VERSION "HNNBNNNYNNNNNNNNNNNNNNNNNNNNNNNNNNNNNNNNNN/4/%%%/4/'%**4NNN///"

NS_ :

BS_:

BU_: AFS Airbag Allrad BAP_Tester BMS_Hybrid Bremse_MK60EC Bremse_MK70MABS Bremse_TRW_EBC450M Bremse_TRW_ESP Daempfer EPB_TRW EPB_TRW_VW411CS FLA Gateway_PQ35 Gateway_Zusatz_EGolf Getriebe_AG6 Getriebe_DQ Getriebe_DQ_Hyb Getriebe_Sele Gurtmikro_PQ35 HCA Ladegeraet_EGolf LEH_Hybrid LH_EPS_APA LH_EPS_ZF_2G LH_EPS_ZF_3G LPG_Interface_Box LWR LWS Magne_Ride Motor_Diesel Motor_EGolf Motor_Hybrid Motor_Otto PDC_PLA Quersperre_VAQ RKA_Plus SAK Waehlhebel Waehlhebel_Sele

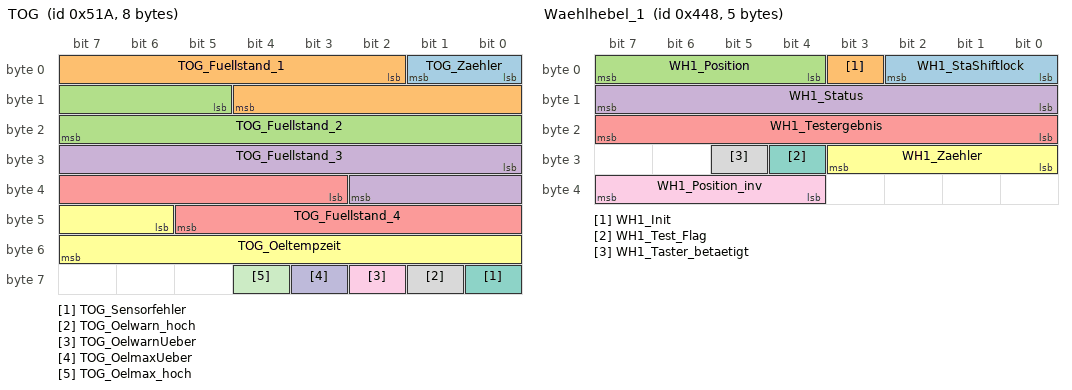
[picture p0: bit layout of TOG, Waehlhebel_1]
BO_ 1306 TOG: 8 Gateway_PQ35
 SG_ TOG_Zaehler : 0|2@1+ (1,0) [0|3] ""  Motor_Diesel,Motor_Hybrid,Motor_Otto
 SG_ TOG_Fuellstand_1 : 2|11@1+ (0.5,100) [101|1123] "Unit_MilliSecon"  Motor_Diesel,Motor_Hybrid,Motor_Otto
 SG_ TOG_Fuellstand_2 : 13|11@1+ (0.5,100) [101|1123] "Unit_MilliSecon"  Motor_Diesel,Motor_Hybrid,Motor_Otto
 SG_ TOG_Fuellstand_3 : 24|11@1+ (0.5,100) [101|1123] "Unit_MilliSecon"  Motor_Diesel,Motor_Hybrid,Motor_Otto
 SG_ TOG_Fuellstand_4 : 35|11@1+ (0.5,100) [101|1123] "Unit_MilliSecon"  Motor_Diesel,Motor_Hybrid,Motor_Otto
 SG_ TOG_Oeltempzeit : 46|10@1+ (0.125,0) [0.25|127] "Unit_MilliSecon"  Motor_Diesel,Motor_Hybrid,Motor_Otto
 SG_ TOG_Sensorfehler : 56|1@1+ (1,0) [0|1] ""  Motor_Diesel,Motor_Hybrid,Motor_Otto
 SG_ TOG_Oelwarn_hoch : 57|1@1+ (1,0) [0|1] ""  Motor_Diesel,Motor_Hybrid,Motor_Otto
 SG_ TOG_OelwarnUeber : 58|1@1+ (1,0) [0|1] "" Vector__XXX
 SG_ TOG_OelmaxUeber : 59|1@1+ (1,0) [0|1] "" Vector__XXX
 SG_ TOG_Oelmax_hoch : 60|1@1+ (1,0) [0|1] "" Vector__XXX

BO_ 1936 mTP_Dyn_ABS_1: 8 Gateway_PQ35
 SG_ TPDyn_ABS_1 : 0|64@1+ (1,0) [0|1.84467440737096E+019] ""  Bremse_MK60EC,Bremse_MK70MABS,Bremse_TRW_EBC450M,Bremse_TRW_ESP

BO_ 1937 mTP_Dyn_ABS_2: 8 Gateway_PQ35
 SG_ TPDyn_ABS_2 : 0|64@1+ (1,0) [0|1.84467440737096E+019] "" Vector__XXX

BO_ 1904 mTP_Dyn_ADR_1: 8 Gateway_PQ35
 SG_ TPDyn_ADR_1 : 0|64@1+ (1,0) [0|1.84467440737096E+019] "" Vector__XXX

BO_ 1896 mTP_Dyn_Airbag_1: 8 Gateway_PQ35
 SG_ TPDyn_Airbag_1 : 0|64@1+ (1,0) [0|1.84467440737096E+019] ""  Airbag

BO_ 1892 mTP_Dyn_Allrad_1: 8 Gateway_PQ35
 SG_ TPDyn_Allrad_1 : 0|64@1+ (1,0) [0|1.84467440737096E+019] ""  Allrad

BO_ 1906 mTP_Dyn_Daempfer_1: 8 Gateway_PQ35
 SG_ TPDyn_Daempfer_1 : 0|64@1+ (1,0) [0|1.84467440737096E+019] ""  Daempfer,Magne_Ride

BO_ 768 mTP_Dyn_Diag_1_1: 8 AFS
 SG_ TPDyn_Diag_1_1 : 0|64@1+ (1,0) [0|1.84467440737096E+019] ""  Gateway_PQ35

BO_ 769 mTP_Dyn_Diag_1_2: 8 AFS
 SG_ TPDyn_Diag_1_2 : 0|64@1+ (1,0) [0|1.84467440737096E+019] ""  Gateway_PQ35

BO_ 770 mTP_Dyn_Diag_1_3: 8 AFS
 SG_ TPDyn_Diag_1_3 : 0|64@1+ (1,0) [0|1.84467440737096E+019] ""  Gateway_PQ35

BO_ 771 mTP_Dyn_Diag_1_4: 8 AFS
 SG_ TPDyn_Diag_1_4 : 0|64@1+ (1,0) [0|1.84467440737096E+019] ""  Gateway_PQ35

BO_ 772 mTP_Dyn_Diag_1_5: 8 AFS
 SG_ TPDyn_Diag_1_5 : 0|64@1+ (1,0) [0|1.84467440737096E+019] ""  Gateway_PQ35

BO_ 773 mTP_Dyn_Diag_1_6: 8 AFS
 SG_ TPDyn_Diag_1_6 : 0|64@1+ (1,0) [0|1.84467440737096E+019] ""  Gateway_PQ35

BO_ 774 mTP_Dyn_Diag_1_7: 8 AFS
 SG_ TPDyn_Diag_1_7 : 0|64@1+ (1,0) [0|1.84467440737096E+019] ""  Gateway_PQ35

BO_ 775 mTP_Dyn_Diag_1_8: 8 AFS
 SG_ TPDyn_Diag_1_8 : 0|64@1+ (1,0) [0|1.84467440737096E+019] ""  Gateway_PQ35

BO_ 1940 mTP_Dyn_EPB_1: 8 Gateway_PQ35
 SG_ TPDyn_EPB_1 : 0|64@1+ (1,0) [0|1.84467440737096E+019] ""  EPB_TRW

BO_ 1864 mTP_Dyn_FLA_1: 8 Gateway_PQ35
 SG_ TPDyn_FLA_1 : 0|64@1+ (1,0) [0|1.84467440737096E+019] ""  FLA

BO_ 1888 mTP_Dyn_Getriebe_1: 8 Gateway_PQ35
 SG_ TPDyn_Getriebe_1 : 0|64@1+ (1,0) [0|1.84467440737096E+019] ""  Getriebe_AG6,Getriebe_DQ,Getriebe_DQ_Hyb,Getriebe_Sele

BO_ 1889 mTP_Dyn_Getriebe_2: 8 Gateway_PQ35
 SG_ TPDyn_Getriebe_2 : 0|64@1+ (1,0) [0|1.84467440737096E+019] ""  Getriebe_AG6,Getriebe_DQ,Getriebe_DQ_Hyb,Getriebe_Sele

BO_ 1956 mTP_Dyn_LDW_1: 8 Gateway_PQ35
 SG_ TPDyn_LDW_1 : 0|64@1+ (1,0) [0|1.84467440737096E+019] "" Vector__XXX

BO_ 1957 mTP_Dyn_LDW_2: 8 Gateway_PQ35
 SG_ TPDyn_LDW_2 : 0|64@1+ (1,0) [0|1.84467440737096E+019] ""  HCA

BO_ 1960 mTP_Dyn_Lenkhilfe_1: 8 Gateway_PQ35
 SG_ TPDyn_Lenkhilfe_1 : 0|64@1+ (1,0) [0|1.84467440737096E+019] ""  LH_EPS_APA,LH_EPS_ZF_2G

BO_ 1961 mTP_Dyn_Lenkhilfe_2: 8 Gateway_PQ35
 SG_ TPDyn_Lenkhilfe_2 : 0|64@1+ (1,0) [0|1.84467440737096E+019] ""  LH_EPS_APA,LH_EPS_ZF_2G

BO_ 1924 mTP_Dyn_LWR_1: 8 Gateway_PQ35
 SG_ TPDyn_Dyn_LWR_1 : 0|64@1+ (1,0) [0|1.84467440737096E+019] ""  AFS,LWR

BO_ 1925 mTP_Dyn_LWR_2: 8 Gateway_PQ35
 SG_ TPDyn_Dyn_LWR_2 : 0|64@1+ (1,0) [0|1.84467440737096E+019] ""  AFS,LWR

BO_ 1952 mTP_Dyn_LWS: 8 Gateway_PQ35
 SG_ TPDyn_LWS : 0|64@1+ (1,0) [0|1.84467440737096E+019] ""  LWS

BO_ 1856 mTP_Dyn_Motor_1: 8 Gateway_PQ35
 SG_ TPDyn_Motor_1 : 0|64@1+ (1,0) [0|1.84467440737096E+019] ""  Motor_Diesel,Motor_Hybrid,Motor_Otto

BO_ 1857 mTP_Dyn_Motor_2: 8 Gateway_PQ35
 SG_ TPDyn_Motor_2 : 0|64@1+ (1,0) [0|1.84467440737096E+019] ""  Motor_Diesel,Motor_Hybrid,Motor_Otto

BO_ 1858 mTP_Dyn_Motor_3: 8 Gateway_PQ35
 SG_ TPDyn_Motor_3 : 0|64@1+ (1,0) [0|1.84467440737096E+019] ""  Motor_Diesel,Motor_Hybrid,Motor_Otto

BO_ 1859 mTP_Dyn_Motor_4: 8 Gateway_PQ35
 SG_ TPDyn_Motor_4 : 0|64@1+ (1,0) [0|1.84467440737096E+019] ""  Motor_Diesel,Motor_Hybrid,Motor_Otto

BO_ 1978 mTP_Dyn_PLA_PDC: 8 Gateway_PQ35
 SG_ TPDyn_PLA_PDC : 0|64@1+ (1,0) [0|1.84467440737096E+019] ""  PDC_PLA

BO_ 1880 mTP_Dyn_Quersperre_1: 8 Vector__XXX
 SG_ TPDyn_Quersperre_1 : 0|64@1+ (1,0) [0|1.84467440737096E+019] ""  Quersperre_VAQ

BO_ 1881 mTP_Dyn_Quersperre_2: 8 Gateway_PQ35
 SG_ TPDyn_Quersperre_2 : 0|64@1+ (1,0) [0|1.84467440737096E+019] ""  Quersperre_VAQ

BO_ 1875 mTP_Dyn_RKA_Plus_2: 8 Gateway_PQ35
 SG_ TPDyn_RKA_Plus_2 : 0|64@1+ (1,0) [0|1.84467440737096E+019] ""  RKA_Plus

BO_ 515 mTP_Er_ABS: 7 Bremse_MK60EC
 SG_ ABS_TP_Er : 0|56@1+ (1,0) [0|7.20575940379279E+016] ""  Gateway_PQ35

BO_ 523 mTP_Er_ADR: 7 Vector__XXX
 SG_ ADR_TP_Er : 0|56@1+ (1,0) [0|7.20575940379279E+016] ""  Gateway_PQ35

BO_ 517 mTP_Er_Airbag: 7 Airbag
 SG_ Airbag_TP_Er : 0|56@1+ (1,0) [0|7.20575940379279E+016] ""  Gateway_PQ35

BO_ 522 mTP_Er_Allrad: 7 Allrad
 SG_ Allrad_TP_Er : 0|56@1+ (1,0) [0|7.20575940379279E+016] ""  Gateway_PQ35

BO_ 524 mTP_Er_Daempfer: 7 Daempfer
 SG_ Daempfer_TP_Er : 0|56@1+ (1,0) [0|7.20575940379279E+016] ""  Gateway_PQ35

BO_ 537 mTP_Er_EPB: 7 EPB_TRW
 SG_ EPB_TP_Er : 0|56@1+ (1,0) [0|7.20575940379279E+016] ""  Gateway_PQ35

BO_ 534 mTP_Er_FLA: 7 FLA
 SG_ FLA_TP_Er : 0|56@1+ (1,0) [0|7.20575940379279E+016] ""  Gateway_PQ35

BO_ 514 mTP_Er_Getriebe: 7 Getriebe_AG6
 SG_ Getriebe_TP_Er : 0|56@1+ (1,0) [0|7.20575940379279E+016] ""  Gateway_PQ35

BO_ 538 mTP_Er_LDW: 7 HCA
 SG_ LDW_TP_Er : 0|56@1+ (1,0) [0|7.20575940379279E+016] ""  Gateway_PQ35

BO_ 521 mTP_Er_Lenkhilfe: 7 LH_EPS_APA
 SG_ Lenkhilfe_TP_Er : 0|56@1+ (1,0) [0|7.20575940379279E+016] ""  Gateway_PQ35

BO_ 518 mTP_Er_LWR: 7 AFS
 SG_ Dyn_LWR_TP_Er : 0|56@1+ (1,0) [0|7.20575940379279E+016] ""  Gateway_PQ35

BO_ 531 mTP_Er_LWS: 7 LWS
 SG_ LWS_TP_Er : 0|56@1+ (1,0) [0|7.20575940379279E+016] ""  Gateway_PQ35

BO_ 513 mTP_Er_Motor: 7 Motor_Diesel
 SG_ Motor_TP_Er : 0|56@1+ (1,0) [0|7.20575940379279E+016] ""  Gateway_PQ35

BO_ 541 mTP_Er_PLA_PDC: 7 PDC_PLA
 SG_ PLA_PDC_TP_Er : 0|56@1+ (1,0) [0|7.20575940379279E+016] ""  Gateway_PQ35

BO_ 536 mTP_Er_Quersperre: 7 Quersperre_VAQ
 SG_ Quersperre_TP_Er : 0|56@1+ (1,0) [0|7.20575940379279E+016] ""  Gateway_PQ35

BO_ 520 mTP_Er_RKA_Plus: 7 RKA_Plus
 SG_ RKA_Plus_TP_Er : 0|56@1+ (1,0) [0|7.20575940379279E+016] ""  Gateway_PQ35

BO_ 512 mTP_Er_Tester: 7 Gateway_PQ35
 SG_ Tester_TP_Er : 0|56@1+ (1,0) [0|7.20575940379279E+016] ""  AFS,Airbag,Allrad,Bremse_MK60EC,Bremse_MK70MABS,Bremse_TRW_EBC450M,Bremse_TRW_ESP,Daempfer,EPB_TRW,FLA,Getriebe_AG6,Getriebe_DQ,Getriebe_DQ_Hyb,Getriebe_Sele,HCA,LH_EPS_APA,LH_EPS_ZF_2G,LWR,LWS,Magne_Ride,Motor_Diesel,Motor_Hybrid,Motor_Otto,PDC_PLA,Quersperre_VAQ,RKA_Plus

BO_ 1096 Waehlhebel_1: 5 Waehlhebel
 SG_ WH1_StaShiftlock : 0|3@1+ (1,0) [0|7] ""  Getriebe_DQ,Getriebe_DQ_Hyb,Motor_EGolf
 SG_ WH1_Init : 3|1@1+ (1,0) [0|1] ""  Getriebe_DQ,Getriebe_DQ_Hyb,Motor_EGolf
 SG_ WH1_Position : 4|4@1+ (1,0) [0|15] ""  Getriebe_DQ,Getriebe_DQ_Hyb,Motor_EGolf
 SG_ WH1_Status : 8|8@1+ (1,0) [0|255] ""  Getriebe_DQ,Getriebe_DQ_Hyb,Motor_EGolf
 SG_ WH1_Testergebnis : 16|8@1+ (1,0) [0|255] ""  Getriebe_DQ,Getriebe_DQ_Hyb,Motor_EGolf
 SG_ WH1_Zaehler : 24|4@1+ (1,0) [0|15] ""  Getriebe_DQ,Getriebe_DQ_Hyb,Motor_EGolf
 SG_ WH1_Test_Flag : 28|1@1+ (1,0) [0|1] ""  Getriebe_DQ,Getriebe_DQ_Hyb,Motor_EGolf
 SG_ WH1_Taster_betaetigt : 29|1@1+ (1,0) [0|1] ""  Motor_EGolf
 SG_ WH1_Position_inv : 36|4@1+ (1,0) [0|15] ""  Getriebe_DQ,Getriebe_DQ_Hyb,Motor_EGolf

BO_ 1102 Waehlhebel_2: 5 Waehlhebel_Sele
 SG_ WH2_Checksumme : 0|8@1+ (1,0) [0|255] ""  Getriebe_Sele
 SG_ WH2_Zaehler : 8|4@1+ (1,0) [0|15] ""  Getriebe_Sele
 SG_ WH2_Init : 12|1@1+ (1,0) [0|1] ""  Getriebe_Sele
 SG_ WH2_Test_Flag : 13|1@1+ (1,0) [0|1] ""  Getriebe_Sele
 SG_ WH2_Sport : 14|1@1+ (1,0) [0|1] ""  Getriebe_Sele
 SG_ WH2_Winter : 15|1@1+ (1,0) [0|1] ""  Getriebe_Sele
 SG_ WH2_Position : 16|3@1+ (1,0) [0|7] ""  Getriebe_Sele
 SG_ WH2_Ruhestromfehler : 23|1@1+ (1,0) [0|1] ""  Getriebe_Sele
 SG_ WH2_Sensorarray_Einfachfehler : 24|1@1+ (1,0) [0|1] ""  Getriebe_Sele
 SG_ WH2_Sensorarray_Mehrfachfehler : 25|1@1+ (1,0) [0|1] ""  Getriebe_Sele
 SG_ WH2_Fehler_Sporttaster : 26|1@1+ (1,0) [0|1] ""  Getriebe_Sele
 SG_ WH2_Fehler_Fahrstufenanzeige : 27|1@1+ (1,0) [0|1] ""  Getriebe_Sele
 SG_ WH2_Fehler_Spannungsversorgung : 28|1@1+ (1,0) [0|1] ""  Getriebe_Sele
 SG_ WH2_Timeout_Kombi_2 : 29|1@1+ (1,0) [0|1] ""  Getriebe_Sele
 SG_ WH2_Timeout_Getriebe_5 : 30|1@1+ (1,0) [0|1] ""  Getriebe_Sele
 SG_ WH2_Timeout_Gate_Komf_1 : 31|1@1+ (1,0) [0|1] ""  Getriebe_Sele
 SG_ WH2_Testergebnis : 32|8@1+ (1,0) [0|255] ""  Getriebe_Sele

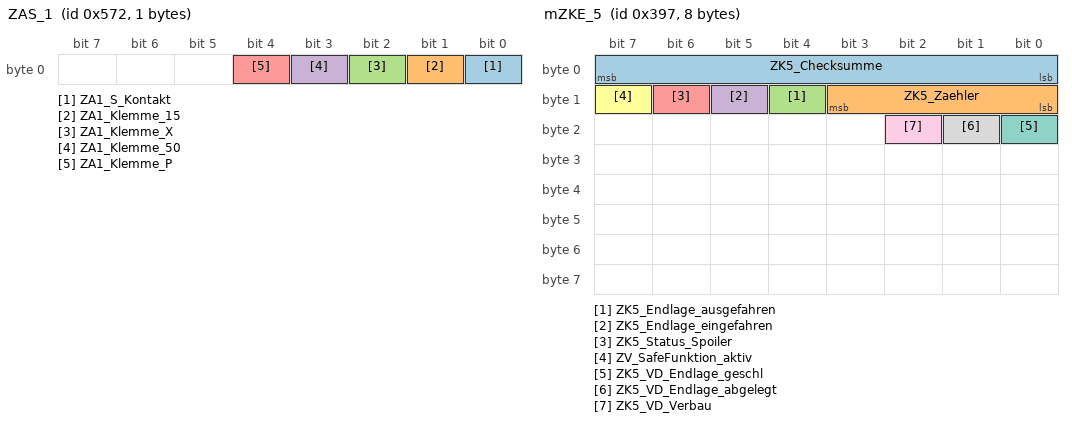
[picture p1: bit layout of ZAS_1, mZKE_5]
BO_ 1394 ZAS_1: 1 Gateway_PQ35
 SG_ ZA1_S_Kontakt : 0|1@1+ (1,0) [0|1] "" Vector__XXX
 SG_ ZA1_Klemme_15 : 1|1@1+ (1,0) [0|1] ""  Motor_Hybrid,Motor_Otto,PDC_PLA
 SG_ ZA1_Klemme_X : 2|1@1+ (1,0) [0|1] ""  Motor_Diesel,PDC_PLA
 SG_ ZA1_Klemme_50 : 3|1@1+ (1,0) [0|1] ""  Motor_Diesel,Motor_Hybrid,Motor_Otto
 SG_ ZA1_Klemme_P : 4|1@1+ (1,0) [0|1] "" Vector__XXX

BO_ 919 mZKE_5: 8 Gateway_PQ35
 SG_ ZK5_Checksumme : 0|8@1+ (1,0) [0|255] ""  Bremse_MK60EC
 SG_ ZK5_Zaehler : 8|4@1+ (1,0) [0|15] ""  Bremse_MK60EC
 SG_ ZK5_Endlage_ausgefahren : 12|1@1+ (1,0) [0|1] ""  Bremse_MK60EC
 SG_ ZK5_Endlage_eingefahren : 13|1@1+ (1,0) [0|1] ""  Bremse_MK60EC
 SG_ ZK5_Status_Spoiler : 14|1@1+ (1,0) [0|1] ""  Bremse_MK60EC
 SG_ ZV_SafeFunktion_aktiv : 15|1@1+ (1,0) [0|1] "" Vector__XXX
 SG_ ZK5_VD_Endlage_geschl : 16|1@1+ (1,0) [0|1] ""  Bremse_MK60EC,PDC_PLA
 SG_ ZK5_VD_Endlage_abgelegt : 17|1@1+ (1,0) [0|1] ""  Bremse_MK60EC,PDC_PLA
 SG_ ZK5_VD_Verbau : 18|1@1+ (1,0) [0|1] ""  Bremse_MK60EC,PDC_PLA

BO_ 1827 NMH_ABS: 7 Bremse_MK60EC
 SG_ NMH_ABS_Start_1 : 0|1@1+ (1,0) [0|1] ""  BMS_Hybrid,Bremse_MK60EC,Bremse_MK70MABS,Bremse_TRW_EBC450M,Bremse_TRW_ESP,EPB_TRW_VW411CS,Gateway_PQ35,Ladegeraet_EGolf,LEH_Hybrid,Motor_Diesel,Motor_EGolf,Motor_Hybrid,Motor_Otto
 SG_ NMH_ABS_Start_2 : 1|1@1+ (1,0) [0|1] "" Vector__XXX
 SG_ NMH_ABS_Normal_Mode_1 : 2|1@1+ (1,0) [0|1] "" Vector__XXX
 SG_ NMH_ABS_Normal_Mode_2 : 3|1@1+ (1,0) [0|1] "" Vector__XXX
 SG_ NMH_ABS_Car_WakeUp : 6|1@1+ (1,0) [0|1] "" Vector__XXX
 SG_ NMH_ABS_Per_WakeUp : 8|5@1+ (1,0) [0|31] "" Vector__XXX
 SG_ NMH_ABS_Fkt_WakeUp : 13|3@1+ (1,0) [0|7] "" Vector__XXX
 SG_ NMH_ABS_NM_aktiv_Klemme_15 : 16|1@1+ (1,0) [0|1] "" Vector__XXX
 SG_ NMH_ABS_NM_aktiv_Diagnose : 17|1@1+ (1,0) [0|1] "" Vector__XXX
 SG_ NMH_ABS_NM_aktiv_Start : 18|1@1+ (1,0) [0|1] "" Vector__XXX
 SG_ NMH_ABS_NL_aktiv_4 : 19|1@1+ (1,0) [0|1] "" Vector__XXX
 SG_ NMH_ABS_NL_aktiv_5 : 20|1@1+ (1,0) [0|1] "" Vector__XXX
 SG_ NMH_ABS_NL_aktiv_6 : 21|1@1+ (1,0) [0|1] "" Vector__XXX
 SG_ NMH_ABS_NL_aktiv_7 : 22|1@1+ (1,0) [0|1] "" Vector__XXX
 SG_ NMH_ABS_NL_aktiv_8 : 23|1@1+ (1,0) [0|1] "" Vector__XXX
 SG_ NMH_ABS_NL_0 : 24|1@1+ (1,0) [0|1] "" Vector__XXX
 SG_ NMH_ABS_NL_1 : 25|1@1+ (1,0) [0|1] "" Vector__XXX
 SG_ NMH_ABS_NL_2 : 26|1@1+ (1,0) [0|1] "" Vector__XXX
 SG_ NMH_ABS_NL_3 : 27|1@1+ (1,0) [0|1] "" Vector__XXX
 SG_ NMH_ABS_NL_4 : 28|1@1+ (1,0) [0|1] "" Vector__XXX
 SG_ NMH_ABS_NL_5 : 29|1@1+ (1,0) [0|1] "" Vector__XXX
 SG_ NMH_ABS_NL_6 : 30|1@1+ (1,0) [0|1] "" Vector__XXX
 SG_ NMH_ABS_NL_7 : 31|1@1+ (1,0) [0|1] "" Vector__XXX
 SG_ NMH_ABS_TimeOut_Fehler : 33|1@1+ (1,0) [0|1] "" Vector__XXX
 SG_ NMH_ABS_CAN_Diag_deaktiv : 34|1@1+ (1,0) [0|1] "" Vector__XXX
 SG_ NMH_ABS_KompSchutz : 35|1@1+ (1,0) [0|1] "" Vector__XXX
 SG_ NMH_ABS_Mute_Mode : 36|1@1+ (1,0) [0|1] "" Vector__XXX
 SG_ NMH_ABS_Transport_Mode : 37|1@1+ (1,0) [0|1] "" Vector__XXX
 SG_ NMH_ABS_Abschaltstufe_aktiv : 38|1@1+ (1,0) [0|1] "" Vector__XXX
 SG_ NMH_ABS_Eindraht_Fehler : 39|1@1+ (1,0) [0|1] "" Vector__XXX

BO_ 1838 NMH_BMS: 7 BMS_Hybrid
 SG_ NMH_BMS_Start_1 : 0|1@1+ (1,0) [0|1] ""  BMS_Hybrid,Bremse_MK60EC,Bremse_MK70MABS,Bremse_TRW_EBC450M,Bremse_TRW_ESP,EPB_TRW_VW411CS,Gateway_PQ35,Ladegeraet_EGolf,LEH_Hybrid,Motor_Diesel,Motor_EGolf,Motor_Hybrid,Motor_Otto
 SG_ NMH_BMS_Start_2 : 1|1@1+ (1,0) [0|1] "" Vector__XXX
 SG_ NMH_BMS_Normal_Mode_1 : 2|1@1+ (1,0) [0|1] "" Vector__XXX
 SG_ NMH_BMS_Normal_Mode_2 : 3|1@1+ (1,0) [0|1] "" Vector__XXX
 SG_ NMH_BMS_Car_WakeUp : 6|1@1+ (1,0) [0|1] "" Vector__XXX
 SG_ NMH_BMS_Per_WakeUp : 8|5@1+ (1,0) [0|31] "" Vector__XXX
 SG_ NMH_BMS_Fkt_WakeUp : 13|3@1+ (1,0) [0|7] "" Vector__XXX
 SG_ NMH_BMS_NM_aktiv_Klemme_15 : 16|1@1+ (1,0) [0|1] "" Vector__XXX
 SG_ NMH_BMS_NM_aktiv_Diagnose : 17|1@1+ (1,0) [0|1] "" Vector__XXX
 SG_ NMH_BMS_NM_aktiv_Start : 18|1@1+ (1,0) [0|1] "" Vector__XXX
 SG_ NMH_BMS_NL_aktiv_4 : 19|1@1+ (1,0) [0|1] "" Vector__XXX
 SG_ NMH_BMS_NL_aktiv_5 : 20|1@1+ (1,0) [0|1] "" Vector__XXX
 SG_ NMH_BMS_NL_aktiv_6 : 21|1@1+ (1,0) [0|1] "" Vector__XXX
 SG_ NMH_BMS_NL_aktiv_7 : 22|1@1+ (1,0) [0|1] "" Vector__XXX
 SG_ NMH_BMS_NL_aktiv_8 : 23|1@1+ (1,0) [0|1] "" Vector__XXX
 SG_ NMH_BMS_NL_0 : 24|1@1+ (1,0) [0|1] "" Vector__XXX
 SG_ NMH_BMS_NL_1 : 25|1@1+ (1,0) [0|1] "" Vector__XXX
 SG_ NMH_BMS_NL_2 : 26|1@1+ (1,0) [0|1] "" Vector__XXX
 SG_ NMH_BMS_NL_3 : 27|1@1+ (1,0) [0|1] "" Vector__XXX
 SG_ NMH_BMS_NL_4 : 28|1@1+ (1,0) [0|1] "" Vector__XXX
 SG_ NMH_BMS_NL_5 : 29|1@1+ (1,0) [0|1] "" Vector__XXX
 SG_ NMH_BMS_NL_6 : 30|1@1+ (1,0) [0|1] "" Vector__XXX
 SG_ NMH_BMS_NL_7 : 31|1@1+ (1,0) [0|1] "" Vector__XXX
 SG_ NMH_BMS_TimeOut_Fehler : 33|1@1+ (1,0) [0|1] "" Vector__XXX
 SG_ NMH_BMS_CAN_Diag_deaktiv : 34|1@1+ (1,0) [0|1] "" Vector__XXX
 SG_ NMH_BMS_KompSchutz : 35|1@1+ (1,0) [0|1] "" Vector__XXX
 SG_ NMH_BMS_Mute_Mode : 36|1@1+ (1,0) [0|1] "" Vector__XXX
 SG_ NMH_BMS_Transport_Mode : 37|1@1+ (1,0) [0|1] "" Vector__XXX
 SG_ NMH_BMS_Abschaltstufe_aktiv : 38|1@1+ (1,0) [0|1] "" Vector__XXX
 SG_ NMH_BMS_Eindraht_Fehler : 39|1@1+ (1,0) [0|1] "" Vector__XXX

BO_ 1839 NMH_EM: 7 LEH_Hybrid
 SG_ NMH_EM_Start_1 : 0|1@1+ (1,0) [0|1] ""  BMS_Hybrid,Bremse_MK60EC,Bremse_MK70MABS,Bremse_TRW_EBC450M,Bremse_TRW_ESP,EPB_TRW_VW411CS,Gateway_PQ35,Ladegeraet_EGolf,LEH_Hybrid,Motor_Diesel,Motor_EGolf,Motor_Hybrid,Motor_Otto
 SG_ NMH_EM_Start_2 : 1|1@1+ (1,0) [0|1] "" Vector__XXX
 SG_ NMH_EM_Normal_Mode_1 : 2|1@1+ (1,0) [0|1] "" Vector__XXX
 SG_ NMH_EM_Normal_Mode_2 : 3|1@1+ (1,0) [0|1] "" Vector__XXX
 SG_ NMH_EM_Car_WakeUp : 6|1@1+ (1,0) [0|1] "" Vector__XXX
 SG_ NMH_EM_Per_WakeUp : 8|5@1+ (1,0) [0|31] "" Vector__XXX
 SG_ NMH_EM_Fkt_WakeUp : 13|3@1+ (1,0) [0|7] "" Vector__XXX
 SG_ NMH_EM_NM_aktiv_Klemme_15 : 16|1@1+ (1,0) [0|1] "" Vector__XXX
 SG_ NMH_EM_NM_aktiv_Diagnose : 17|1@1+ (1,0) [0|1] "" Vector__XXX
 SG_ NMH_EM_NM_aktiv_Start : 18|1@1+ (1,0) [0|1] "" Vector__XXX
 SG_ NMH_EM_NL_aktiv_4 : 19|1@1+ (1,0) [0|1] "" Vector__XXX
 SG_ NMH_EM_NL_aktiv_5 : 20|1@1+ (1,0) [0|1] "" Vector__XXX
 SG_ NMH_EM_NL_aktiv_6 : 21|1@1+ (1,0) [0|1] "" Vector__XXX
 SG_ NMH_EM_NL_aktiv_7 : 22|1@1+ (1,0) [0|1] "" Vector__XXX
 SG_ NMH_EM_NL_aktiv_8 : 23|1@1+ (1,0) [0|1] "" Vector__XXX
 SG_ NMH_EM_NL_0 : 24|1@1+ (1,0) [0|1] "" Vector__XXX
 SG_ NMH_EM_NL_1 : 25|1@1+ (1,0) [0|1] "" Vector__XXX
 SG_ NMH_EM_NL_2 : 26|1@1+ (1,0) [0|1] "" Vector__XXX
 SG_ NMH_EM_NL_3 : 27|1@1+ (1,0) [0|1] "" Vector__XXX
 SG_ NMH_EM_NL_4 : 28|1@1+ (1,0) [0|1] "" Vector__XXX
 SG_ NMH_EM_NL_5 : 29|1@1+ (1,0) [0|1] "" Vector__XXX
 SG_ NMH_EM_NL_6 : 30|1@1+ (1,0) [0|1] "" Vector__XXX
 SG_ NMH_EM_NL_7 : 31|1@1+ (1,0) [0|1] "" Vector__XXX
 SG_ NMH_EM_TimeOut_Fehler : 33|1@1+ (1,0) [0|1] "" Vector__XXX
 SG_ NMH_EM_CAN_Diag_deaktiv : 34|1@1+ (1,0) [0|1] "" Vector__XXX
 SG_ NMH_EM_KompSchutz : 35|1@1+ (1,0) [0|1] "" Vector__XXX
 SG_ NMH_EM_Mute_Mode : 36|1@1+ (1,0) [0|1] "" Vector__XXX
 SG_ NMH_EM_Transport_Mode : 37|1@1+ (1,0) [0|1] "" Vector__XXX
 SG_ NMH_EM_Abschaltstufe_aktiv : 38|1@1+ (1,0) [0|1] "" Vector__XXX
 SG_ NMH_EM_Eindraht_Fehler : 39|1@1+ (1,0) [0|1] "" Vector__XXX

BO_ 1849 NMH_EPB: 7 EPB_TRW_VW411CS
 SG_ NMH_EPB_Start_1 : 0|1@1+ (1,0) [0|1] ""  BMS_Hybrid,Bremse_MK60EC,Bremse_MK70MABS,Bremse_TRW_EBC450M,Bremse_TRW_ESP,EPB_TRW_VW411CS,Gateway_PQ35,Ladegeraet_EGolf,LEH_Hybrid,Motor_Diesel,Motor_EGolf,Motor_Hybrid,Motor_Otto
 SG_ NMH_EPB_Start_2 : 1|1@1+ (1,0) [0|1] "" Vector__XXX
 SG_ NMH_EPB_Normal_Mode_1 : 2|1@1+ (1,0) [0|1] "" Vector__XXX
 SG_ NMH_EPB_Normal_Mode_2 : 3|1@1+ (1,0) [0|1] "" Vector__XXX
 SG_ NMH_EPB_Car_WakeUp : 6|1@1+ (1,0) [0|1] "" Vector__XXX
 SG_ NMH_EPB_Per_WakeUp : 8|5@1+ (1,0) [0|31] "" Vector__XXX
 SG_ NMH_EPB_Fkt_WakeUp : 13|3@1+ (1,0) [0|7] "" Vector__XXX
 SG_ NMH_EPB_NM_aktiv_Klemme_15 : 16|1@1+ (1,0) [0|1] "" Vector__XXX
 SG_ NMH_EPB_NM_aktiv_Diagnose : 17|1@1+ (1,0) [0|1] "" Vector__XXX
 SG_ NMH_EPB_NM_aktiv_Start : 18|1@1+ (1,0) [0|1] "" Vector__XXX
 SG_ NMH_EPB_NL_aktiv_4 : 19|1@1+ (1,0) [0|1] "" Vector__XXX
 SG_ NMH_EPB_NL_aktiv_5 : 20|1@1+ (1,0) [0|1] "" Vector__XXX
 SG_ NMH_EPB_NL_aktiv_6 : 21|1@1+ (1,0) [0|1] "" Vector__XXX
 SG_ NMH_EPB_NL_aktiv_7 : 22|1@1+ (1,0) [0|1] "" Vector__XXX
 SG_ NMH_EPB_NL_aktiv_8 : 23|1@1+ (1,0) [0|1] "" Vector__XXX
 SG_ NMH_EPB_NL_0 : 24|1@1+ (1,0) [0|1] "" Vector__XXX
 SG_ NMH_EPB_NL_1 : 25|1@1+ (1,0) [0|1] "" Vector__XXX
 SG_ NMH_EPB_NL_2 : 26|1@1+ (1,0) [0|1] "" Vector__XXX
 SG_ NMH_EPB_NL_3 : 27|1@1+ (1,0) [0|1] "" Vector__XXX
 SG_ NMH_EPB_NL_4 : 28|1@1+ (1,0) [0|1] "" Vector__XXX
 SG_ NMH_EPB_NL_5 : 29|1@1+ (1,0) [0|1] "" Vector__XXX
 SG_ NMH_EPB_NL_6 : 30|1@1+ (1,0) [0|1] "" Vector__XXX
 SG_ NMH_EPB_NL_7 : 31|1@1+ (1,0) [0|1] "" Vector__XXX
 SG_ NMH_EPB_TimeOut_Fehler : 33|1@1+ (1,0) [0|1] "" Vector__XXX
 SG_ NMH_EPB_CAN_Diag_deaktiv : 34|1@1+ (1,0) [0|1] "" Vector__XXX
 SG_ NMH_EPB_KompSchutz : 35|1@1+ (1,0) [0|1] "" Vector__XXX
 SG_ NMH_EPB_Mute_Mode : 36|1@1+ (1,0) [0|1] "" Vector__XXX
 SG_ NMH_EPB_Transport_Mode : 37|1@1+ (1,0) [0|1] "" Vector__XXX
 SG_ NMH_EPB_Abschaltstufe_aktiv : 38|1@1+ (1,0) [0|1] "" Vector__XXX
 SG_ NMH_EPB_Eindraht_Fehler : 39|1@1+ (1,0) [0|1] "" Vector__XXX

BO_ 1824 NMH_Gateway: 7 Gateway_PQ35
 SG_ NMH_GW_Start_1 : 0|1@1+ (1,0) [0|1] ""  BMS_Hybrid,Bremse_MK60EC,Bremse_MK70MABS,Bremse_TRW_EBC450M,Bremse_TRW_ESP,EPB_TRW_VW411CS,Gateway_PQ35,Ladegeraet_EGolf,LEH_Hybrid,Motor_Diesel,Motor_EGolf,Motor_Hybrid,Motor_Otto
 SG_ NMH_GW_Start_2 : 1|1@1+ (1,0) [0|1] "" Vector__XXX
 SG_ NMH_GW_Normal_Mode_1 : 2|1@1+ (1,0) [0|1] "" Vector__XXX
 SG_ NMH_GW_Normal_Mode_2 : 3|1@1+ (1,0) [0|1] "" Vector__XXX
 SG_ NMH_GW_Car_WakeUp : 6|1@1+ (1,0) [0|1] "" Vector__XXX
 SG_ NMH_GW_Per_WakeUp : 8|5@1+ (1,0) [0|31] "" Vector__XXX
 SG_ NMH_GW_Fkt_WakeUp : 13|3@1+ (1,0) [0|7] "" Vector__XXX
 SG_ NMH_GW_NM_aktiv_Klemme_15 : 16|1@1+ (1,0) [0|1] "" Vector__XXX
 SG_ NMH_GW_NM_aktiv_Diagnose : 17|1@1+ (1,0) [0|1] "" Vector__XXX
 SG_ NMH_GW_NM_aktiv_Start : 18|1@1+ (1,0) [0|1] "" Vector__XXX
 SG_ NMH_GW_NL_aktiv_4 : 19|1@1+ (1,0) [0|1] "" Vector__XXX
 SG_ NMH_GW_NL_aktiv_5 : 20|1@1+ (1,0) [0|1] "" Vector__XXX
 SG_ NMH_GW_NL_aktiv_6 : 21|1@1+ (1,0) [0|1] "" Vector__XXX
 SG_ NMH_GW_NL_aktiv_7 : 22|1@1+ (1,0) [0|1] "" Vector__XXX
 SG_ NMH_GW_NL_aktiv_8 : 23|1@1+ (1,0) [0|1] "" Vector__XXX
 SG_ NMH_GW_NL_0 : 24|1@1+ (1,0) [0|1] "" Vector__XXX
 SG_ NMH_GW_NL_1 : 25|1@1+ (1,0) [0|1] "" Vector__XXX
 SG_ NMH_GW_NL_2 : 26|1@1+ (1,0) [0|1] "" Vector__XXX
 SG_ NMH_GW_NL_3 : 27|1@1+ (1,0) [0|1] "" Vector__XXX
 SG_ NMH_GW_NL_4 : 28|1@1+ (1,0) [0|1] "" Vector__XXX
 SG_ NMH_GW_NL_5 : 29|1@1+ (1,0) [0|1] "" Vector__XXX
 SG_ NMH_GW_NL_6 : 30|1@1+ (1,0) [0|1] "" Vector__XXX
 SG_ NMH_GW_NL_7 : 31|1@1+ (1,0) [0|1] "" Vector__XXX
 SG_ NMH_GW_TimeOut_Fehler : 33|1@1+ (1,0) [0|1] "" Vector__XXX
 SG_ NMH_GW_CAN_Diag_deaktiv : 34|1@1+ (1,0) [0|1] "" Vector__XXX
 SG_ NMH_GW_KompSchutz : 35|1@1+ (1,0) [0|1] "" Vector__XXX
 SG_ NMH_GW_Mute_Mode : 36|1@1+ (1,0) [0|1] "" Vector__XXX
 SG_ NMH_GW_Transport_Mode : 37|1@1+ (1,0) [0|1] "" Vector__XXX
 SG_ NMH_GW_Abschaltstufe_aktiv : 38|1@1+ (1,0) [0|1] "" Vector__XXX
 SG_ NMH_GW_Eindraht_Fehler : 39|1@1+ (1,0) [0|1] "" Vector__XXX

BO_ 1836 NMH_Ladegeraet: 7 Ladegeraet_EGolf
 SG_ NMH_Ladegeraet_Start_1 : 0|1@1+ (1,0) [0|1] ""  BMS_Hybrid,Bremse_MK60EC,Bremse_MK70MABS,Bremse_TRW_EBC450M,Bremse_TRW_ESP,EPB_TRW_VW411CS,Gateway_PQ35,Ladegeraet_EGolf,LEH_Hybrid,Motor_Diesel,Motor_EGolf,Motor_Hybrid,Motor_Otto
 SG_ NMH_Ladegeraet_Start_2 : 1|1@1+ (1,0) [0|1] "" Vector__XXX
 SG_ NMH_Ladegeraet_Normal_Mode_1 : 2|1@1+ (1,0) [0|1] "" Vector__XXX
 SG_ NMH_Ladegeraet_Normal_Mode_2 : 3|1@1+ (1,0) [0|1] "" Vector__XXX
 SG_ NMH_Ladegeraet_Car_WakeUp : 6|1@1+ (1,0) [0|1] "" Vector__XXX
 SG_ NMH_Ladegeraet_Per_WakeUp : 8|5@1+ (1,0) [0|31] "" Vector__XXX
 SG_ NMH_Ladegeraet_Fkt_WakeUp : 13|3@1+ (1,0) [0|7] "" Vector__XXX
 SG_ NMH_Ladegeraet_NM_aktiv_Klemm000 : 16|1@1+ (1,0) [0|1] "" Vector__XXX
 SG_ NMH_Ladegeraet_NM_aktiv_Diagnose : 17|1@1+ (1,0) [0|1] "" Vector__XXX
 SG_ NMH_Ladegeraet_NM_aktiv_Start : 18|1@1+ (1,0) [0|1] "" Vector__XXX
 SG_ NMH_Ladegeraet_NL_aktiv_4 : 19|1@1+ (1,0) [0|1] "" Vector__XXX
 SG_ NMH_Ladegeraet_NL_aktiv_5 : 20|1@1+ (1,0) [0|1] "" Vector__XXX
 SG_ NMH_Ladegeraet_NL_aktiv_6 : 21|1@1+ (1,0) [0|1] "" Vector__XXX
 SG_ NMH_Ladegeraet_NL_aktiv_7 : 22|1@1+ (1,0) [0|1] "" Vector__XXX
 SG_ NMH_Ladegeraet_NL_aktiv_8 : 23|1@1+ (1,0) [0|1] "" Vector__XXX
 SG_ NMH_Ladegeraet_NL_0 : 24|1@1+ (1,0) [0|1] "" Vector__XXX
 SG_ NMH_Ladegeraet_NL_1 : 25|1@1+ (1,0) [0|1] "" Vector__XXX
 SG_ NMH_Ladegeraet_NL_2 : 26|1@1+ (1,0) [0|1] "" Vector__XXX
 SG_ NMH_Ladegeraet_NL_3 : 27|1@1+ (1,0) [0|1] "" Vector__XXX
 SG_ NMH_Ladegeraet_NL_4 : 28|1@1+ (1,0) [0|1] "" Vector__XXX
 SG_ NMH_Ladegeraet_NL_5 : 29|1@1+ (1,0) [0|1] "" Vector__XXX
 SG_ NMH_Ladegeraet_NL_6 : 30|1@1+ (1,0) [0|1] "" Vector__XXX
 SG_ NMH_Ladegeraet_NL_7 : 31|1@1+ (1,0) [0|1] "" Vector__XXX
 SG_ NMH_Ladegeraet_TimeOut_Fehler : 33|1@1+ (1,0) [0|1] "" Vector__XXX
 SG_ NMH_Ladegeraet_CAN_Diag_deaktiv : 34|1@1+ (1,0) [0|1] "" Vector__XXX
 SG_ NMH_Ladegeraet_KompSchutz : 35|1@1+ (1,0) [0|1] "" Vector__XXX
 SG_ NMH_Ladegeraet_Mute_Mode : 36|1@1+ (1,0) [0|1] "" Vector__XXX
 SG_ NMH_Ladegeraet_Transport_Mode : 37|1@1+ (1,0) [0|1] "" Vector__XXX
 SG_ NMH_Ladegeraet_Abschaltstufe_001 : 38|1@1+ (1,0) [0|1] "" Vector__XXX
 SG_ NMH_Ladegeraet_Eindraht_Fehler : 39|1@1+ (1,0) [0|1] "" Vector__XXX

BO_ 1825 NMH_Motor: 7 Motor_Diesel
 SG_ NMH_MO_Start_1 : 0|1@1+ (1,0) [0|1] ""  BMS_Hybrid,Bremse_MK60EC,Bremse_MK70MABS,Bremse_TRW_EBC450M,Bremse_TRW_ESP,EPB_TRW_VW411CS,Gateway_PQ35,Ladegeraet_EGolf,LEH_Hybrid,Motor_Diesel,Motor_EGolf,Motor_Hybrid,Motor_Otto
 SG_ NMH_MO_Start_2 : 1|1@1+ (1,0) [0|1] "" Vector__XXX
 SG_ NMH_MO_Normal_Mode_1 : 2|1@1+ (1,0) [0|1] "" Vector__XXX
 SG_ NMH_MO_Normal_Mode_2 : 3|1@1+ (1,0) [0|1] "" Vector__XXX
 SG_ NMH_MO_Car_WakeUp : 6|1@1+ (1,0) [0|1] "" Vector__XXX
 SG_ NMH_MO_Per_WakeUp : 8|5@1+ (1,0) [0|31] "" Vector__XXX
 SG_ NMH_MO_Fkt_WakeUp : 13|3@1+ (1,0) [0|7] "" Vector__XXX
 SG_ NMH_MO_NM_aktiv_Klemme_15 : 16|1@1+ (1,0) [0|1] "" Vector__XXX
 SG_ NMH_MO_NM_aktiv_Diagnose : 17|1@1+ (1,0) [0|1] "" Vector__XXX
 SG_ NMH_MO_NM_aktiv_Start : 18|1@1+ (1,0) [0|1] "" Vector__XXX
 SG_ NMH_MO_NL_aktiv_4 : 19|1@1+ (1,0) [0|1] "" Vector__XXX
 SG_ NMH_MO_NL_aktiv_5 : 20|1@1+ (1,0) [0|1] "" Vector__XXX
 SG_ NMH_MO_NL_aktiv_6 : 21|1@1+ (1,0) [0|1] "" Vector__XXX
 SG_ NMH_MO_NL_aktiv_7 : 22|1@1+ (1,0) [0|1] "" Vector__XXX
 SG_ NMH_MO_NL_aktiv_8 : 23|1@1+ (1,0) [0|1] "" Vector__XXX
 SG_ NMH_MO_NL_0 : 24|1@1+ (1,0) [0|1] "" Vector__XXX
 SG_ NMH_MO_NL_1 : 25|1@1+ (1,0) [0|1] "" Vector__XXX
 SG_ NMH_MO_NL_2 : 26|1@1+ (1,0) [0|1] "" Vector__XXX
 SG_ NMH_MO_NL_3 : 27|1@1+ (1,0) [0|1] "" Vector__XXX
 SG_ NMH_MO_NL_4 : 28|1@1+ (1,0) [0|1] "" Vector__XXX
 SG_ NMH_MO_NL_5 : 29|1@1+ (1,0) [0|1] "" Vector__XXX
 SG_ NMH_MO_NL_6 : 30|1@1+ (1,0) [0|1] "" Vector__XXX
 SG_ NMH_MO_NL_7 : 31|1@1+ (1,0) [0|1] "" Vector__XXX
 SG_ NMH_MO_TimeOut_Fehler : 33|1@1+ (1,0) [0|1] "" Vector__XXX
 SG_ NMH_MO_CAN_Diag_deaktiv : 34|1@1+ (1,0) [0|1] "" Vector__XXX
 SG_ NMH_MO_KompSchutz : 35|1@1+ (1,0) [0|1] "" Vector__XXX
 SG_ NMH_MO_Mute_Mode : 36|1@1+ (1,0) [0|1] "" Vector__XXX
 SG_ NMH_MO_Transport_Mode : 37|1@1+ (1,0) [0|1] "" Vector__XXX
 SG_ NMH_MO_Abschaltstufe_aktiv : 38|1@1+ (1,0) [0|1] "" Vector__XXX
 SG_ NMH_MO_Eindraht_Fehler : 39|1@1+ (1,0) [0|1] "" Vector__XXX

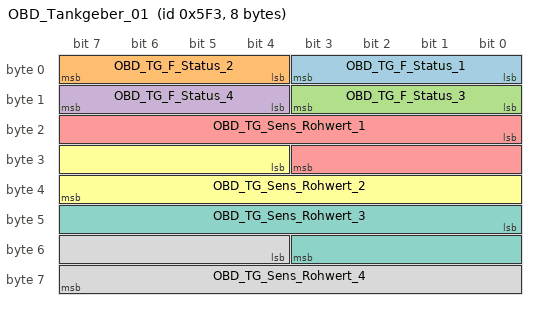
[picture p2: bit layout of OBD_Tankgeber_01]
BO_ 1523 OBD_Tankgeber_01: 8 Gateway_PQ35
 SG_ OBD_TG_F_Status_1 : 0|4@1+ (1,0) [0|15] ""  Motor_Otto
 SG_ OBD_TG_F_Status_2 : 4|4@1+ (1,0) [0|15] ""  Motor_Otto
 SG_ OBD_TG_F_Status_3 : 8|4@1+ (1,0) [0|15] ""  Motor_Otto
 SG_ OBD_TG_F_Status_4 : 12|4@1+ (1,0) [0|15] ""  Motor_Otto
 SG_ OBD_TG_Sens_Rohwert_1 : 16|12@1+ (0.5,0) [0|2047.5] "Unit_Ohm"  Motor_Otto
 SG_ OBD_TG_Sens_Rohwert_2 : 28|12@1+ (0.5,0) [0|2047.5] "Unit_Ohm"  Motor_Otto
 SG_ OBD_TG_Sens_Rohwert_3 : 40|12@1+ (0.5,0) [0|2047.5] "Unit_Ohm"  Motor_Otto
 SG_ OBD_TG_Sens_Rohwert_4 : 52|12@1+ (0.5,0) [0|2047.5] "Unit_Ohm"  Motor_Otto

BO_ 1175 Parkhilfe_01: 8 PDC_PLA
 SG_ PH_Abschaltursache : 13|3@1+ (1,0) [0|7] ""  Gateway_PQ35
 SG_ PH_Opt_Anzeige_V_ein : 16|1@1+ (1,0) [0|1] ""  Gateway_PQ35
 SG_ PH_Opt_Anzeige_H_ein : 17|1@1+ (1,0) [0|1] ""  Gateway_PQ35
 SG_ PH_Opt_Anz_V_Hindernis : 18|1@1+ (1,0) [0|1] ""  Gateway_PQ35
 SG_ PH_Opt_Anz_H_Hindernis : 19|1@1+ (1,0) [0|1] ""  Gateway_PQ35
 SG_ PH_Tongeber_V_aktiv : 20|1@1+ (1,0) [0|1] ""  Gateway_PQ35
 SG_ PH_Tongeber_H_aktiv : 21|1@1+ (1,0) [0|1] ""  Gateway_PQ35
 SG_ PH_Tongeber_mute : 22|1@1+ (1,0) [0|1] ""  Gateway_PQ35
 SG_ PH_Anf_Audioabsenkung : 23|1@1+ (1,0) [0|1] ""  Gateway_PQ35
 SG_ PH_Anf_Verdeck : 30|2@1+ (1,0) [0|3] ""  Gateway_PQ35
 SG_ PH_Frequenz_hinten : 32|4@1+ (1,0) [0|15] ""  Gateway_PQ35
 SG_ PH_Lautstaerke_hinten : 36|4@1+ (1,0) [0|15] ""  Gateway_PQ35
 SG_ PH_Frequenz_vorn : 40|4@1+ (1,0) [0|15] ""  Gateway_PQ35
 SG_ PH_Lautstaerke_vorn : 44|4@1+ (1,0) [0|15] ""  Gateway_PQ35
 SG_ PH_Trigger_Bildaufschaltung : 48|1@1+ (1,0) [0|1] ""  Gateway_PQ35
 SG_ PH_StartStopp_Info : 49|2@1+ (1,0) [0|3] ""  Gateway_PQ35,Motor_Diesel,Motor_Otto
 SG_ PH_Aufbauten_erk : 51|1@1+ (1,0) [0|1] ""  Gateway_PQ35
 SG_ PH_BerErk_vorn : 52|2@1+ (1,0) [0|3] ""  Gateway_PQ35
 SG_ PH_BerErk_hinten : 54|2@1+ (1,0) [0|3] ""  Gateway_PQ35
 SG_ PH_defekt : 56|1@1+ (1,0) [0|1] ""  Gateway_PQ35
 SG_ PH_gestoert : 57|1@1+ (1,0) [0|1] ""  Gateway_PQ35
 SG_ PH_Systemzustand : 58|3@1+ (1,0) [0|7] ""  Gateway_PQ35
 SG_ PH_Display_Kundenwunsch : 61|2@1+ (1,0) [0|3] ""  Gateway_PQ35
 SG_ PH_KD_Fehler : 63|1@1+ (1,0) [0|1] ""  Gateway_PQ35

BO_ 2033 Req_Airbag_Deployment: 8 Gateway_PQ35
 SG_ Req_Airbag_Deployment : 0|64@1+ (1,0) [0|1.84467440737096E+019] ""  Airbag

BO_ 2041 Resp_Airbag_Deployment: 8 Airbag
 SG_ Resp_Airbag_Deployment : 0|64@1+ (1,0) [0|1.84467440737096E+019] ""  Gateway_PQ35

BO_TX_BU_ 768 : AFS,Airbag,Allrad,Bremse_MK60EC,Bremse_MK70MABS,Bremse_TRW_EBC450M,Bremse_TRW_ESP,Daempfer,EPB_TRW,FLA,Getriebe_AG6,Getriebe_DQ,Getriebe_DQ_Hyb,Getriebe_Sele,HCA,LH_EPS_APA,LH_EPS_ZF_2G,LWR,LWS,Magne_Ride,Motor_Diesel,Motor_Hybrid,Motor_Otto,PDC_PLA,Quersperre_VAQ,RKA_Plus;
BO_TX_BU_ 769 : AFS,Airbag,Allrad,Bremse_MK60EC,Bremse_MK70MABS,Bremse_TRW_EBC450M,Bremse_TRW_ESP,Daempfer,EPB_TRW,FLA,Getriebe_AG6,Getriebe_DQ,Getriebe_DQ_Hyb,Getriebe_Sele,HCA,LH_EPS_APA,LH_EPS_ZF_2G,LWR,LWS,Magne_Ride,Motor_Diesel,Motor_Hybrid,Motor_Otto,PDC_PLA,Quersperre_VAQ,RKA_Plus;
BO_TX_BU_ 770 : AFS,Airbag,Allrad,Bremse_MK60EC,Bremse_MK70MABS,Bremse_TRW_EBC450M,Bremse_TRW_ESP,Daempfer,EPB_TRW,FLA,Getriebe_AG6,Getriebe_DQ,Getriebe_DQ_Hyb,Getriebe_Sele,HCA,LH_EPS_APA,LH_EPS_ZF_2G,LWR,LWS,Magne_Ride,Motor_Diesel,Motor_Hybrid,Motor_Otto,PDC_PLA,Quersperre_VAQ,RKA_Plus;
BO_TX_BU_ 771 : AFS,Airbag,Allrad,Bremse_MK60EC,Bremse_MK70MABS,Bremse_TRW_EBC450M,Bremse_TRW_ESP,Daempfer,EPB_TRW,FLA,Getriebe_AG6,Getriebe_DQ,Getriebe_DQ_Hyb,Getriebe_Sele,HCA,LH_EPS_APA,LH_EPS_ZF_2G,LWR,LWS,Magne_Ride,Motor_Diesel,Motor_Hybrid,Motor_Otto,PDC_PLA,Quersperre_VAQ,RKA_Plus;
BO_TX_BU_ 772 : AFS,Airbag,Allrad,Bremse_MK60EC,Bremse_MK70MABS,Bremse_TRW_EBC450M,Bremse_TRW_ESP,Daempfer,EPB_TRW,FLA,Getriebe_AG6,Getriebe_DQ,Getriebe_DQ_Hyb,Getriebe_Sele,HCA,LH_EPS_APA,LH_EPS_ZF_2G,LWR,LWS,Magne_Ride,Motor_Diesel,Motor_Hybrid,Motor_Otto,PDC_PLA,Quersperre_VAQ,RKA_Plus;
BO_TX_BU_ 773 : AFS,Airbag,Allrad,Bremse_MK60EC,Bremse_MK70MABS,Bremse_TRW_EBC450M,Bremse_TRW_ESP,Daempfer,EPB_TRW,FLA,Getriebe_AG6,Getriebe_DQ,Getriebe_DQ_Hyb,Getriebe_Sele,HCA,LH_EPS_APA,LH_EPS_ZF_2G,LWR,LWS,Magne_Ride,Motor_Diesel,Motor_Hybrid,Motor_Otto,PDC_PLA,Quersperre_VAQ,RKA_Plus;
BO_TX_BU_ 774 : AFS,Airbag,Allrad,Bremse_MK60EC,Bremse_MK70MABS,Bremse_TRW_EBC450M,Bremse_TRW_ESP,Daempfer,EPB_TRW,FLA,Getriebe_AG6,Getriebe_DQ,Getriebe_DQ_Hyb,Getriebe_Sele,HCA,LH_EPS_APA,LH_EPS_ZF_2G,LWR,LWS,Magne_Ride,Motor_Diesel,Motor_Hybrid,Motor_Otto,PDC_PLA,Quersperre_VAQ,RKA_Plus;
BO_TX_BU_ 775 : AFS,Airbag,Allrad,Bremse_MK60EC,Bremse_MK70MABS,Bremse_TRW_EBC450M,Bremse_TRW_ESP,Daempfer,EPB_TRW,FLA,Getriebe_AG6,Getriebe_DQ,Getriebe_DQ_Hyb,Getriebe_Sele,HCA,LH_EPS_APA,LH_EPS_ZF_2G,LWR,LWS,Magne_Ride,Motor_Diesel,Motor_Hybrid,Motor_Otto,PDC_PLA,Quersperre_VAQ,RKA_Plus;
BO_TX_BU_ 515 : Bremse_MK60EC,Bremse_MK70MABS,Bremse_TRW_EBC450M,Bremse_TRW_ESP;
BO_TX_BU_ 524 : Daempfer,Magne_Ride;
BO_TX_BU_ 514 : Getriebe_AG6,Getriebe_DQ,Getriebe_DQ_Hyb,Getriebe_Sele;
BO_TX_BU_ 521 : LH_EPS_APA,LH_EPS_ZF_2G;
BO_TX_BU_ 518 : AFS,LWR;
BO_TX_BU_ 513 : Motor_Diesel,Motor_Hybrid,Motor_Otto;
BO_TX_BU_ 1827 : Bremse_MK60EC,Bremse_MK70MABS,Bremse_TRW_EBC450M,Bremse_TRW_ESP;
BO_TX_BU_ 1825 : Motor_Diesel,Motor_EGolf,Motor_Hybrid,Motor_Otto;
CM_ SG_ 1306 TOG_Zaehler "Zähler wird mit jeder Botschaft inkrementiert";
CM_ SG_ 1306 TOG_Fuellstand_1 "Füllstand im ersten Zeitfenster";
CM_ SG_ 1306 TOG_Fuellstand_2 "Füllstand im zweiten Zeitfenster";
CM_ SG_ 1306 TOG_Fuellstand_3 "Füllstand im dritten Zeitfenster";
CM_ SG_ 1306 TOG_Fuellstand_4 "Füllstand im vierten Zeitfenster";
CM_ SG_ 1306 TOG_Oeltempzeit "Öltemperaturzeit aus max. 4 Zeitfenstern";
CM_ SG_ 1306 TOG_Sensorfehler "Sensorfehler";
CM_ SG_ 1306 TOG_Oelwarn_hoch "Ölwarnschwelle plus Offset überschritten
(wird in mKombi_2 verwendet, falls bei WIV3.2 der TOG-Sensor nicht direkt am Kombi angeschlossen ist, siehe mKombi_2, Byte 1, Bit 1)";
CM_ SG_ 1306 TOG_OelwarnUeber "nur für WIV 3.1 im Audi C6
Ölwarnschwelle überschritten";
CM_ SG_ 1306 TOG_OelmaxUeber "nur für WIV 3.1 im Audi C6
Maximums-Ölfüllstand überschritten";
CM_ SG_ 1306 TOG_Oelmax_hoch "nur für WIV 3.1 im Audi C6
Maximums-Ölfüllstand plus Offset überschritten";
CM_ SG_ 1936 TPDyn_ABS_1 "ABS
TP 2.0 Empfangskanal 1 fuer ABS_SG";
CM_ SG_ 1937 TPDyn_ABS_2 "ABS
TP 2.0 Empfangskanal 2 fuer ABS_SG";
CM_ SG_ 1904 TPDyn_ADR_1 "ADR
TP 2.0 Empfangskanal 1 fuer ADR_SG";
CM_ SG_ 1896 TPDyn_Airbag_1 "Airbag
TP 2.0 Empfangskanal 1 fuer Airbag_SG";
CM_ SG_ 1892 TPDyn_Allrad_1 "Allrad
TP 2.0 Empfangskanal 1 fuer Allrad_SG";
CM_ SG_ 1906 TPDyn_Daempfer_1 "Dämpfer
TP 2.0 Empfangskanal 1 fuer Daempfer_SG";
CM_ SG_ 768 TPDyn_Diag_1_1 "Tester
TP 2.0 Empfangskanal 1 fuer Tester";
CM_ SG_ 769 TPDyn_Diag_1_2 "Tester
TP 2.0 Empfangskanal 2 fuer Tester";
CM_ SG_ 770 TPDyn_Diag_1_3 "Tester
TP 2.0 Empfangskanal 3 fuer Tester";
CM_ SG_ 771 TPDyn_Diag_1_4 "Tester
TP 2.0 Empfangskanal 4 fuer Tester";
CM_ SG_ 772 TPDyn_Diag_1_5 "Tester
TP 2.0 Empfangskanal 5 fuer Tester";
CM_ SG_ 773 TPDyn_Diag_1_6 "Tester
TP 2.0 Empfangskanal 6 fuer Tester";
CM_ SG_ 774 TPDyn_Diag_1_7 "Tester
TP 2.0 Empfangskanal 7 fuer Tester";
CM_ SG_ 775 TPDyn_Diag_1_8 "Tester
TP 2.0 Empfangskanal 8 fuer Tester";
CM_ SG_ 1940 TPDyn_EPB_1 "EPB
TP 2.0 Empfangskanal 1 fuer EPB_SG";
CM_ SG_ 1864 TPDyn_FLA_1 "Quersperre
TP 2.0 Empfangskanal 1 fuer FLA_SG";
CM_ SG_ 1888 TPDyn_Getriebe_1 "Getriebe
TP 2.0 Empfangskanal 1 fuer Getriebe_SG";
CM_ SG_ 1889 TPDyn_Getriebe_2 "Getriebe
TP 2.0 Empfangskanal 2 fuer Getriebe_SG";
CM_ SG_ 1956 TPDyn_LDW_1 "LDW
TP 2.0 Empfangskanal fuer LDW_SG";
CM_ SG_ 1957 TPDyn_LDW_2 "LDW
TP 2.0 Empfangskanal fuer LDW_SG";
CM_ SG_ 1960 TPDyn_Lenkhilfe_1 "Lenkhilfe
TP 2.0 Empfangskanal 1 fuer Lenkhilfe_SG";
CM_ SG_ 1961 TPDyn_Lenkhilfe_2 "Lenkhilfe
TP 2.0 Empfangskanal 2 fuer Lenkhilfe_SG";
CM_ SG_ 1924 TPDyn_Dyn_LWR_1 "Dyn_LWR
TP 2.0 Empfangskanal 1 fuer Dyn_LWR_SG";
CM_ SG_ 1925 TPDyn_Dyn_LWR_2 "Dyn_LWR
TP 2.0 Empfangskanal 2 fuer Dyn_LWR_SG";
CM_ SG_ 1952 TPDyn_LWS "LWS
TP 2.0 Empfangskanal fuer Lenkwinkelsensor";
CM_ SG_ 1856 TPDyn_Motor_1 "Motor
TP 2.0 Empfangskanal 1 fuer Motor_SG";
CM_ SG_ 1857 TPDyn_Motor_2 "Motor
TP 2.0 Empfangskanal 2 fuer Motor_SG";
CM_ SG_ 1858 TPDyn_Motor_3 "Motor
TP 2.0 Empfangskanal 3 fuer Motor_SG";
CM_ SG_ 1859 TPDyn_Motor_4 "Motor
TP 2.0 Empfangskanal 4 fuer Motor_SG";
CM_ SG_ 1978 TPDyn_PLA_PDC "PLA_PDC
TP 2.0 Empfangskanal fuer PLA_SG";
CM_ SG_ 1880 TPDyn_Quersperre_1 "Quersperre
TP 2.0 Empfangskanal 1 fuer Quersperre_SG";
CM_ SG_ 1881 TPDyn_Quersperre_2 "Quersperre
TP 2.0 Empfangskanal 2 fuer Quersperre_SG";
CM_ SG_ 1875 TPDyn_RKA_Plus_2 "RKA_Plus
TP 2.0 Empfangskanal 2 fuer RKA_Plus";
CM_ SG_ 515 ABS_TP_Er "TP 2.0 Eroeffnungskanal";
CM_ SG_ 523 ADR_TP_Er "TP 2.0 Eroeffnungskanal";
CM_ SG_ 517 Airbag_TP_Er "TP 2.0 Eroeffnungskanal";
CM_ SG_ 522 Allrad_TP_Er "TP 2.0 Eroeffnungskanal";
CM_ SG_ 524 Daempfer_TP_Er "TP 2.0 Eroeffnungskanal";
CM_ SG_ 537 EPB_TP_Er "TP 2.0 Eroeffnungskanal";
CM_ SG_ 534 FLA_TP_Er "TP 2.0 Eroeffnungskanal";
CM_ SG_ 514 Getriebe_TP_Er "TP 2.0 Eroeffnungskanal";
CM_ SG_ 538 LDW_TP_Er "TP 2.0 Eroeffnungskanal";
CM_ SG_ 521 Lenkhilfe_TP_Er "TP 2.0 Eroeffnungskanal";
CM_ SG_ 518 Dyn_LWR_TP_Er "TP 2.0 Eroeffnungskanal";
CM_ SG_ 531 LWS_TP_Er "TP 2.0 Eroeffnungskanal";
CM_ SG_ 513 Motor_TP_Er "TP 2.0 Eroeffnungskanal";
CM_ SG_ 541 PLA_PDC_TP_Er "TP 2.0 Eroeffnungskanal";
CM_ SG_ 536 Quersperre_TP_Er "TP 2.0 Eroeffnungskanal";
CM_ SG_ 520 RKA_Plus_TP_Er "TP 2.0 Eroeffnungskanal";
CM_ SG_ 512 Tester_TP_Er "Transportkanaleroeffnung vom Tester zu allen Steuergeraeten mit CAN-Diagnose; TP 2.0
TP 2.0 Eroeffnungskanal";
CM_ SG_ 1096 WH1_StaShiftlock "Status der Shiftlockansteuerung
Shiftlock aktiv bedeutet, der Shiftlockmagnet wird so angesteuert, daß die mechanische Verriegelung greifen würde, wenn die entsprechende Position des Wählhebels vorliegen würde. Dies kann bedeuten, stromlos verriegelt ode";
CM_ SG_ 1096 WH1_Init "Das Bit zeigt dem Empfänger an, dass der Wählhebel in der Initialisierung war (z.B. Reset). Das Signal steht für 500ms ab Sendebeginn auf 1, danach dauerhaft auf 0.";
CM_ SG_ 1096 WH1_Position "Die Codierung der Wählhebelposition entspricht der Codierung in der Getriebe1 Botschaft";
CM_ SG_ 1096 WH1_Status "Das Wählhebelmodul liefert aktuelle Fehlerzustände. Die Fehlereinträge werden im Getriebesteuergerät abgelegt.
(01: z.B. Shift lock, Lampenansteuerung, ...)";
CM_ SG_ 1096 WH1_Testergebnis "Ergebnis des Controllertests initiert durch Testfreigabeflag und Testparameter 1 + 2 aus Getriebe 4
Hier wird in Verbindung mit dem 'Test aktiv Flag' das gültige Testergebnis eines noch zu definierenden Frage- und Antwortspiels zur Überprüfung des Mikrok";
CM_ SG_ 1096 WH1_Zaehler "Freilaufender Botschaftszähler
Dient der Synchronisierung der Getriebebotschaften und stellt sicher, daß der Wählhebelrechner noch lebt, damit der Testmode nicht länger wie zwei Zyklen (20ms) aktiviert ist.";
CM_ SG_ 1096 WH1_Test_Flag "Controllertestergebnis gültig, Wählhebelposition kann evtl. nicht aktuell sein
Test aktiv Flag (Wählhebel 1)";
CM_ SG_ 1096 WH1_Taster_betaetigt "Wählhebeltaster z.B. S-Taste betätigt";
CM_ SG_ 1096 WH1_Position_inv "Bitweise Inverse Codierung der Wählhebelposition aus Byte 1, Bit 7..4
Bemerkungen zur Multiplex-Information: Shiftlock aktiv bedeutet, der Shiftlockmagnet wird so angesteuert, daß die mechanische Verriegelung greifen würde, wenn die entsprechende Positio";
CM_ SG_ 1102 WH2_Checksumme "Prüfsumme mit Endwert 0x0, Definition im CAN Lastenheft (HS-CAN V4.2a, LS-CAN V1.42)";
CM_ SG_ 1102 WH2_Zaehler "Freilaufender Botschaftszähler
Dient der Synchronisierung der Getriebebotschaften und stellt sicher, daß der Wählhebelrechner noch lebt, damit der Testmode nicht länger wie zwei Zyklen (20ms) aktiviert ist.";
CM_ SG_ 1102 WH2_Init "Das Bit zeigt dem Empfänger an, dass der Wählhebel in der Initialisierung war (z.B. Reset). Das Signal steht für 500ms ab Sendebeginn auf 1, danach dauerhaft auf 0.";
CM_ SG_ 1102 WH2_Test_Flag "Controllertestergebnis gültig, Wählhebelposition kann evtl. nicht aktuell sein";
CM_ SG_ 1102 WH2_Sport "Das Bit zeigt an, dass der Fahrer den Sportmodus gewählt hat";
CM_ SG_ 1102 WH2_Winter "Das Bit zeigt an, dass der Fahrer den Wintermodus gewählt hat.";
CM_ SG_ 1102 WH2_Position "Wählhebel mit zwei stabilen Positionen (X und U). Zwischen X und U liegt die Zwischenposition V. Von X kann nach R getippt werden, der Wählhebel fällt danach zurück in X. Von U kann nach +, - und D getippt werden.";
CM_ SG_ 1102 WH2_Ruhestromfehler "Die Wählhebelelektronik enthält eine interne geschaltete Kl. 30 mit der die Hallsensoren versorgt werden. Bei Durchlegiertem Treiber werden die Hallsensoren dauerhaft versorgt, was zu einer erhöhten Ruhestromaufnahme führt. In diesem Fall wird das Bit ges";
CM_ SG_ 1102 WH2_Sensorarray_Einfachfehler "Wird ein Einzelfehler im Sensorarray des Wählhebels erkannt, so wird dieses Bit gesetzt. Seitens Getriebesteuergerät erfolgt ein Fehlerspeichereintrag. Der Wählhebel funktioniert normal weiter.";
CM_ SG_ 1102 WH2_Sensorarray_Mehrfachfehler "Wird ein Mehrfachfehler im Sensorarray des Wählhebels erkannt, so wird dieses Bit gesetzt. Seitens Getriebesteuergerät erfolgt ein Fehlerspeichereintrag. Der Wählhebel wird deaktiviert. Im Kombstrument wird die Priorität 2 Warnmeldung 'Wählhjebel defekt, ";
CM_ SG_ 1102 WH2_Fehler_Sporttaster "Wird eine Unterbrechung der Verbindung zum Sporttaster erkannt, so wird dieses Bit gesetzt. Seitens Getriebesteuergerät erfolgt ein Fehlerspeichereintrag. Der Wählhebel funktioniert normal. Aktivierung der Sportfunktion nicht möglich.";
CM_ SG_ 1102 WH2_Fehler_Fahrstufenanzeige "Wird eine Falschausleuchtung der Getriebeposition am Wählhebel detektiert (Kurzschluss oder Unterbrechung des entsprechenden LED Treibers), so wird dieses Bit gesetzt. Seitens Getriebesteuergerät erfolgt ein Fehlerspeichereintrag. Der Wählhebel funktionie";
CM_ SG_ 1102 WH2_Fehler_Spannungsversorgung "Verlässt die Versorgungsspannung den Bereich in dem ein störungsfreier Betrieb des Wählhebels gesichert ist, so wird dieses Bit gesetzt. Seitens Getriebesteuergerät erfolgt ein Fehlerspeichereintrag. Der Wählhebel funktioniert normal.
Unter-/ Überspannun";
CM_ SG_ 1102 WH2_Timeout_Kombi_2 "Der Wählhebel empfängt vom Kombi das Signal Kl58d für den Dimmwert der Anzeige am Wählhebel. Wird diese Botschaft nicht mehr empfangen, so wird der Dimmwert von der Hardware Kl58s verwendet. Ist auch Kl58s nicht verfügbar wird der maximale Helligkeitswert";
CM_ SG_ 1102 WH2_Timeout_Getriebe_5 "Die Übertragung der Wählhebelposition an das Getriebesteuergerät ist durch ein Frage-Antwort Spiel abgesichert, dass die korrekte Bedienung von Getriebe_5 und Wählhebel_2 Botschaft voraussetzt. Fehlt die Botschalt Getriebe_5, so wird dieses Bit gesetzt. D";
CM_ SG_ 1102 WH2_Timeout_Gate_Komf_1 "Der Wählhebel empfängt aus der Gateway_Komfort_1 Botschaft das Sleep Acknowledge Bit zur Beendigung des Nachlaufes nach Kl. 15 AUS. Fehlt die Botschalt Gateway_Komfort_1, so wird dieses Bit gesetzt. Seitens Getriebesteuergerät erfolgt ein Fehlerspeicherei";
CM_ SG_ 1102 WH2_Testergebnis "Ergebnis des Controllertests initiert durch Testfreigabeflag und Testparameter 1 + 2 aus Getriebe 5
Hier wird in Verbindung mit dem 'Test aktiv Flag' das gültige Testergebnis eines noch zu definierenden Frage- und Antwortspiels zur Überprüfung des Mikrok";
CM_ SG_ 1394 ZA1_S_Kontakt "1 = Schluessel steckt
0 = kein Schlüssel im Zuendschloss, bzw. kein S-Kontakt
S-Kontakt (Schluessel steckt)";
CM_ SG_ 1394 ZA1_Klemme_15 "1 = Klemme 15 ein
0 = Klemme 15 aus
Sollzustand
Klemme 15 (Zuendung ein)";
CM_ SG_ 1394 ZA1_Klemme_X "0=keine Spannung
1 =Spannung vorhanden, entspricht Kl. 15 ausser im Startvorgang
Sollzustand
Klemme X (Startvorgang)";
CM_ SG_ 1394 ZA1_Klemme_50 "1 = Klemme 50 ein
0 = Klemme 50 aus
Sollzustand
Klemme 50 (Starten)";
CM_ SG_ 1394 ZA1_Klemme_P "1 = Klemme P ein (Parklichtstellung)";
CM_ SG_ 919 ZK5_Checksumme "Prüfsumme mit Endwert 0x0, Definition im CAN Lastenheft (HS-CAN V4.2a, LS-CAN V1.42)";
CM_ SG_ 919 ZK5_Zaehler "Botschaftszaehler zur Erkennung fehlender ZKE_5-Botschaften
Definition gemaess Lastenheft";
CM_ SG_ 919 ZK5_Endlage_ausgefahren "1 = Endlage erreicht
Spoiler in Endlage ausgefahren";
CM_ SG_ 919 ZK5_Endlage_eingefahren "1 = Endlage erreicht
Spoiler in Endlage eingefahren";
CM_ SG_ 919 ZK5_Status_Spoiler "Status Spoiler (Spiegelung des WL-Bits zum Kombi)";
CM_ SG_ 919 ZV_SafeFunktion_aktiv "Statusübermittlung ob die Safe Funktion im Fzg. aktiv ist. Das Kombi benötigt das Signal, um den Text Safelock aktiv anzuzeigen.";
CM_ SG_ 919 ZK5_VD_Endlage_geschl "Verdeck geschlossen und Endlage erreicht";
CM_ SG_ 919 ZK5_VD_Endlage_abgelegt "Verdeck geoeffnet und in Endlage abgelegt";
CM_ SG_ 919 ZK5_VD_Verbau "Verbau manuelles oder automatisches Verdeck";
CM_ SG_ 1827 NMH_ABS_Start_1 "Zustand Start (<--Sleep)";
CM_ SG_ 1827 NMH_ABS_Start_2 "Zustand Start (<--Prepare to Sleep)";
CM_ SG_ 1827 NMH_ABS_Normal_Mode_1 "Zustand Normal Mode (<-- Start)";
CM_ SG_ 1827 NMH_ABS_Normal_Mode_2 "Zustand Normal Mode (<-- Ready to Sleep)";
CM_ SG_ 1827 NMH_ABS_Car_WakeUp "Car WakeUp optional";
CM_ SG_ 1827 NMH_ABS_Per_WakeUp "Weckurasche Peripherie
0 = wenn Funktionswakeup
1 = CAN
2 = P-Wakeup, Ursache nicht bekannt
3 = KL 15 HW (falls vorhanden)";
CM_ SG_ 1827 NMH_ABS_Fkt_WakeUp "'Weckursache Funktion'
0 = wenn Peripheriewakeup";
CM_ SG_ 1827 NMH_ABS_NM_aktiv_Klemme_15 "NM-Nachlaufursache, nicht 'Ready To Sleep'
1 = Klemme 15 ein";
CM_ SG_ 1827 NMH_ABS_NM_aktiv_Diagnose "NM-Nachlaufursache, nicht 'Ready To Sleep'
1 = Diagnose bei Kl 15 aus";
CM_ SG_ 1827 NMH_ABS_NM_aktiv_Start "NM-Nachlaufursache, nicht 'Ready To Sleep'
1 = Mindestaktivzeit Zustand 'Start'";
CM_ SG_ 1827 NMH_ABS_NL_aktiv_4 "Nachlaufursache 4
1 = kein Fzg.-Stillstand erkannt";
CM_ SG_ 1827 NMH_ABS_NL_aktiv_5 "Nachlaufursache 5";
CM_ SG_ 1827 NMH_ABS_NL_aktiv_6 "Nachlaufursache 6";
CM_ SG_ 1827 NMH_ABS_NL_aktiv_7 "Nachlaufursache 7";
CM_ SG_ 1827 NMH_ABS_NL_aktiv_8 "Nachlaufursache 8";
CM_ SG_ 1827 NMH_ABS_NL_0 "Nachlauf 0";
CM_ SG_ 1827 NMH_ABS_NL_1 "Nachlauf 1";
CM_ SG_ 1827 NMH_ABS_NL_2 "Nachlauf 2";
CM_ SG_ 1827 NMH_ABS_NL_3 "Nachlauf 3";
CM_ SG_ 1827 NMH_ABS_NL_4 "Nachlauf 4";
CM_ SG_ 1827 NMH_ABS_NL_5 "Nachlauf 5";
CM_ SG_ 1827 NMH_ABS_NL_6 "Nachlauf 6";
CM_ SG_ 1827 NMH_ABS_NL_7 "Nachlauf 7";
CM_ SG_ 1827 NMH_ABS_TimeOut_Fehler "1 = Timeout Fehlerspeichereintrag";
CM_ SG_ 1827 NMH_ABS_CAN_Diag_deaktiv "1 = Keine CAN Bus bezogene Eigendiagnose";
CM_ SG_ 1827 NMH_ABS_KompSchutz "1 = Funktionseinschränkung aufgrund Komponentenschutz / WFS aktiv";
CM_ SG_ 1827 NMH_ABS_Mute_Mode "1 = Funktionseinschränkung aufgrund Mute Mode aktiv, nur VW";
CM_ SG_ 1827 NMH_ABS_Transport_Mode "1 = Funktionseinschränkung aufgrund Transport Mode aktiv";
CM_ SG_ 1827 NMH_ABS_Abschaltstufe_aktiv "1 = Funktionsabschaltung wegen Abschaltstufe";
CM_ SG_ 1827 NMH_ABS_Eindraht_Fehler "1 = Eindrahtbetrieb erkannt";
CM_ SG_ 1838 NMH_BMS_Start_1 "Zustand Start (<--Sleep)";
CM_ SG_ 1838 NMH_BMS_Start_2 "Zustand Start (<--Prepare to Sleep)";
CM_ SG_ 1838 NMH_BMS_Normal_Mode_1 "Zustand Normal Mode (<-- Start)";
CM_ SG_ 1838 NMH_BMS_Normal_Mode_2 "Zustand Normal Mode (<-- Ready to Sleep)";
CM_ SG_ 1838 NMH_BMS_Car_WakeUp "Car WakeUp optional";
CM_ SG_ 1838 NMH_BMS_Per_WakeUp "Weckurasche Peripherie
0 = wenn Funktionswakeup
1 = CAN
2 = P-Wakeup, Ursache nicht bekannt
3 = KL 15 HW (falls vorhanden)";
CM_ SG_ 1838 NMH_BMS_Fkt_WakeUp "'Weckursache Funktion'
0 = wenn Peripheriewakeup";
CM_ SG_ 1838 NMH_BMS_NM_aktiv_Klemme_15 "NM-Nachlaufursache, nicht 'Ready To Sleep'
1 = Klemme 15 ein";
CM_ SG_ 1838 NMH_BMS_NM_aktiv_Diagnose "NM-Nachlaufursache, nicht 'Ready To Sleep'
1 = Diagnose bei Kl 15 aus";
CM_ SG_ 1838 NMH_BMS_NM_aktiv_Start "NM-Nachlaufursache, nicht 'Ready To Sleep'
1 = Mindestaktivzeit Zustand 'Start'";
CM_ SG_ 1838 NMH_BMS_NL_aktiv_4 "Nachlaufursache 4";
CM_ SG_ 1838 NMH_BMS_NL_aktiv_5 "Nachlaufursache 5";
CM_ SG_ 1838 NMH_BMS_NL_aktiv_6 "Nachlaufursache 6";
CM_ SG_ 1838 NMH_BMS_NL_aktiv_7 "Nachlaufursache 7";
CM_ SG_ 1838 NMH_BMS_NL_aktiv_8 "Nachlaufursache 8";
CM_ SG_ 1838 NMH_BMS_NL_0 "Nachlauf 0
1 = EEPROM Schreibzugriff";
CM_ SG_ 1838 NMH_BMS_NL_1 "Nachlauf 1
1 = Lüfter aktiv";
CM_ SG_ 1838 NMH_BMS_NL_2 "Nachlauf 2";
CM_ SG_ 1838 NMH_BMS_NL_3 "Nachlauf 3";
CM_ SG_ 1838 NMH_BMS_NL_4 "Nachlauf 4";
CM_ SG_ 1838 NMH_BMS_NL_5 "Nachlauf 5";
CM_ SG_ 1838 NMH_BMS_NL_6 "Nachlauf 6";
CM_ SG_ 1838 NMH_BMS_NL_7 "Nachlauf 7";
CM_ SG_ 1838 NMH_BMS_TimeOut_Fehler "1 = Timeout Fehlerspeichereintrag";
CM_ SG_ 1838 NMH_BMS_CAN_Diag_deaktiv "1 = Keine CAN Bus bezogene Eigendiagnose";
CM_ SG_ 1838 NMH_BMS_KompSchutz "1 = Funktionseinschränkung aufgrund Komponentenschutz / WFS aktiv";
CM_ SG_ 1838 NMH_BMS_Mute_Mode "1 = Funktionseinschränkung aufgrund Mute Mode aktiv, nur VW";
CM_ SG_ 1838 NMH_BMS_Transport_Mode "1 = Funktionseinschränkung aufgrund Transport Mode aktiv";
CM_ SG_ 1838 NMH_BMS_Abschaltstufe_aktiv "1 = Funktionsabschaltung wegen Abschaltstufe";
CM_ SG_ 1838 NMH_BMS_Eindraht_Fehler "1 = Eindrahtbetrieb erkannt";
CM_ SG_ 1839 NMH_EM_Start_1 "Zustand Start (<--Sleep)";
CM_ SG_ 1839 NMH_EM_Start_2 "Zustand Start (<--Prepare to Sleep)";
CM_ SG_ 1839 NMH_EM_Normal_Mode_1 "Zustand Normal Mode (<-- Start)";
CM_ SG_ 1839 NMH_EM_Normal_Mode_2 "Zustand Normal Mode (<-- Ready to Sleep)";
CM_ SG_ 1839 NMH_EM_Car_WakeUp "Car WakeUp optional";
CM_ SG_ 1839 NMH_EM_Per_WakeUp "Weckurasche Peripherie
0 = wenn Funktionswakeup
1 = CAN
2 = P-Wakeup, Ursache nicht bekannt
3 = KL 15 HW (falls vorhanden)";
CM_ SG_ 1839 NMH_EM_Fkt_WakeUp "'Weckursache Funktion'
0 = wenn Peripheriewakeup";
CM_ SG_ 1839 NMH_EM_NM_aktiv_Klemme_15 "NM-Nachlaufursache, nicht 'Ready To Sleep'
1 = Klemme 15 ein";
CM_ SG_ 1839 NMH_EM_NM_aktiv_Diagnose "NM-Nachlaufursache, nicht 'Ready To Sleep'
1 = Diagnose bei Kl 15 aus";
CM_ SG_ 1839 NMH_EM_NM_aktiv_Start "NM-Nachlaufursache, nicht 'Ready To Sleep'
1 = Mindestaktivzeit Zustand 'Start'";
CM_ SG_ 1839 NMH_EM_NL_aktiv_4 "Nachlaufursache 4";
CM_ SG_ 1839 NMH_EM_NL_aktiv_5 "Nachlaufursache 5";
CM_ SG_ 1839 NMH_EM_NL_aktiv_6 "Nachlaufursache 6";
CM_ SG_ 1839 NMH_EM_NL_aktiv_7 "Nachlaufursache 7";
CM_ SG_ 1839 NMH_EM_NL_aktiv_8 "Nachlaufursache 8";
CM_ SG_ 1839 NMH_EM_NL_0 "Nachlauf 0
1 = EEPROM Schreibzugriff";
CM_ SG_ 1839 NMH_EM_NL_1 "Nachlauf 1
1 = Ansteuerung der Kühlpumpe an der LE";
CM_ SG_ 1839 NMH_EM_NL_2 "Nachlauf 2";
CM_ SG_ 1839 NMH_EM_NL_3 "Nachlauf 3";
CM_ SG_ 1839 NMH_EM_NL_4 "Nachlauf 4";
CM_ SG_ 1839 NMH_EM_NL_5 "Nachlauf 5";
CM_ SG_ 1839 NMH_EM_NL_6 "Nachlauf 6";
CM_ SG_ 1839 NMH_EM_NL_7 "Nachlauf 7";
CM_ SG_ 1839 NMH_EM_TimeOut_Fehler "1 = Timeout Fehlerspeichereintrag";
CM_ SG_ 1839 NMH_EM_CAN_Diag_deaktiv "1 = Keine CAN Bus bezogene Eigendiagnose";
CM_ SG_ 1839 NMH_EM_KompSchutz "1 = Funktionseinschränkung aufgrund Komponentenschutz / WFS aktiv";
CM_ SG_ 1839 NMH_EM_Mute_Mode "1 = Funktionseinschränkung aufgrund Mute Mode aktiv, nur VW";
CM_ SG_ 1839 NMH_EM_Transport_Mode "1 = Funktionseinschränkung aufgrund Transport Mode aktiv";
CM_ SG_ 1839 NMH_EM_Abschaltstufe_aktiv "1 = Funktionsabschaltung wegen Abschaltstufe";
CM_ SG_ 1839 NMH_EM_Eindraht_Fehler "1 = Eindrahtbetrieb erkannt";
CM_ SG_ 1849 NMH_EPB_Start_1 "Zustand Start (<--Sleep)";
CM_ SG_ 1849 NMH_EPB_Start_2 "Zustand Start (<--Prepare to Sleep)";
CM_ SG_ 1849 NMH_EPB_Normal_Mode_1 "Zustand Normal Mode (<-- Start)";
CM_ SG_ 1849 NMH_EPB_Normal_Mode_2 "Zustand Normal Mode (<-- Ready to Sleep)";
CM_ SG_ 1849 NMH_EPB_Car_WakeUp "Car WakeUp optional";
CM_ SG_ 1849 NMH_EPB_Per_WakeUp "Weckurasche Peripherie
0 = wenn Funktionswakeup
1 = CAN
2 = P-Wakeup, Ursache nicht bekannt
3 = KL 15 HW (falls vorhanden)
5 = Schalter EPB";
CM_ SG_ 1849 NMH_EPB_Fkt_WakeUp "'Weckursache Funktion'
0 = wenn Peripheriewakeup";
CM_ SG_ 1849 NMH_EPB_NM_aktiv_Klemme_15 "NM-Nachlaufursache, nicht 'Ready To Sleep'
1 = Klemme 15 ein";
CM_ SG_ 1849 NMH_EPB_NM_aktiv_Diagnose "NM-Nachlaufursache, nicht 'Ready To Sleep'
1 = Diagnose bei Kl 15 aus";
CM_ SG_ 1849 NMH_EPB_NM_aktiv_Start "NM-Nachlaufursache, nicht 'Ready To Sleep'
1 = Mindestaktivzeit Zustand 'Start'";
CM_ SG_ 1849 NMH_EPB_NL_aktiv_4 "Nachlaufursache 4";
CM_ SG_ 1849 NMH_EPB_NL_aktiv_5 "Nachlaufursache 5";
CM_ SG_ 1849 NMH_EPB_NL_aktiv_6 "Nachlaufursache 6";
CM_ SG_ 1849 NMH_EPB_NL_aktiv_7 "Nachlaufursache 7";
CM_ SG_ 1849 NMH_EPB_NL_aktiv_8 "Nachlaufursache 8";
CM_ SG_ 1849 NMH_EPB_NL_0 "Nachlauf 0";
CM_ SG_ 1849 NMH_EPB_NL_1 "Nachlauf 1";
CM_ SG_ 1849 NMH_EPB_NL_2 "Nachlauf 2";
CM_ SG_ 1849 NMH_EPB_NL_3 "Nachlauf 3";
CM_ SG_ 1849 NMH_EPB_NL_4 "Nachlauf 4";
CM_ SG_ 1849 NMH_EPB_NL_5 "Nachlauf 5";
CM_ SG_ 1849 NMH_EPB_NL_6 "Nachlauf 6";
CM_ SG_ 1849 NMH_EPB_NL_7 "Nachlauf 7";
CM_ SG_ 1849 NMH_EPB_TimeOut_Fehler "1 = Timeout Fehlerspeichereintrag";
CM_ SG_ 1849 NMH_EPB_CAN_Diag_deaktiv "1 = Keine CAN Bus bezogene Eigendiagnose";
CM_ SG_ 1849 NMH_EPB_KompSchutz "1 = Funktionseinschränkung aufgrund Komponentenschutz / WFS aktiv";
CM_ SG_ 1849 NMH_EPB_Mute_Mode "1 = Funktionseinschränkung aufgrund Mute Mode aktiv, nur VW";
CM_ SG_ 1849 NMH_EPB_Transport_Mode "1 = Funktionseinschränkung aufgrund Transport Mode aktiv";
CM_ SG_ 1849 NMH_EPB_Abschaltstufe_aktiv "1 = Funktionsabschaltung wegen Abschaltstufe";
CM_ SG_ 1849 NMH_EPB_Eindraht_Fehler "1 = Eindrahtbetrieb erkannt";
CM_ SG_ 1824 NMH_GW_Start_1 "Zustand Start (<--Sleep)";
CM_ SG_ 1824 NMH_GW_Start_2 "Zustand Start (<--Prepare to Sleep)";
CM_ SG_ 1824 NMH_GW_Normal_Mode_1 "Zustand Normal Mode (<-- Start)";
CM_ SG_ 1824 NMH_GW_Normal_Mode_2 "Zustand Normal Mode (<-- Ready to Sleep)";
CM_ SG_ 1824 NMH_GW_Car_WakeUp "Car WakeUp optional";
CM_ SG_ 1824 NMH_GW_Per_WakeUp "Weckursache Peripherie
0 = wenn Funktionswakeup
1 = CAN
2 = P-WakeUp, Ursache nicht bekannt
3 = KL 15 HW (falls vorhanden)
4 = Weckereignis am Antriebs-CAN-Transceiver erkannt
5 = Weckereignis am Kombi-CAN-Transceiver erkannt
6 = Weckereignis am Ko";
CM_ SG_ 1824 NMH_GW_Fkt_WakeUp "'Weckursache Funktion'
0 = wenn Peripheriewakeup
1 = Antriebs-CAN-Ereignis fordert diesen Bus
2 = Kombi-CAN-Ereignis fordert diesen Bus
3 = Komfort-CAN-Ereignis fordert diesen Bus
4 = Infotainment-CAN-Ereignis fordert diesen Bus
5 = Extended-CAN-Ere";
CM_ SG_ 1824 NMH_GW_NM_aktiv_Klemme_15 "NM-Nachlaufursache, nicht 'Ready To Sleep'
1 = Klemme 15 ein";
CM_ SG_ 1824 NMH_GW_NM_aktiv_Diagnose "NM-Nachlaufursache, nicht 'Ready To Sleep'
1 = Diagnose bei Kl 15 aus";
CM_ SG_ 1824 NMH_GW_NM_aktiv_Start "NM-Nachlaufursache, nicht 'Ready To Sleep'
1 = Mindestaktivzeit Zustand 'Start'";
CM_ SG_ 1824 NMH_GW_NL_aktiv_4 "Nachlaufursache 4
1 = ACAN-Nachlauf über Sleep-Indication-Bit (ACAN)
1 = Kombi-Wakeup-Leitung aktiv (KombiCAN)";
CM_ SG_ 1824 NMH_GW_NL_aktiv_5 "Nachlaufursache 5
1 = Komfort-CAN fordert Antriebs-CAN (ACAN)
1 = Kombi fordert Komfort oder Kombi-Sleep-Indication-Bit (KombiCAN)";
CM_ SG_ 1824 NMH_GW_NL_aktiv_6 "Nachlaufursache 6
1 = Antriebs-CAN-Nachlauf (inkl. NM-High) (KombiCAN)";
CM_ SG_ 1824 NMH_GW_NL_aktiv_7 "Nachlaufursache 7
1 = Infortainment-CAN aktiv (KombiCAN)";
CM_ SG_ 1824 NMH_GW_NL_aktiv_8 "Nachlaufursache 8
1 = Komfort-CAN aktiv (KombiCAN)";
CM_ SG_ 1824 NMH_GW_NL_0 "Nachlauf 0";
CM_ SG_ 1824 NMH_GW_NL_1 "Nachlauf 1";
CM_ SG_ 1824 NMH_GW_NL_2 "Nachlauf 2";
CM_ SG_ 1824 NMH_GW_NL_3 "Nachlauf 3";
CM_ SG_ 1824 NMH_GW_NL_4 "Nachlauf 4";
CM_ SG_ 1824 NMH_GW_NL_5 "Nachlauf 5";
CM_ SG_ 1824 NMH_GW_NL_6 "Nachlauf 6";
CM_ SG_ 1824 NMH_GW_NL_7 "Nachlauf 7";
CM_ SG_ 1824 NMH_GW_TimeOut_Fehler "1 = Timeout Fehlerspeichereintrag";
CM_ SG_ 1824 NMH_GW_CAN_Diag_deaktiv "1 = Keine CAN Bus bezogene Eigendiagnose";
CM_ SG_ 1824 NMH_GW_KompSchutz "1 = Funktionseinschränkung aufgrund Komponentenschutz / WFS aktiv";
CM_ SG_ 1824 NMH_GW_Mute_Mode "1 = Funktionseinschränkung aufgrund Mute Mode aktiv, nur VW";
CM_ SG_ 1824 NMH_GW_Transport_Mode "1 = Funktionseinschränkung aufgrund Transport Mode aktiv";
CM_ SG_ 1824 NMH_GW_Abschaltstufe_aktiv "1 = Funktionsabschaltung wegen Abschaltstufe";
CM_ SG_ 1824 NMH_GW_Eindraht_Fehler "1 = Eindrahtbetrieb erkannt";
CM_ SG_ 1836 NMH_Ladegeraet_Start_1 "Zustand Start (<--Sleep)";
CM_ SG_ 1836 NMH_Ladegeraet_Start_2 "Zustand Start (<--Prepare to Sleep)";
CM_ SG_ 1836 NMH_Ladegeraet_Normal_Mode_1 "Zustand Normal Mode (<-- Start)";
CM_ SG_ 1836 NMH_Ladegeraet_Normal_Mode_2 "Zustand Normal Mode (<-- Ready to Sleep)";
CM_ SG_ 1836 NMH_Ladegeraet_Car_WakeUp "Car WakeUp optional";
CM_ SG_ 1836 NMH_Ladegeraet_Per_WakeUp "Weckurasche Peripherie
0 = wenn Funktionswakeup
1 = CAN
2 = P-Wakeup, Ursache nicht bekannt
3 = KL 15 HW (falls vorhanden)
4 = Taster Sofortladen";
CM_ SG_ 1836 NMH_Ladegeraet_Fkt_WakeUp "'Weckursache Funktion'
0 = wenn Peripheriewakeup";
CM_ SG_ 1836 NMH_Ladegeraet_NM_aktiv_Klemm000 "NM-Nachlaufursache, nicht 'Ready To Sleep'
1 = Klemme 15 ein";
CM_ SG_ 1836 NMH_Ladegeraet_NM_aktiv_Diagnose "NM-Nachlaufursache, nicht 'Ready To Sleep'
1 = Diagnose bei Kl 15 aus";
CM_ SG_ 1836 NMH_Ladegeraet_NM_aktiv_Start "NM-Nachlaufursache, nicht 'Ready To Sleep'
1 = Mindestaktivzeit Zustand 'Start'";
CM_ SG_ 1836 NMH_Ladegeraet_NL_aktiv_4 "Nachlaufursache 4
Ladezeitberechnung";
CM_ SG_ 1836 NMH_Ladegeraet_NL_aktiv_5 "Nachlaufursache 5
Ladevorgang aktiv";
CM_ SG_ 1836 NMH_Ladegeraet_NL_aktiv_6 "Nachlaufursache 6
Batterietemperierung aktiv";
CM_ SG_ 1836 NMH_Ladegeraet_NL_aktiv_7 "Nachlaufursache 7";
CM_ SG_ 1836 NMH_Ladegeraet_NL_aktiv_8 "Nachlaufursache 8";
CM_ SG_ 1836 NMH_Ladegeraet_NL_0 "Nachlauf 0
";
CM_ SG_ 1836 NMH_Ladegeraet_NL_1 "Nachlauf 1";
CM_ SG_ 1836 NMH_Ladegeraet_NL_2 "Nachlauf 2";
CM_ SG_ 1836 NMH_Ladegeraet_NL_3 "Nachlauf 3";
CM_ SG_ 1836 NMH_Ladegeraet_NL_4 "Nachlauf 4";
CM_ SG_ 1836 NMH_Ladegeraet_NL_5 "Nachlauf 5";
CM_ SG_ 1836 NMH_Ladegeraet_NL_6 "Nachlauf 6";
CM_ SG_ 1836 NMH_Ladegeraet_NL_7 "Nachlauf 7";
CM_ SG_ 1836 NMH_Ladegeraet_TimeOut_Fehler "1 = Timeout Fehlerspeichereintrag";
CM_ SG_ 1836 NMH_Ladegeraet_CAN_Diag_deaktiv "1 = Keine CAN Bus bezogene Eigendiagnose";
CM_ SG_ 1836 NMH_Ladegeraet_KompSchutz "1 = Funktionseinschränkung aufgrund Komponentenschutz / WFS aktiv";
CM_ SG_ 1836 NMH_Ladegeraet_Mute_Mode "1 = Funktionseinschränkung aufgrund Mute Mode aktiv, nur VW";
CM_ SG_ 1836 NMH_Ladegeraet_Transport_Mode "1 = Funktionseinschränkung aufgrund Transport Mode aktiv";
CM_ SG_ 1836 NMH_Ladegeraet_Abschaltstufe_001 "1 = Funktionsabschaltung wegen Abschaltstufe";
CM_ SG_ 1836 NMH_Ladegeraet_Eindraht_Fehler "1 = Eindrahtbetrieb erkannt";
CM_ SG_ 1825 NMH_MO_Start_1 "Zustand Start (<--Sleep)";
CM_ SG_ 1825 NMH_MO_Start_2 "Zustand Start (<--Prepare to Sleep)";
CM_ SG_ 1825 NMH_MO_Normal_Mode_1 "Zustand Normal Mode (<-- Start)";
CM_ SG_ 1825 NMH_MO_Normal_Mode_2 "Zustand Normal Mode (<-- Ready to Sleep)";
CM_ SG_ 1825 NMH_MO_Car_WakeUp "Car WakeUp optional";
CM_ SG_ 1825 NMH_MO_Per_WakeUp "Weckurasche Peripherie
0 = wenn Funktionswakeup
1 = CAN
2 = P-Wakeup, Ursache nicht bekannt
3 = KL 15 HW (falls vorhanden)
4 = HW-Weckleitung (alte MED9)
5 = Ladestecker gesteckt";
CM_ SG_ 1825 NMH_MO_Fkt_WakeUp "'Weckursache Funktion'
0 = wenn Peripheriewakeup";
CM_ SG_ 1825 NMH_MO_NM_aktiv_Klemme_15 "NM-Nachlaufursache, nicht 'Ready To Sleep'
1 = Klemme 15 ein";
CM_ SG_ 1825 NMH_MO_NM_aktiv_Diagnose "NM-Nachlaufursache, nicht 'Ready To Sleep'
1 = Diagnose bei Kl 15 aus";
CM_ SG_ 1825 NMH_MO_NM_aktiv_Start "NM-Nachlaufursache, nicht 'Ready To Sleep'
1 = Mindestaktivzeit Zustand 'Start'";
CM_ SG_ 1825 NMH_MO_NL_aktiv_4 "Nachlaufursache 4
1 = EKP Vorlauf";
CM_ SG_ 1825 NMH_MO_NL_aktiv_5 "Nachlaufursache 5
1 = Standheizungs-Betrieb";
CM_ SG_ 1825 NMH_MO_NL_aktiv_6 "Nachlaufursache 6
1 = Hybrid-Manager deaktiviert alle Hochvolt-Verbraucher für stromloses Öffnen der Batterieschütze";
CM_ SG_ 1825 NMH_MO_NL_aktiv_7 "Nachlaufursache 7
1 = Innenraumklimatisierung (EGolf)";
CM_ SG_ 1825 NMH_MO_NL_aktiv_8 "Nachlaufursache 8
1 = LM_Systemanforderung (EGolf)";
CM_ SG_ 1825 NMH_MO_NL_0 "Nachlauf 0";
CM_ SG_ 1825 NMH_MO_NL_1 "Nachlauf 1
1 = Kühlerlüfter Steuerung / Zusatzwasserpumpe";
CM_ SG_ 1825 NMH_MO_NL_2 "Nachlauf 2
1 = Diagnosefunktionen aktiv";
CM_ SG_ 1825 NMH_MO_NL_3 "Nachlauf 3
1 = Wegfahrsperre aktiv";
CM_ SG_ 1825 NMH_MO_NL_4 "Nachlauf 4
1 = EEPROM Zugriffe RAM/ROM Tests";
CM_ SG_ 1825 NMH_MO_NL_5 "Nachlauf 5
1 = Sonstige Nachläufe aktiv";
CM_ SG_ 1825 NMH_MO_NL_6 "Nachlauf 6";
CM_ SG_ 1825 NMH_MO_NL_7 "Nachlauf 7";
CM_ SG_ 1825 NMH_MO_TimeOut_Fehler "1 = Timeout Fehlerspeichereintrag";
CM_ SG_ 1825 NMH_MO_CAN_Diag_deaktiv "1 = Keine CAN Bus bezogene Eigendiagnose";
CM_ SG_ 1825 NMH_MO_KompSchutz "1 = Funktionseinschränkung aufgrund Komponentenschutz / WFS aktiv";
CM_ SG_ 1825 NMH_MO_Mute_Mode "1 = Funktionseinschränkung aufgrund Mute Mode aktiv, nur VW";
CM_ SG_ 1825 NMH_MO_Transport_Mode "1 = Funktionseinschränkung aufgrund Transport Mode aktiv";
CM_ SG_ 1825 NMH_MO_Abschaltstufe_aktiv "1 = Funktionsabschaltung wegen Abschaltstufe";
CM_ SG_ 1825 NMH_MO_Eindraht_Fehler "1 = Eindrahtbetrieb erkannt";
CM_ SG_ 1523 OBD_TG_F_Status_1 "Fehlerstatus Tankfüllstandsgeber (OBD relevanter Sensor für Tankleckdiagnose)
0 = kein Fehler / Init / nicht verbaut
1 = KS- (Kurzschluss nach Masse -> Widerstand zu klein)
2 = KS+ (nicht verwendet)
3 = OC (Leitungsunterbrechung) (nicht verwendet)
4 ";
CM_ SG_ 1523 OBD_TG_F_Status_2 "Fehlerstatus Tankfüllstandsgeber (OBD relevanter Sensor für Tankleckdiagnose)
0 = kein Fehler / Init / nicht verbaut
1 = KS- (Kurzschluss nach Masse -> Widerstand zu klein)
2 = KS+ (nicht verwendet)
3 = OC (Leitungsunterbrechung) (nicht verwendet)
4 ";
CM_ SG_ 1523 OBD_TG_F_Status_3 "Fehlerstatus Tankfüllstandsgeber (OBD relevanter Sensor für Tankleckdiagnose)
0 = kein Fehler / Init / nicht verbaut
1 = KS- (Kurzschluss nach Masse -> Widerstand zu klein)
2 = KS+ (nicht verwendet)
3 = OC (Leitungsunterbrechung) (nicht verwendet)
4 ";
CM_ SG_ 1523 OBD_TG_F_Status_4 "Fehlerstatus Tankfüllstandsgeber (OBD relevanter Sensor für Tankleckdiagnose)
0 = kein Fehler / Init / nicht verbaut
1 = KS- (Kurzschluss nach Masse -> Widerstand zu klein)
2 = KS+ (nicht verwendet)
3 = OC (Leitungsunterbrechung) (nicht verwendet)
4 ";
CM_ SG_ 1523 OBD_TG_Sens_Rohwert_1 "Rohwert des Tankgebers, nur gefiltert (gleitender Mittelwert), Ausgabe im 500ms-Raster";
CM_ SG_ 1523 OBD_TG_Sens_Rohwert_2 "Rohwert des Tankgebers, nur gefiltert (gleitender Mittelwert), Ausgabe im 500ms-Raster";
CM_ SG_ 1523 OBD_TG_Sens_Rohwert_3 "Rohwert des Tankgebers, nur gefiltert (gleitender Mittelwert), Ausgabe im 500ms-Raster";
CM_ SG_ 1523 OBD_TG_Sens_Rohwert_4 "Rohwert des Tankgebers, nur gefiltert (gleitender Mittelwert), Ausgabe im 500ms-Raster";
CM_ SG_ 1175 PH_Abschaltursache "Abschaltursache bleibt bis zur nächsten Aktivierung bzw. bis KL15 aus gesetzt
0 = keine, bzw. System aktiv
1 = Abschaltung durch Herausnahme R-Gang
2 = Abschaltung ueber Geschwindigkeit
3 = Abschaltung ueber PDC-Taster
4 = Abschaltung wegen PLA
5 = ";
CM_ SG_ 1175 PH_Opt_Anzeige_V_ein "OPS vorne ist im Display aktiv bzw. Anzeigemodule vorne sind eingeschaltet
Optische Anzeige vorn aktiv";
CM_ SG_ 1175 PH_Opt_Anzeige_H_ein "OPS hinten ist im Display aktiv bzw. Anzeigemodule hinten sind eingeschaltet
Optische Anzeige hinten aktiv";
CM_ SG_ 1175 PH_Opt_Anz_V_Hindernis "mindestens 1 Segment wird für den vorderen Detekionsbereich dargestellt, also ein Hindernis ist im Detektionsbereich
Optische Anzeige vorn Hindernis";
CM_ SG_ 1175 PH_Opt_Anz_H_Hindernis "mindestens 1 Segment wird für den hinteren Detekionsbereich dargestellt, also ein Hindernis ist im Detektionsbereich
Optische Anzeige hinten Hindernis";
CM_ SG_ 1175 PH_Tongeber_V_aktiv "Rohsignal für 'Tongeber vorne wird angesteuert', verlängerbar mit Nachlauftimer
Tongeber vorn aktiv";
CM_ SG_ 1175 PH_Tongeber_H_aktiv "Rohsignal für 'Tongeber hinten wird angesteuert', verlängerbar mit Nachlauftimer
Tongeber hinten aktiv";
CM_ SG_ 1175 PH_Tongeber_mute "1 = Tongeber stummgeschaltet;
Tongeber Mute";
CM_ SG_ 1175 PH_Anf_Audioabsenkung "1 = Anforderung an das Audiosystem für Absenkung der Lautstärke";
CM_ SG_ 1175 PH_Anf_Verdeck "Anforderung an ein Verdeck-System, die vom Fahrer angeforderte Öffnung/Schließung zu verhindern";
CM_ SG_ 1175 PH_Frequenz_hinten "Uebertragung der aktuell im APS Steuergeraet gespeicherten Werte fuer Tongeber Frequenz hinten";
CM_ SG_ 1175 PH_Lautstaerke_hinten "Uebertragung der aktuell im APS Steuergeraet gespeicherten Werte fuer Tongeber Lautstaerke hinten";
CM_ SG_ 1175 PH_Frequenz_vorn "Uebertragung der aktuell im APS Steuergeraet gespeicherten Werte fuer Tongeber Frequenz vorne";
CM_ SG_ 1175 PH_Lautstaerke_vorn "Uebertragung der aktuell im APS Steuergeraet gespeicherten Werte fuer Tongeber Lautstaerke vorn.";
CM_ SG_ 1175 PH_Trigger_Bildaufschaltung "nur Audi für OPS in der RNS-E";
CM_ SG_ 1175 PH_StartStopp_Info "Stopp-Freigabe/Start-Anforderung für den Start-Stopp-Koordinator";
CM_ SG_ 1175 PH_defekt "ein Fehler ist aufgetreten, der die Parkhilfe in den Fehlerzustand versetzt, Signal bleibt bis zur nächsten 'Gut-Aktivierung' gesetzt";
CM_ SG_ 1175 PH_gestoert "eine Störung ist aufgetreten, der die Parkhilfe in einen 'gestört-Zustand' versetzt, z.B. massiver Fremdultraschall, Vereisung, Schnee";
CM_ SG_ 1175 PH_Systemzustand "Aktivierungsursache wird für die Dauer der Aktivierung gemeldet
Im Fehlerfall bei aktivem System wechselt das Signal auf '7'
(siehe auch 'Abschaltursache')";
CM_ SG_ 1175 PH_Display_Kundenwunsch "Anzeige der aktuell verwendeten Parameter bzgl. Kundenwunsch Displayanziege bei Aktivierung (nicht zwingend die abgespeicherten !)";
CM_ SG_ 1175 PH_KD_Fehler "mindestens ein Fehler ist im Kundendienstfehlerspeicher eingetragen";
BA_DEF_ BO_  "GenMsgAutoGenDsp" ENUM  "No","Yes";
BA_DEF_ BO_  "GenMsgAutoGenSnd" ENUM  "No","Yes";
BA_DEF_ BO_  "GenMsgCycleTime" INT 0 65535;
BA_DEF_ BO_  "GenMsgCycleTimeFast" INT 0 65535;
BA_DEF_ BO_  "GenMsgDelayTime" INT 0 100000;
BA_DEF_ BO_  "GenMsgILSupport" ENUM  "No","Yes";
BA_DEF_ BO_  "GenMsgSendType" ENUM  "Cyclic","not_used","not_used","not_used","not_used","not_used","not_used","IfActive","NoMsgSendType";
BA_DEF_ BO_  "GenMsgStartDelayTime" INT 0 100000;
BA_DEF_ BO_  "NmMessage" ENUM  "No","Yes";
BA_DEF_ BO_  "NmhMessage" ENUM  "No","Yes";
BA_DEF_ BO_  "VAGTP20_API" HEX 0 255;
BA_DEF_ BO_  "VAGTP20_DynConnection" ENUM  "No","Yes";
BA_DEF_ BO_  "VAGTP20_DynSetup" ENUM  "No","Yes";
BA_DEF_ BO_  "VAGTP20_StatConnection" ENUM  "No","Yes";
BA_DEF_ BO_  "Timeoutzeit" INT 0 1000000;
BA_DEF_ BO_  "DiagRequest" ENUM  "No","Yes";
BA_DEF_ BO_  "DiagResponse" ENUM  "No","Yes";
BA_DEF_ BO_  "DiagState" ENUM  "No","Yes";
BA_DEF_ BO_  "GenMsgChkConstant" HEX 0 4095;
BA_DEF_ SG_  "GenSigAutoGenDsp" ENUM  "No","Yes";
BA_DEF_ SG_  "GenSigAutoGenSnd" ENUM  "No","Yes";
BA_DEF_ SG_  "GenSigEnvVarType" ENUM  "int","float","undef";
BA_DEF_ SG_  "GenSigInactiveValue" INT -2147483648 2147483647;
BA_DEF_ SG_  "GenSigSendType" ENUM  "Cyclic","OnWrite","OnWriteWithRepetition","OnChange","OnChangeWithRepetition","IfActive","IfActiveWithRepetition","NoSigSendType","OnChangeAndIfActive","OnChangeAndIfActiveWithRepetition";
BA_DEF_ SG_  "GenSigStartValue" INT -2147483648 2147483647;
BA_DEF_ SG_  "NWM-WakeupAllowed" ENUM  "No","Yes";
BA_DEF_ SG_  "GenSigFuncType" ENUM  "NoFunction","MsgCounter","CRC-8","XOR","XOR-2","DatedBit","SW-Kl15","CHK","Constant","Protocol";
BA_DEF_ SG_  "GenSigSwitchedByIgnition" ENUM  "No","Yes";
BA_DEF_ SG_  "Fehlerwert" HEX 0 2147483647;
BA_DEF_ SG_  "GenSigMissingSourceValue" HEX 0 2147483647;
BA_DEF_REL_ BU_SG_REL_  "GenSigTimeoutTime" INT 0 65535;
BA_DEF_DEF_REL_ "GenSigTimeoutTime" 0;
BA_DEF_DEF_  "GenMsgAutoGenDsp" "Yes";
BA_DEF_DEF_  "GenMsgAutoGenSnd" "Yes";
BA_DEF_DEF_  "GenMsgCycleTime" 0;
BA_DEF_DEF_  "GenMsgCycleTimeFast" 0;
BA_DEF_DEF_  "GenMsgDelayTime" 0;
BA_DEF_DEF_  "GenMsgILSupport" "No";
BA_DEF_DEF_  "GenMsgSendType" "NoMsgSendType";
BA_DEF_DEF_  "GenMsgStartDelayTime" 0;
BA_DEF_DEF_  "NmMessage" "No";
BA_DEF_DEF_  "NmhMessage" "No";
BA_DEF_DEF_  "VAGTP20_API" 0;
BA_DEF_DEF_  "VAGTP20_DynConnection" "No";
BA_DEF_DEF_  "VAGTP20_DynSetup" "No";
BA_DEF_DEF_  "VAGTP20_StatConnection" "No";
BA_DEF_DEF_  "Timeoutzeit" 0;
BA_DEF_DEF_  "DiagRequest" "No";
BA_DEF_DEF_  "DiagResponse" "No";
BA_DEF_DEF_  "DiagState" "No";
BA_DEF_DEF_  "GenMsgChkConstant" 0;
BA_DEF_DEF_  "GenSigAutoGenDsp" "No";
BA_DEF_DEF_  "GenSigAutoGenSnd" "No";
BA_DEF_DEF_  "GenSigEnvVarType" "undef";
BA_DEF_DEF_  "GenSigInactiveValue" 0;
BA_DEF_DEF_  "GenSigSendType" "NoSigSendType";
BA_DEF_DEF_  "GenSigStartValue" 0;
BA_DEF_DEF_  "NWM-WakeupAllowed" "No";
BA_DEF_DEF_  "GenSigFuncType" "NoFunction";
BA_DEF_DEF_  "GenSigSwitchedByIgnition" "Yes";
BA_DEF_DEF_  "Fehlerwert" 0;
BA_DEF_DEF_  "GenSigMissingSourceValue" 0;
BA_ "GenMsgSendType" BO_ 1306 0;
BA_ "GenMsgILSupport" BO_ 1306 1;
BA_ "GenMsgCycleTime" BO_ 1306 500;
BA_ "VAGTP20_DynConnection" BO_ 1936 1;
BA_ "GenMsgAutoGenSnd" BO_ 1936 0;
BA_ "GenMsgAutoGenDsp" BO_ 1936 0;
BA_ "VAGTP20_DynConnection" BO_ 1937 1;
BA_ "GenMsgAutoGenSnd" BO_ 1937 0;
BA_ "GenMsgAutoGenDsp" BO_ 1937 0;
BA_ "VAGTP20_DynConnection" BO_ 1904 1;
BA_ "GenMsgAutoGenSnd" BO_ 1904 0;
BA_ "GenMsgAutoGenDsp" BO_ 1904 0;
BA_ "VAGTP20_DynConnection" BO_ 1896 1;
BA_ "GenMsgAutoGenSnd" BO_ 1896 0;
BA_ "GenMsgAutoGenDsp" BO_ 1896 0;
BA_ "VAGTP20_DynConnection" BO_ 1892 1;
BA_ "GenMsgAutoGenSnd" BO_ 1892 0;
BA_ "GenMsgAutoGenDsp" BO_ 1892 0;
BA_ "VAGTP20_DynConnection" BO_ 1906 1;
BA_ "GenMsgAutoGenSnd" BO_ 1906 0;
BA_ "GenMsgAutoGenDsp" BO_ 1906 0;
BA_ "VAGTP20_DynConnection" BO_ 768 1;
BA_ "GenMsgAutoGenSnd" BO_ 768 0;
BA_ "GenMsgAutoGenDsp" BO_ 768 0;
BA_ "VAGTP20_DynConnection" BO_ 769 1;
BA_ "GenMsgAutoGenSnd" BO_ 769 0;
BA_ "GenMsgAutoGenDsp" BO_ 769 0;
BA_ "VAGTP20_DynConnection" BO_ 770 1;
BA_ "GenMsgAutoGenSnd" BO_ 770 0;
BA_ "GenMsgAutoGenDsp" BO_ 770 0;
BA_ "VAGTP20_DynConnection" BO_ 771 1;
BA_ "GenMsgAutoGenSnd" BO_ 771 0;
BA_ "GenMsgAutoGenDsp" BO_ 771 0;
BA_ "VAGTP20_DynConnection" BO_ 772 1;
BA_ "GenMsgAutoGenSnd" BO_ 772 0;
BA_ "GenMsgAutoGenDsp" BO_ 772 0;
BA_ "VAGTP20_DynConnection" BO_ 773 1;
BA_ "GenMsgAutoGenSnd" BO_ 773 0;
BA_ "GenMsgAutoGenDsp" BO_ 773 0;
BA_ "VAGTP20_DynConnection" BO_ 774 1;
BA_ "GenMsgAutoGenSnd" BO_ 774 0;
BA_ "GenMsgAutoGenDsp" BO_ 774 0;
BA_ "VAGTP20_DynConnection" BO_ 775 1;
BA_ "GenMsgAutoGenSnd" BO_ 775 0;
BA_ "GenMsgAutoGenDsp" BO_ 775 0;
BA_ "VAGTP20_DynConnection" BO_ 1940 1;
BA_ "GenMsgAutoGenSnd" BO_ 1940 0;
BA_ "GenMsgAutoGenDsp" BO_ 1940 0;
BA_ "VAGTP20_DynConnection" BO_ 1864 1;
BA_ "GenMsgAutoGenSnd" BO_ 1864 0;
BA_ "GenMsgAutoGenDsp" BO_ 1864 0;
BA_ "VAGTP20_DynConnection" BO_ 1888 1;
BA_ "GenMsgAutoGenSnd" BO_ 1888 0;
BA_ "GenMsgAutoGenDsp" BO_ 1888 0;
BA_ "VAGTP20_DynConnection" BO_ 1889 1;
BA_ "GenMsgAutoGenSnd" BO_ 1889 0;
BA_ "GenMsgAutoGenDsp" BO_ 1889 0;
BA_ "VAGTP20_DynConnection" BO_ 1956 1;
BA_ "GenMsgAutoGenSnd" BO_ 1956 0;
BA_ "GenMsgAutoGenDsp" BO_ 1956 0;
BA_ "VAGTP20_DynConnection" BO_ 1957 1;
BA_ "GenMsgAutoGenSnd" BO_ 1957 0;
BA_ "GenMsgAutoGenDsp" BO_ 1957 0;
BA_ "VAGTP20_DynConnection" BO_ 1960 1;
BA_ "GenMsgAutoGenSnd" BO_ 1960 0;
BA_ "GenMsgAutoGenDsp" BO_ 1960 0;
BA_ "VAGTP20_DynConnection" BO_ 1961 1;
BA_ "GenMsgAutoGenSnd" BO_ 1961 0;
BA_ "GenMsgAutoGenDsp" BO_ 1961 0;
BA_ "VAGTP20_DynConnection" BO_ 1924 1;
BA_ "GenMsgAutoGenSnd" BO_ 1924 0;
BA_ "GenMsgAutoGenDsp" BO_ 1924 0;
BA_ "VAGTP20_DynConnection" BO_ 1925 1;
BA_ "GenMsgAutoGenSnd" BO_ 1925 0;
BA_ "GenMsgAutoGenDsp" BO_ 1925 0;
BA_ "VAGTP20_DynConnection" BO_ 1952 1;
BA_ "GenMsgAutoGenSnd" BO_ 1952 0;
BA_ "GenMsgAutoGenDsp" BO_ 1952 0;
BA_ "VAGTP20_DynConnection" BO_ 1856 1;
BA_ "GenMsgAutoGenSnd" BO_ 1856 0;
BA_ "GenMsgAutoGenDsp" BO_ 1856 0;
BA_ "VAGTP20_DynConnection" BO_ 1857 1;
BA_ "GenMsgAutoGenSnd" BO_ 1857 0;
BA_ "GenMsgAutoGenDsp" BO_ 1857 0;
BA_ "VAGTP20_DynConnection" BO_ 1858 1;
BA_ "GenMsgAutoGenSnd" BO_ 1858 0;
BA_ "GenMsgAutoGenDsp" BO_ 1858 0;
BA_ "VAGTP20_DynConnection" BO_ 1859 1;
BA_ "GenMsgAutoGenSnd" BO_ 1859 0;
BA_ "GenMsgAutoGenDsp" BO_ 1859 0;
BA_ "VAGTP20_DynConnection" BO_ 1978 1;
BA_ "GenMsgAutoGenSnd" BO_ 1978 0;
BA_ "GenMsgAutoGenDsp" BO_ 1978 0;
BA_ "VAGTP20_DynConnection" BO_ 1880 1;
BA_ "GenMsgAutoGenSnd" BO_ 1880 0;
BA_ "GenMsgAutoGenDsp" BO_ 1880 0;
BA_ "VAGTP20_DynConnection" BO_ 1881 1;
BA_ "GenMsgAutoGenSnd" BO_ 1881 0;
BA_ "GenMsgAutoGenDsp" BO_ 1881 0;
BA_ "VAGTP20_DynConnection" BO_ 1875 1;
BA_ "GenMsgAutoGenSnd" BO_ 1875 0;
BA_ "GenMsgAutoGenDsp" BO_ 1875 0;
BA_ "VAGTP20_DynSetup" BO_ 515 1;
BA_ "GenMsgAutoGenSnd" BO_ 515 0;
BA_ "GenMsgAutoGenDsp" BO_ 515 0;
BA_ "VAGTP20_DynSetup" BO_ 523 1;
BA_ "GenMsgAutoGenSnd" BO_ 523 0;
BA_ "GenMsgAutoGenDsp" BO_ 523 0;
BA_ "VAGTP20_DynSetup" BO_ 517 1;
BA_ "GenMsgAutoGenSnd" BO_ 517 0;
BA_ "GenMsgAutoGenDsp" BO_ 517 0;
BA_ "VAGTP20_DynSetup" BO_ 522 1;
BA_ "GenMsgAutoGenSnd" BO_ 522 0;
BA_ "GenMsgAutoGenDsp" BO_ 522 0;
BA_ "VAGTP20_DynSetup" BO_ 524 1;
BA_ "GenMsgAutoGenSnd" BO_ 524 0;
BA_ "GenMsgAutoGenDsp" BO_ 524 0;
BA_ "VAGTP20_DynSetup" BO_ 537 1;
BA_ "GenMsgAutoGenSnd" BO_ 537 0;
BA_ "GenMsgAutoGenDsp" BO_ 537 0;
BA_ "VAGTP20_DynSetup" BO_ 534 1;
BA_ "GenMsgAutoGenSnd" BO_ 534 0;
BA_ "GenMsgAutoGenDsp" BO_ 534 0;
BA_ "VAGTP20_DynSetup" BO_ 514 1;
BA_ "GenMsgAutoGenSnd" BO_ 514 0;
BA_ "GenMsgAutoGenDsp" BO_ 514 0;
BA_ "VAGTP20_DynSetup" BO_ 538 1;
BA_ "GenMsgAutoGenSnd" BO_ 538 0;
BA_ "GenMsgAutoGenDsp" BO_ 538 0;
BA_ "VAGTP20_DynSetup" BO_ 521 1;
BA_ "GenMsgAutoGenSnd" BO_ 521 0;
BA_ "GenMsgAutoGenDsp" BO_ 521 0;
BA_ "VAGTP20_DynSetup" BO_ 518 1;
BA_ "GenMsgAutoGenSnd" BO_ 518 0;
BA_ "GenMsgAutoGenDsp" BO_ 518 0;
BA_ "VAGTP20_DynSetup" BO_ 531 1;
BA_ "GenMsgAutoGenSnd" BO_ 531 0;
BA_ "GenMsgAutoGenDsp" BO_ 531 0;
BA_ "VAGTP20_DynSetup" BO_ 513 1;
BA_ "GenMsgAutoGenSnd" BO_ 513 0;
BA_ "GenMsgAutoGenDsp" BO_ 513 0;
BA_ "VAGTP20_DynSetup" BO_ 541 1;
BA_ "GenMsgAutoGenSnd" BO_ 541 0;
BA_ "GenMsgAutoGenDsp" BO_ 541 0;
BA_ "VAGTP20_DynSetup" BO_ 536 1;
BA_ "GenMsgAutoGenSnd" BO_ 536 0;
BA_ "GenMsgAutoGenDsp" BO_ 536 0;
BA_ "VAGTP20_DynSetup" BO_ 520 1;
BA_ "GenMsgAutoGenSnd" BO_ 520 0;
BA_ "GenMsgAutoGenDsp" BO_ 520 0;
BA_ "VAGTP20_DynSetup" BO_ 512 1;
BA_ "GenMsgAutoGenSnd" BO_ 512 0;
BA_ "GenMsgAutoGenDsp" BO_ 512 0;
BA_ "GenMsgSendType" BO_ 1096 0;
BA_ "GenMsgILSupport" BO_ 1096 1;
BA_ "GenMsgCycleTime" BO_ 1096 10;
BA_ "GenMsgSendType" BO_ 1102 0;
BA_ "GenMsgILSupport" BO_ 1102 1;
BA_ "GenMsgCycleTime" BO_ 1102 10;
BA_ "GenMsgSendType" BO_ 1394 0;
BA_ "GenMsgILSupport" BO_ 1394 1;
BA_ "GenMsgDelayTime" BO_ 1394 10;
BA_ "GenMsgCycleTime" BO_ 1394 100;
BA_ "GenMsgSendType" BO_ 919 0;
BA_ "GenMsgILSupport" BO_ 919 1;
BA_ "GenMsgCycleTime" BO_ 919 100;
BA_ "NmhMessage" BO_ 1827 1;
BA_ "GenMsgCycleTime" BO_ 1827 200;
BA_ "GenMsgAutoGenSnd" BO_ 1827 0;
BA_ "GenMsgAutoGenDsp" BO_ 1827 0;
BA_ "NmhMessage" BO_ 1838 1;
BA_ "GenMsgCycleTime" BO_ 1838 200;
BA_ "GenMsgAutoGenSnd" BO_ 1838 0;
BA_ "GenMsgAutoGenDsp" BO_ 1838 0;
BA_ "NmhMessage" BO_ 1839 1;
BA_ "GenMsgCycleTime" BO_ 1839 200;
BA_ "GenMsgAutoGenSnd" BO_ 1839 0;
BA_ "GenMsgAutoGenDsp" BO_ 1839 0;
BA_ "NmhMessage" BO_ 1849 1;
BA_ "GenMsgCycleTime" BO_ 1849 200;
BA_ "GenMsgAutoGenSnd" BO_ 1849 0;
BA_ "GenMsgAutoGenDsp" BO_ 1849 0;
BA_ "NmhMessage" BO_ 1824 1;
BA_ "GenMsgCycleTime" BO_ 1824 200;
BA_ "GenMsgAutoGenSnd" BO_ 1824 0;
BA_ "GenMsgAutoGenDsp" BO_ 1824 0;
BA_ "NmhMessage" BO_ 1836 1;
BA_ "GenMsgCycleTime" BO_ 1836 200;
BA_ "GenMsgAutoGenSnd" BO_ 1836 0;
BA_ "GenMsgAutoGenDsp" BO_ 1836 0;
BA_ "NmhMessage" BO_ 1825 1;
BA_ "GenMsgCycleTime" BO_ 1825 200;
BA_ "GenMsgAutoGenSnd" BO_ 1825 0;
BA_ "GenMsgAutoGenDsp" BO_ 1825 0;
BA_ "GenMsgSendType" BO_ 1523 0;
BA_ "GenMsgILSupport" BO_ 1523 1;
BA_ "GenMsgCycleTime" BO_ 1523 500;
BA_ "GenMsgSendType" BO_ 1175 0;
BA_ "GenMsgILSupport" BO_ 1175 1;
BA_ "GenMsgDelayTime" BO_ 1175 50;
BA_ "GenMsgCycleTime" BO_ 1175 100;
BA_ "GenSigSwitchedByIgnition" SG_ 1306 TOG_Zaehler 0;
BA_ "GenSigSendType" SG_ 1306 TOG_Zaehler 0;
BA_ "GenSigAutoGenSnd" SG_ 1306 TOG_Zaehler 1;
BA_ "GenSigAutoGenDsp" SG_ 1306 TOG_Zaehler 1;
BA_ "GenSigSwitchedByIgnition" SG_ 1306 TOG_Fuellstand_1 0;
BA_ "GenSigStartValue" SG_ 1306 TOG_Fuellstand_1 1;
BA_ "GenSigSendType" SG_ 1306 TOG_Fuellstand_1 0;
BA_ "GenSigAutoGenSnd" SG_ 1306 TOG_Fuellstand_1 1;
BA_ "GenSigAutoGenDsp" SG_ 1306 TOG_Fuellstand_1 1;
BA_ "GenSigSwitchedByIgnition" SG_ 1306 TOG_Fuellstand_2 0;
BA_ "GenSigStartValue" SG_ 1306 TOG_Fuellstand_2 1;
BA_ "GenSigSendType" SG_ 1306 TOG_Fuellstand_2 0;
BA_ "GenSigAutoGenSnd" SG_ 1306 TOG_Fuellstand_2 1;
BA_ "GenSigAutoGenDsp" SG_ 1306 TOG_Fuellstand_2 1;
BA_ "GenSigSwitchedByIgnition" SG_ 1306 TOG_Fuellstand_3 0;
BA_ "GenSigStartValue" SG_ 1306 TOG_Fuellstand_3 1;
BA_ "GenSigSendType" SG_ 1306 TOG_Fuellstand_3 0;
BA_ "GenSigAutoGenSnd" SG_ 1306 TOG_Fuellstand_3 1;
BA_ "GenSigAutoGenDsp" SG_ 1306 TOG_Fuellstand_3 1;
BA_ "GenSigSwitchedByIgnition" SG_ 1306 TOG_Fuellstand_4 0;
BA_ "GenSigStartValue" SG_ 1306 TOG_Fuellstand_4 1;
BA_ "GenSigSendType" SG_ 1306 TOG_Fuellstand_4 0;
BA_ "GenSigAutoGenSnd" SG_ 1306 TOG_Fuellstand_4 1;
BA_ "GenSigAutoGenDsp" SG_ 1306 TOG_Fuellstand_4 1;
BA_ "GenSigSwitchedByIgnition" SG_ 1306 TOG_Oeltempzeit 0;
BA_ "GenSigStartValue" SG_ 1306 TOG_Oeltempzeit 1;
BA_ "GenSigSendType" SG_ 1306 TOG_Oeltempzeit 0;
BA_ "GenSigAutoGenSnd" SG_ 1306 TOG_Oeltempzeit 1;
BA_ "GenSigAutoGenDsp" SG_ 1306 TOG_Oeltempzeit 1;
BA_ "Fehlerwert" SG_ 1306 TOG_Sensorfehler 1;
BA_ "GenSigSwitchedByIgnition" SG_ 1306 TOG_Sensorfehler 0;
BA_ "GenSigSendType" SG_ 1306 TOG_Sensorfehler 0;
BA_ "GenSigAutoGenSnd" SG_ 1306 TOG_Sensorfehler 1;
BA_ "GenSigAutoGenDsp" SG_ 1306 TOG_Sensorfehler 1;
BA_ "GenSigSwitchedByIgnition" SG_ 1306 TOG_Oelwarn_hoch 0;
BA_ "GenSigSendType" SG_ 1306 TOG_Oelwarn_hoch 0;
BA_ "GenSigAutoGenSnd" SG_ 1306 TOG_Oelwarn_hoch 1;
BA_ "GenSigAutoGenDsp" SG_ 1306 TOG_Oelwarn_hoch 1;
BA_ "GenSigSwitchedByIgnition" SG_ 1306 TOG_OelwarnUeber 0;
BA_ "GenSigSendType" SG_ 1306 TOG_OelwarnUeber 0;
BA_ "GenSigAutoGenSnd" SG_ 1306 TOG_OelwarnUeber 1;
BA_ "GenSigAutoGenDsp" SG_ 1306 TOG_OelwarnUeber 1;
BA_ "GenSigSwitchedByIgnition" SG_ 1306 TOG_OelmaxUeber 0;
BA_ "GenSigSendType" SG_ 1306 TOG_OelmaxUeber 0;
BA_ "GenSigAutoGenSnd" SG_ 1306 TOG_OelmaxUeber 1;
BA_ "GenSigAutoGenDsp" SG_ 1306 TOG_OelmaxUeber 1;
BA_ "GenSigSwitchedByIgnition" SG_ 1306 TOG_Oelmax_hoch 0;
BA_ "GenSigSendType" SG_ 1306 TOG_Oelmax_hoch 0;
BA_ "GenSigAutoGenSnd" SG_ 1306 TOG_Oelmax_hoch 1;
BA_ "GenSigAutoGenDsp" SG_ 1306 TOG_Oelmax_hoch 1;
BA_ "GenSigSwitchedByIgnition" SG_ 1936 TPDyn_ABS_1 0;
BA_ "GenSigSendType" SG_ 1936 TPDyn_ABS_1 3;
BA_ "GenSigAutoGenSnd" SG_ 1936 TPDyn_ABS_1 1;
BA_ "GenSigAutoGenDsp" SG_ 1936 TPDyn_ABS_1 1;
BA_ "GenSigSwitchedByIgnition" SG_ 1937 TPDyn_ABS_2 0;
BA_ "GenSigSendType" SG_ 1937 TPDyn_ABS_2 3;
BA_ "GenSigAutoGenSnd" SG_ 1937 TPDyn_ABS_2 1;
BA_ "GenSigAutoGenDsp" SG_ 1937 TPDyn_ABS_2 1;
BA_ "GenSigSwitchedByIgnition" SG_ 1904 TPDyn_ADR_1 0;
BA_ "GenSigSendType" SG_ 1904 TPDyn_ADR_1 3;
BA_ "GenSigAutoGenSnd" SG_ 1904 TPDyn_ADR_1 1;
BA_ "GenSigAutoGenDsp" SG_ 1904 TPDyn_ADR_1 1;
BA_ "GenSigSwitchedByIgnition" SG_ 1896 TPDyn_Airbag_1 0;
BA_ "GenSigSendType" SG_ 1896 TPDyn_Airbag_1 3;
BA_ "GenSigAutoGenSnd" SG_ 1896 TPDyn_Airbag_1 1;
BA_ "GenSigAutoGenDsp" SG_ 1896 TPDyn_Airbag_1 1;
BA_ "GenSigSwitchedByIgnition" SG_ 1892 TPDyn_Allrad_1 0;
BA_ "GenSigSendType" SG_ 1892 TPDyn_Allrad_1 3;
BA_ "GenSigAutoGenSnd" SG_ 1892 TPDyn_Allrad_1 1;
BA_ "GenSigAutoGenDsp" SG_ 1892 TPDyn_Allrad_1 1;
BA_ "GenSigSwitchedByIgnition" SG_ 1906 TPDyn_Daempfer_1 0;
BA_ "GenSigSendType" SG_ 1906 TPDyn_Daempfer_1 3;
BA_ "GenSigAutoGenSnd" SG_ 1906 TPDyn_Daempfer_1 1;
BA_ "GenSigAutoGenDsp" SG_ 1906 TPDyn_Daempfer_1 1;
BA_ "GenSigSwitchedByIgnition" SG_ 768 TPDyn_Diag_1_1 0;
BA_ "GenSigSendType" SG_ 768 TPDyn_Diag_1_1 3;
BA_ "GenSigAutoGenSnd" SG_ 768 TPDyn_Diag_1_1 1;
BA_ "GenSigAutoGenDsp" SG_ 768 TPDyn_Diag_1_1 1;
BA_ "GenSigSwitchedByIgnition" SG_ 769 TPDyn_Diag_1_2 0;
BA_ "GenSigSendType" SG_ 769 TPDyn_Diag_1_2 3;
BA_ "GenSigAutoGenSnd" SG_ 769 TPDyn_Diag_1_2 1;
BA_ "GenSigAutoGenDsp" SG_ 769 TPDyn_Diag_1_2 1;
BA_ "GenSigSwitchedByIgnition" SG_ 770 TPDyn_Diag_1_3 0;
BA_ "GenSigSendType" SG_ 770 TPDyn_Diag_1_3 3;
BA_ "GenSigAutoGenSnd" SG_ 770 TPDyn_Diag_1_3 1;
BA_ "GenSigAutoGenDsp" SG_ 770 TPDyn_Diag_1_3 1;
BA_ "GenSigSwitchedByIgnition" SG_ 771 TPDyn_Diag_1_4 0;
BA_ "GenSigSendType" SG_ 771 TPDyn_Diag_1_4 3;
BA_ "GenSigAutoGenSnd" SG_ 771 TPDyn_Diag_1_4 1;
BA_ "GenSigAutoGenDsp" SG_ 771 TPDyn_Diag_1_4 1;
BA_ "GenSigSwitchedByIgnition" SG_ 772 TPDyn_Diag_1_5 0;
BA_ "GenSigSendType" SG_ 772 TPDyn_Diag_1_5 3;
BA_ "GenSigAutoGenSnd" SG_ 772 TPDyn_Diag_1_5 1;
BA_ "GenSigAutoGenDsp" SG_ 772 TPDyn_Diag_1_5 1;
BA_ "GenSigSwitchedByIgnition" SG_ 773 TPDyn_Diag_1_6 0;
BA_ "GenSigSendType" SG_ 773 TPDyn_Diag_1_6 3;
BA_ "GenSigAutoGenSnd" SG_ 773 TPDyn_Diag_1_6 1;
BA_ "GenSigAutoGenDsp" SG_ 773 TPDyn_Diag_1_6 1;
BA_ "GenSigSwitchedByIgnition" SG_ 774 TPDyn_Diag_1_7 0;
BA_ "GenSigSendType" SG_ 774 TPDyn_Diag_1_7 3;
BA_ "GenSigAutoGenSnd" SG_ 774 TPDyn_Diag_1_7 1;
BA_ "GenSigAutoGenDsp" SG_ 774 TPDyn_Diag_1_7 1;
BA_ "GenSigSwitchedByIgnition" SG_ 775 TPDyn_Diag_1_8 0;
BA_ "GenSigSendType" SG_ 775 TPDyn_Diag_1_8 3;
BA_ "GenSigAutoGenSnd" SG_ 775 TPDyn_Diag_1_8 1;
BA_ "GenSigAutoGenDsp" SG_ 775 TPDyn_Diag_1_8 1;
BA_ "GenSigSwitchedByIgnition" SG_ 1940 TPDyn_EPB_1 0;
BA_ "GenSigSendType" SG_ 1940 TPDyn_EPB_1 3;
BA_ "GenSigAutoGenSnd" SG_ 1940 TPDyn_EPB_1 1;
BA_ "GenSigAutoGenDsp" SG_ 1940 TPDyn_EPB_1 1;
BA_ "GenSigSwitchedByIgnition" SG_ 1864 TPDyn_FLA_1 0;
BA_ "GenSigSendType" SG_ 1864 TPDyn_FLA_1 3;
BA_ "GenSigAutoGenSnd" SG_ 1864 TPDyn_FLA_1 1;
BA_ "GenSigAutoGenDsp" SG_ 1864 TPDyn_FLA_1 1;
BA_ "GenSigSwitchedByIgnition" SG_ 1888 TPDyn_Getriebe_1 0;
BA_ "GenSigSendType" SG_ 1888 TPDyn_Getriebe_1 3;
BA_ "GenSigAutoGenSnd" SG_ 1888 TPDyn_Getriebe_1 1;
BA_ "GenSigAutoGenDsp" SG_ 1888 TPDyn_Getriebe_1 1;
BA_ "GenSigSwitchedByIgnition" SG_ 1889 TPDyn_Getriebe_2 0;
BA_ "GenSigSendType" SG_ 1889 TPDyn_Getriebe_2 3;
BA_ "GenSigAutoGenSnd" SG_ 1889 TPDyn_Getriebe_2 1;
BA_ "GenSigAutoGenDsp" SG_ 1889 TPDyn_Getriebe_2 1;
BA_ "GenSigSwitchedByIgnition" SG_ 1956 TPDyn_LDW_1 0;
BA_ "GenSigSendType" SG_ 1956 TPDyn_LDW_1 3;
BA_ "GenSigAutoGenSnd" SG_ 1956 TPDyn_LDW_1 1;
BA_ "GenSigAutoGenDsp" SG_ 1956 TPDyn_LDW_1 1;
BA_ "GenSigSwitchedByIgnition" SG_ 1957 TPDyn_LDW_2 0;
BA_ "GenSigSendType" SG_ 1957 TPDyn_LDW_2 3;
BA_ "GenSigAutoGenSnd" SG_ 1957 TPDyn_LDW_2 1;
BA_ "GenSigAutoGenDsp" SG_ 1957 TPDyn_LDW_2 1;
BA_ "GenSigSwitchedByIgnition" SG_ 1960 TPDyn_Lenkhilfe_1 0;
BA_ "GenSigSendType" SG_ 1960 TPDyn_Lenkhilfe_1 3;
BA_ "GenSigAutoGenSnd" SG_ 1960 TPDyn_Lenkhilfe_1 1;
BA_ "GenSigAutoGenDsp" SG_ 1960 TPDyn_Lenkhilfe_1 1;
BA_ "GenSigSwitchedByIgnition" SG_ 1961 TPDyn_Lenkhilfe_2 0;
BA_ "GenSigSendType" SG_ 1961 TPDyn_Lenkhilfe_2 3;
BA_ "GenSigAutoGenSnd" SG_ 1961 TPDyn_Lenkhilfe_2 1;
BA_ "GenSigAutoGenDsp" SG_ 1961 TPDyn_Lenkhilfe_2 1;
BA_ "GenSigSwitchedByIgnition" SG_ 1924 TPDyn_Dyn_LWR_1 0;
BA_ "GenSigSendType" SG_ 1924 TPDyn_Dyn_LWR_1 3;
BA_ "GenSigAutoGenSnd" SG_ 1924 TPDyn_Dyn_LWR_1 1;
BA_ "GenSigAutoGenDsp" SG_ 1924 TPDyn_Dyn_LWR_1 1;
BA_ "GenSigSwitchedByIgnition" SG_ 1925 TPDyn_Dyn_LWR_2 0;
BA_ "GenSigSendType" SG_ 1925 TPDyn_Dyn_LWR_2 3;
BA_ "GenSigAutoGenSnd" SG_ 1925 TPDyn_Dyn_LWR_2 1;
BA_ "GenSigAutoGenDsp" SG_ 1925 TPDyn_Dyn_LWR_2 1;
BA_ "GenSigSwitchedByIgnition" SG_ 1952 TPDyn_LWS 0;
BA_ "GenSigSendType" SG_ 1952 TPDyn_LWS 3;
BA_ "GenSigAutoGenSnd" SG_ 1952 TPDyn_LWS 1;
BA_ "GenSigAutoGenDsp" SG_ 1952 TPDyn_LWS 1;
BA_ "GenSigSwitchedByIgnition" SG_ 1856 TPDyn_Motor_1 0;
BA_ "GenSigSendType" SG_ 1856 TPDyn_Motor_1 3;
BA_ "GenSigAutoGenSnd" SG_ 1856 TPDyn_Motor_1 1;
BA_ "GenSigAutoGenDsp" SG_ 1856 TPDyn_Motor_1 1;
BA_ "GenSigSwitchedByIgnition" SG_ 1857 TPDyn_Motor_2 0;
BA_ "GenSigSendType" SG_ 1857 TPDyn_Motor_2 3;
BA_ "GenSigAutoGenSnd" SG_ 1857 TPDyn_Motor_2 1;
BA_ "GenSigAutoGenDsp" SG_ 1857 TPDyn_Motor_2 1;
BA_ "GenSigSwitchedByIgnition" SG_ 1858 TPDyn_Motor_3 0;
BA_ "GenSigSendType" SG_ 1858 TPDyn_Motor_3 3;
BA_ "GenSigAutoGenSnd" SG_ 1858 TPDyn_Motor_3 1;
BA_ "GenSigAutoGenDsp" SG_ 1858 TPDyn_Motor_3 1;
BA_ "GenSigSwitchedByIgnition" SG_ 1859 TPDyn_Motor_4 0;
BA_ "GenSigSendType" SG_ 1859 TPDyn_Motor_4 3;
BA_ "GenSigAutoGenSnd" SG_ 1859 TPDyn_Motor_4 1;
BA_ "GenSigAutoGenDsp" SG_ 1859 TPDyn_Motor_4 1;
BA_ "GenSigSwitchedByIgnition" SG_ 1978 TPDyn_PLA_PDC 0;
BA_ "GenSigSendType" SG_ 1978 TPDyn_PLA_PDC 3;
BA_ "GenSigAutoGenSnd" SG_ 1978 TPDyn_PLA_PDC 1;
BA_ "GenSigAutoGenDsp" SG_ 1978 TPDyn_PLA_PDC 1;
BA_ "GenSigSwitchedByIgnition" SG_ 1880 TPDyn_Quersperre_1 0;
BA_ "GenSigSendType" SG_ 1880 TPDyn_Quersperre_1 3;
BA_ "GenSigAutoGenSnd" SG_ 1880 TPDyn_Quersperre_1 1;
BA_ "GenSigAutoGenDsp" SG_ 1880 TPDyn_Quersperre_1 1;
BA_ "GenSigSwitchedByIgnition" SG_ 1881 TPDyn_Quersperre_2 0;
BA_ "GenSigSendType" SG_ 1881 TPDyn_Quersperre_2 3;
BA_ "GenSigAutoGenSnd" SG_ 1881 TPDyn_Quersperre_2 1;
BA_ "GenSigAutoGenDsp" SG_ 1881 TPDyn_Quersperre_2 1;
BA_ "GenSigSwitchedByIgnition" SG_ 1875 TPDyn_RKA_Plus_2 0;
BA_ "GenSigSendType" SG_ 1875 TPDyn_RKA_Plus_2 3;
BA_ "GenSigAutoGenSnd" SG_ 1875 TPDyn_RKA_Plus_2 1;
BA_ "GenSigAutoGenDsp" SG_ 1875 TPDyn_RKA_Plus_2 1;
BA_ "GenSigSwitchedByIgnition" SG_ 515 ABS_TP_Er 0;
BA_ "GenSigSendType" SG_ 515 ABS_TP_Er 3;
BA_ "GenSigAutoGenSnd" SG_ 515 ABS_TP_Er 1;
BA_ "GenSigAutoGenDsp" SG_ 515 ABS_TP_Er 1;
BA_ "GenSigSwitchedByIgnition" SG_ 523 ADR_TP_Er 0;
BA_ "GenSigSendType" SG_ 523 ADR_TP_Er 3;
BA_ "GenSigAutoGenSnd" SG_ 523 ADR_TP_Er 1;
BA_ "GenSigAutoGenDsp" SG_ 523 ADR_TP_Er 1;
BA_ "GenSigSwitchedByIgnition" SG_ 517 Airbag_TP_Er 0;
BA_ "GenSigSendType" SG_ 517 Airbag_TP_Er 3;
BA_ "GenSigAutoGenSnd" SG_ 517 Airbag_TP_Er 1;
BA_ "GenSigAutoGenDsp" SG_ 517 Airbag_TP_Er 1;
BA_ "GenSigSwitchedByIgnition" SG_ 522 Allrad_TP_Er 0;
BA_ "GenSigSendType" SG_ 522 Allrad_TP_Er 3;
BA_ "GenSigAutoGenSnd" SG_ 522 Allrad_TP_Er 1;
BA_ "GenSigAutoGenDsp" SG_ 522 Allrad_TP_Er 1;
BA_ "GenSigSwitchedByIgnition" SG_ 524 Daempfer_TP_Er 0;
BA_ "GenSigSendType" SG_ 524 Daempfer_TP_Er 3;
BA_ "GenSigAutoGenSnd" SG_ 524 Daempfer_TP_Er 1;
BA_ "GenSigAutoGenDsp" SG_ 524 Daempfer_TP_Er 1;
BA_ "GenSigSwitchedByIgnition" SG_ 537 EPB_TP_Er 0;
BA_ "GenSigSendType" SG_ 537 EPB_TP_Er 3;
BA_ "GenSigAutoGenSnd" SG_ 537 EPB_TP_Er 1;
BA_ "GenSigAutoGenDsp" SG_ 537 EPB_TP_Er 1;
BA_ "GenSigSwitchedByIgnition" SG_ 534 FLA_TP_Er 0;
BA_ "GenSigSendType" SG_ 534 FLA_TP_Er 3;
BA_ "GenSigAutoGenSnd" SG_ 534 FLA_TP_Er 1;
BA_ "GenSigAutoGenDsp" SG_ 534 FLA_TP_Er 1;
BA_ "GenSigSwitchedByIgnition" SG_ 514 Getriebe_TP_Er 0;
BA_ "GenSigSendType" SG_ 514 Getriebe_TP_Er 3;
BA_ "GenSigAutoGenSnd" SG_ 514 Getriebe_TP_Er 1;
BA_ "GenSigAutoGenDsp" SG_ 514 Getriebe_TP_Er 1;
BA_ "GenSigSwitchedByIgnition" SG_ 538 LDW_TP_Er 0;
BA_ "GenSigSendType" SG_ 538 LDW_TP_Er 3;
BA_ "GenSigAutoGenSnd" SG_ 538 LDW_TP_Er 1;
BA_ "GenSigAutoGenDsp" SG_ 538 LDW_TP_Er 1;
BA_ "GenSigSwitchedByIgnition" SG_ 521 Lenkhilfe_TP_Er 0;
BA_ "GenSigSendType" SG_ 521 Lenkhilfe_TP_Er 3;
BA_ "GenSigAutoGenSnd" SG_ 521 Lenkhilfe_TP_Er 1;
BA_ "GenSigAutoGenDsp" SG_ 521 Lenkhilfe_TP_Er 1;
BA_ "GenSigSwitchedByIgnition" SG_ 518 Dyn_LWR_TP_Er 0;
BA_ "GenSigSendType" SG_ 518 Dyn_LWR_TP_Er 3;
BA_ "GenSigAutoGenSnd" SG_ 518 Dyn_LWR_TP_Er 1;
BA_ "GenSigAutoGenDsp" SG_ 518 Dyn_LWR_TP_Er 1;
BA_ "GenSigSwitchedByIgnition" SG_ 531 LWS_TP_Er 0;
BA_ "GenSigSendType" SG_ 531 LWS_TP_Er 3;
BA_ "GenSigAutoGenSnd" SG_ 531 LWS_TP_Er 1;
BA_ "GenSigAutoGenDsp" SG_ 531 LWS_TP_Er 1;
BA_ "GenSigSwitchedByIgnition" SG_ 513 Motor_TP_Er 0;
BA_ "GenSigSendType" SG_ 513 Motor_TP_Er 3;
BA_ "GenSigAutoGenSnd" SG_ 513 Motor_TP_Er 1;
BA_ "GenSigAutoGenDsp" SG_ 513 Motor_TP_Er 1;
BA_ "GenSigSwitchedByIgnition" SG_ 541 PLA_PDC_TP_Er 0;
BA_ "GenSigSendType" SG_ 541 PLA_PDC_TP_Er 3;
BA_ "GenSigAutoGenSnd" SG_ 541 PLA_PDC_TP_Er 1;
BA_ "GenSigAutoGenDsp" SG_ 541 PLA_PDC_TP_Er 1;
BA_ "GenSigSwitchedByIgnition" SG_ 536 Quersperre_TP_Er 0;
BA_ "GenSigSendType" SG_ 536 Quersperre_TP_Er 3;
BA_ "GenSigAutoGenSnd" SG_ 536 Quersperre_TP_Er 1;
BA_ "GenSigAutoGenDsp" SG_ 536 Quersperre_TP_Er 1;
BA_ "GenSigSwitchedByIgnition" SG_ 520 RKA_Plus_TP_Er 0;
BA_ "GenSigSendType" SG_ 520 RKA_Plus_TP_Er 3;
BA_ "GenSigAutoGenSnd" SG_ 520 RKA_Plus_TP_Er 1;
BA_ "GenSigAutoGenDsp" SG_ 520 RKA_Plus_TP_Er 1;
BA_ "GenSigSwitchedByIgnition" SG_ 512 Tester_TP_Er 0;
BA_ "GenSigSendType" SG_ 512 Tester_TP_Er 3;
BA_ "GenSigAutoGenSnd" SG_ 512 Tester_TP_Er 1;
BA_ "GenSigAutoGenDsp" SG_ 512 Tester_TP_Er 1;
BA_ "GenSigSwitchedByIgnition" SG_ 1096 WH1_StaShiftlock 0;
BA_ "GenSigSendType" SG_ 1096 WH1_StaShiftlock 0;
BA_ "GenSigAutoGenSnd" SG_ 1096 WH1_StaShiftlock 1;
BA_ "GenSigAutoGenDsp" SG_ 1096 WH1_StaShiftlock 1;
BA_ "GenSigSwitchedByIgnition" SG_ 1096 WH1_Init 0;
BA_ "GenSigStartValue" SG_ 1096 WH1_Init 1;
BA_ "GenSigSendType" SG_ 1096 WH1_Init 0;
BA_ "GenSigAutoGenSnd" SG_ 1096 WH1_Init 1;
BA_ "GenSigAutoGenDsp" SG_ 1096 WH1_Init 1;
BA_ "Fehlerwert" SG_ 1096 WH1_Position 15;
BA_ "GenSigSwitchedByIgnition" SG_ 1096 WH1_Position 0;
BA_ "GenSigSendType" SG_ 1096 WH1_Position 0;
BA_ "GenSigAutoGenSnd" SG_ 1096 WH1_Position 1;
BA_ "GenSigAutoGenDsp" SG_ 1096 WH1_Position 1;
BA_ "GenSigSwitchedByIgnition" SG_ 1096 WH1_Status 0;
BA_ "GenSigSendType" SG_ 1096 WH1_Status 0;
BA_ "GenSigAutoGenSnd" SG_ 1096 WH1_Status 1;
BA_ "GenSigAutoGenDsp" SG_ 1096 WH1_Status 1;
BA_ "GenSigSwitchedByIgnition" SG_ 1096 WH1_Testergebnis 0;
BA_ "GenSigSendType" SG_ 1096 WH1_Testergebnis 0;
BA_ "GenSigAutoGenSnd" SG_ 1096 WH1_Testergebnis 1;
BA_ "GenSigAutoGenDsp" SG_ 1096 WH1_Testergebnis 1;
BA_ "GenSigSwitchedByIgnition" SG_ 1096 WH1_Zaehler 0;
BA_ "GenSigFuncType" SG_ 1096 WH1_Zaehler 1;
BA_ "GenSigSendType" SG_ 1096 WH1_Zaehler 0;
BA_ "GenSigAutoGenSnd" SG_ 1096 WH1_Zaehler 1;
BA_ "GenSigAutoGenDsp" SG_ 1096 WH1_Zaehler 1;
BA_ "GenSigSwitchedByIgnition" SG_ 1096 WH1_Test_Flag 0;
BA_ "GenSigSendType" SG_ 1096 WH1_Test_Flag 0;
BA_ "GenSigAutoGenSnd" SG_ 1096 WH1_Test_Flag 1;
BA_ "GenSigAutoGenDsp" SG_ 1096 WH1_Test_Flag 1;
BA_ "GenSigSwitchedByIgnition" SG_ 1096 WH1_Taster_betaetigt 0;
BA_ "GenSigSendType" SG_ 1096 WH1_Taster_betaetigt 0;
BA_ "GenSigSwitchedByIgnition" SG_ 1096 WH1_Position_inv 0;
BA_ "GenSigStartValue" SG_ 1096 WH1_Position_inv 15;
BA_ "GenSigSendType" SG_ 1096 WH1_Position_inv 0;
BA_ "GenSigAutoGenSnd" SG_ 1096 WH1_Position_inv 1;
BA_ "GenSigAutoGenDsp" SG_ 1096 WH1_Position_inv 1;
BA_ "GenSigFuncType" SG_ 1102 WH2_Checksumme 4;
BA_ "GenSigSendType" SG_ 1102 WH2_Checksumme 0;
BA_ "GenSigAutoGenSnd" SG_ 1102 WH2_Checksumme 1;
BA_ "GenSigAutoGenDsp" SG_ 1102 WH2_Checksumme 1;
BA_ "GenSigFuncType" SG_ 1102 WH2_Zaehler 1;
BA_ "GenSigSendType" SG_ 1102 WH2_Zaehler 0;
BA_ "GenSigAutoGenSnd" SG_ 1102 WH2_Zaehler 1;
BA_ "GenSigAutoGenDsp" SG_ 1102 WH2_Zaehler 1;
BA_ "GenSigStartValue" SG_ 1102 WH2_Init 1;
BA_ "GenSigSendType" SG_ 1102 WH2_Init 0;
BA_ "GenSigAutoGenSnd" SG_ 1102 WH2_Init 1;
BA_ "GenSigAutoGenDsp" SG_ 1102 WH2_Init 1;
BA_ "GenSigSendType" SG_ 1102 WH2_Test_Flag 0;
BA_ "GenSigAutoGenSnd" SG_ 1102 WH2_Test_Flag 1;
BA_ "GenSigAutoGenDsp" SG_ 1102 WH2_Test_Flag 1;
BA_ "GenSigSendType" SG_ 1102 WH2_Sport 0;
BA_ "GenSigAutoGenSnd" SG_ 1102 WH2_Sport 1;
BA_ "GenSigAutoGenDsp" SG_ 1102 WH2_Sport 1;
BA_ "GenSigSendType" SG_ 1102 WH2_Winter 0;
BA_ "GenSigAutoGenSnd" SG_ 1102 WH2_Winter 1;
BA_ "GenSigAutoGenDsp" SG_ 1102 WH2_Winter 1;
BA_ "GenSigSendType" SG_ 1102 WH2_Position 0;
BA_ "GenSigAutoGenSnd" SG_ 1102 WH2_Position 1;
BA_ "GenSigAutoGenDsp" SG_ 1102 WH2_Position 1;
BA_ "GenSigSendType" SG_ 1102 WH2_Ruhestromfehler 0;
BA_ "GenSigAutoGenSnd" SG_ 1102 WH2_Ruhestromfehler 1;
BA_ "GenSigAutoGenDsp" SG_ 1102 WH2_Ruhestromfehler 1;
BA_ "GenSigSendType" SG_ 1102 WH2_Sensorarray_Einfachfehler 0;
BA_ "GenSigAutoGenSnd" SG_ 1102 WH2_Sensorarray_Einfachfehler 1;
BA_ "GenSigAutoGenDsp" SG_ 1102 WH2_Sensorarray_Einfachfehler 1;
BA_ "GenSigSendType" SG_ 1102 WH2_Sensorarray_Mehrfachfehler 0;
BA_ "GenSigAutoGenSnd" SG_ 1102 WH2_Sensorarray_Mehrfachfehler 1;
BA_ "GenSigAutoGenDsp" SG_ 1102 WH2_Sensorarray_Mehrfachfehler 1;
BA_ "GenSigSendType" SG_ 1102 WH2_Fehler_Sporttaster 0;
BA_ "GenSigAutoGenSnd" SG_ 1102 WH2_Fehler_Sporttaster 1;
BA_ "GenSigAutoGenDsp" SG_ 1102 WH2_Fehler_Sporttaster 1;
BA_ "GenSigSendType" SG_ 1102 WH2_Fehler_Fahrstufenanzeige 0;
BA_ "GenSigAutoGenSnd" SG_ 1102 WH2_Fehler_Fahrstufenanzeige 1;
BA_ "GenSigAutoGenDsp" SG_ 1102 WH2_Fehler_Fahrstufenanzeige 1;
BA_ "GenSigSendType" SG_ 1102 WH2_Fehler_Spannungsversorgung 0;
BA_ "GenSigAutoGenSnd" SG_ 1102 WH2_Fehler_Spannungsversorgung 1;
BA_ "GenSigAutoGenDsp" SG_ 1102 WH2_Fehler_Spannungsversorgung 1;
BA_ "GenSigSendType" SG_ 1102 WH2_Timeout_Kombi_2 0;
BA_ "GenSigAutoGenSnd" SG_ 1102 WH2_Timeout_Kombi_2 1;
BA_ "GenSigAutoGenDsp" SG_ 1102 WH2_Timeout_Kombi_2 1;
BA_ "GenSigSendType" SG_ 1102 WH2_Timeout_Getriebe_5 0;
BA_ "GenSigAutoGenSnd" SG_ 1102 WH2_Timeout_Getriebe_5 1;
BA_ "GenSigAutoGenDsp" SG_ 1102 WH2_Timeout_Getriebe_5 1;
BA_ "GenSigSendType" SG_ 1102 WH2_Timeout_Gate_Komf_1 0;
BA_ "GenSigAutoGenSnd" SG_ 1102 WH2_Timeout_Gate_Komf_1 1;
BA_ "GenSigAutoGenDsp" SG_ 1102 WH2_Timeout_Gate_Komf_1 1;
BA_ "GenSigSendType" SG_ 1102 WH2_Testergebnis 0;
BA_ "GenSigAutoGenSnd" SG_ 1102 WH2_Testergebnis 1;
BA_ "GenSigAutoGenDsp" SG_ 1102 WH2_Testergebnis 1;
BA_ "GenSigSwitchedByIgnition" SG_ 1394 ZA1_S_Kontakt 0;
BA_ "GenSigSendType" SG_ 1394 ZA1_S_Kontakt 3;
BA_ "GenSigAutoGenSnd" SG_ 1394 ZA1_S_Kontakt 1;
BA_ "GenSigAutoGenDsp" SG_ 1394 ZA1_S_Kontakt 1;
BA_ "GenSigSwitchedByIgnition" SG_ 1394 ZA1_Klemme_15 0;
BA_ "GenSigFuncType" SG_ 1394 ZA1_Klemme_15 6;
BA_ "GenSigSendType" SG_ 1394 ZA1_Klemme_15 3;
BA_ "GenSigAutoGenSnd" SG_ 1394 ZA1_Klemme_15 1;
BA_ "GenSigAutoGenDsp" SG_ 1394 ZA1_Klemme_15 1;
BA_ "GenSigSwitchedByIgnition" SG_ 1394 ZA1_Klemme_X 0;
BA_ "GenSigSendType" SG_ 1394 ZA1_Klemme_X 3;
BA_ "GenSigAutoGenSnd" SG_ 1394 ZA1_Klemme_X 1;
BA_ "GenSigAutoGenDsp" SG_ 1394 ZA1_Klemme_X 1;
BA_ "GenSigSwitchedByIgnition" SG_ 1394 ZA1_Klemme_50 0;
BA_ "GenSigSendType" SG_ 1394 ZA1_Klemme_50 3;
BA_ "GenSigAutoGenSnd" SG_ 1394 ZA1_Klemme_50 1;
BA_ "GenSigAutoGenDsp" SG_ 1394 ZA1_Klemme_50 1;
BA_ "GenSigSwitchedByIgnition" SG_ 1394 ZA1_Klemme_P 0;
BA_ "GenSigSendType" SG_ 1394 ZA1_Klemme_P 3;
BA_ "GenSigAutoGenSnd" SG_ 1394 ZA1_Klemme_P 1;
BA_ "GenSigAutoGenDsp" SG_ 1394 ZA1_Klemme_P 1;
BA_ "GenSigSwitchedByIgnition" SG_ 919 ZK5_Checksumme 0;
BA_ "GenSigFuncType" SG_ 919 ZK5_Checksumme 4;
BA_ "GenSigSendType" SG_ 919 ZK5_Checksumme 0;
BA_ "GenSigAutoGenSnd" SG_ 919 ZK5_Checksumme 1;
BA_ "GenSigAutoGenDsp" SG_ 919 ZK5_Checksumme 1;
BA_ "GenSigSwitchedByIgnition" SG_ 919 ZK5_Zaehler 0;
BA_ "GenSigFuncType" SG_ 919 ZK5_Zaehler 1;
BA_ "GenSigSendType" SG_ 919 ZK5_Zaehler 0;
BA_ "GenSigAutoGenSnd" SG_ 919 ZK5_Zaehler 1;
BA_ "GenSigAutoGenDsp" SG_ 919 ZK5_Zaehler 1;
BA_ "GenSigSwitchedByIgnition" SG_ 919 ZK5_Endlage_ausgefahren 0;
BA_ "GenSigSendType" SG_ 919 ZK5_Endlage_ausgefahren 0;
BA_ "GenSigAutoGenSnd" SG_ 919 ZK5_Endlage_ausgefahren 1;
BA_ "GenSigAutoGenDsp" SG_ 919 ZK5_Endlage_ausgefahren 1;
BA_ "GenSigSwitchedByIgnition" SG_ 919 ZK5_Endlage_eingefahren 0;
BA_ "GenSigSendType" SG_ 919 ZK5_Endlage_eingefahren 0;
BA_ "GenSigAutoGenSnd" SG_ 919 ZK5_Endlage_eingefahren 1;
BA_ "GenSigAutoGenDsp" SG_ 919 ZK5_Endlage_eingefahren 1;
BA_ "GenSigSwitchedByIgnition" SG_ 919 ZK5_Status_Spoiler 0;
BA_ "GenSigSendType" SG_ 919 ZK5_Status_Spoiler 0;
BA_ "GenSigAutoGenSnd" SG_ 919 ZK5_Status_Spoiler 1;
BA_ "GenSigAutoGenDsp" SG_ 919 ZK5_Status_Spoiler 1;
BA_ "GenSigSwitchedByIgnition" SG_ 919 ZV_SafeFunktion_aktiv 0;
BA_ "GenSigSendType" SG_ 919 ZV_SafeFunktion_aktiv 0;
BA_ "GenSigAutoGenSnd" SG_ 919 ZV_SafeFunktion_aktiv 1;
BA_ "GenSigAutoGenDsp" SG_ 919 ZV_SafeFunktion_aktiv 1;
BA_ "GenSigSwitchedByIgnition" SG_ 919 ZK5_VD_Endlage_geschl 0;
BA_ "GenSigSendType" SG_ 919 ZK5_VD_Endlage_geschl 0;
BA_ "GenSigAutoGenSnd" SG_ 919 ZK5_VD_Endlage_geschl 1;
BA_ "GenSigAutoGenDsp" SG_ 919 ZK5_VD_Endlage_geschl 1;
BA_ "GenSigSwitchedByIgnition" SG_ 919 ZK5_VD_Endlage_abgelegt 0;
BA_ "GenSigSendType" SG_ 919 ZK5_VD_Endlage_abgelegt 0;
BA_ "GenSigAutoGenSnd" SG_ 919 ZK5_VD_Endlage_abgelegt 1;
BA_ "GenSigAutoGenDsp" SG_ 919 ZK5_VD_Endlage_abgelegt 1;
BA_ "GenSigSwitchedByIgnition" SG_ 919 ZK5_VD_Verbau 0;
BA_ "GenSigSendType" SG_ 919 ZK5_VD_Verbau 0;
BA_ "GenSigAutoGenSnd" SG_ 919 ZK5_VD_Verbau 1;
BA_ "GenSigAutoGenDsp" SG_ 919 ZK5_VD_Verbau 1;
BA_ "GenSigSwitchedByIgnition" SG_ 1827 NMH_ABS_Start_1 0;
BA_ "GenSigSendType" SG_ 1827 NMH_ABS_Start_1 0;
BA_ "GenSigAutoGenSnd" SG_ 1827 NMH_ABS_Start_1 1;
BA_ "GenSigAutoGenDsp" SG_ 1827 NMH_ABS_Start_1 1;
BA_ "GenSigSwitchedByIgnition" SG_ 1827 NMH_ABS_Start_2 0;
BA_ "GenSigSendType" SG_ 1827 NMH_ABS_Start_2 0;
BA_ "GenSigAutoGenSnd" SG_ 1827 NMH_ABS_Start_2 1;
BA_ "GenSigAutoGenDsp" SG_ 1827 NMH_ABS_Start_2 1;
BA_ "GenSigSwitchedByIgnition" SG_ 1827 NMH_ABS_Normal_Mode_1 0;
BA_ "GenSigSendType" SG_ 1827 NMH_ABS_Normal_Mode_1 0;
BA_ "GenSigAutoGenSnd" SG_ 1827 NMH_ABS_Normal_Mode_1 1;
BA_ "GenSigAutoGenDsp" SG_ 1827 NMH_ABS_Normal_Mode_1 1;
BA_ "GenSigSwitchedByIgnition" SG_ 1827 NMH_ABS_Normal_Mode_2 0;
BA_ "GenSigSendType" SG_ 1827 NMH_ABS_Normal_Mode_2 0;
BA_ "GenSigAutoGenSnd" SG_ 1827 NMH_ABS_Normal_Mode_2 1;
BA_ "GenSigAutoGenDsp" SG_ 1827 NMH_ABS_Normal_Mode_2 1;
BA_ "GenSigSwitchedByIgnition" SG_ 1827 NMH_ABS_Car_WakeUp 0;
BA_ "GenSigSendType" SG_ 1827 NMH_ABS_Car_WakeUp 0;
BA_ "GenSigAutoGenSnd" SG_ 1827 NMH_ABS_Car_WakeUp 1;
BA_ "GenSigAutoGenDsp" SG_ 1827 NMH_ABS_Car_WakeUp 1;
BA_ "GenSigSwitchedByIgnition" SG_ 1827 NMH_ABS_Per_WakeUp 0;
BA_ "GenSigSendType" SG_ 1827 NMH_ABS_Per_WakeUp 0;
BA_ "GenSigAutoGenSnd" SG_ 1827 NMH_ABS_Per_WakeUp 1;
BA_ "GenSigAutoGenDsp" SG_ 1827 NMH_ABS_Per_WakeUp 1;
BA_ "GenSigSwitchedByIgnition" SG_ 1827 NMH_ABS_Fkt_WakeUp 0;
BA_ "GenSigSendType" SG_ 1827 NMH_ABS_Fkt_WakeUp 0;
BA_ "GenSigAutoGenSnd" SG_ 1827 NMH_ABS_Fkt_WakeUp 1;
BA_ "GenSigAutoGenDsp" SG_ 1827 NMH_ABS_Fkt_WakeUp 1;
BA_ "GenSigSwitchedByIgnition" SG_ 1827 NMH_ABS_NM_aktiv_Klemme_15 0;
BA_ "GenSigSendType" SG_ 1827 NMH_ABS_NM_aktiv_Klemme_15 0;
BA_ "GenSigAutoGenSnd" SG_ 1827 NMH_ABS_NM_aktiv_Klemme_15 1;
BA_ "GenSigAutoGenDsp" SG_ 1827 NMH_ABS_NM_aktiv_Klemme_15 1;
BA_ "GenSigSwitchedByIgnition" SG_ 1827 NMH_ABS_NM_aktiv_Diagnose 0;
BA_ "GenSigSendType" SG_ 1827 NMH_ABS_NM_aktiv_Diagnose 0;
BA_ "GenSigAutoGenSnd" SG_ 1827 NMH_ABS_NM_aktiv_Diagnose 1;
BA_ "GenSigAutoGenDsp" SG_ 1827 NMH_ABS_NM_aktiv_Diagnose 1;
BA_ "GenSigSwitchedByIgnition" SG_ 1827 NMH_ABS_NM_aktiv_Start 0;
BA_ "GenSigSendType" SG_ 1827 NMH_ABS_NM_aktiv_Start 0;
BA_ "GenSigAutoGenSnd" SG_ 1827 NMH_ABS_NM_aktiv_Start 1;
BA_ "GenSigAutoGenDsp" SG_ 1827 NMH_ABS_NM_aktiv_Start 1;
BA_ "GenSigSwitchedByIgnition" SG_ 1827 NMH_ABS_NL_aktiv_4 0;
BA_ "GenSigSendType" SG_ 1827 NMH_ABS_NL_aktiv_4 0;
BA_ "GenSigAutoGenSnd" SG_ 1827 NMH_ABS_NL_aktiv_4 1;
BA_ "GenSigAutoGenDsp" SG_ 1827 NMH_ABS_NL_aktiv_4 1;
BA_ "GenSigSwitchedByIgnition" SG_ 1827 NMH_ABS_NL_aktiv_5 0;
BA_ "GenSigSendType" SG_ 1827 NMH_ABS_NL_aktiv_5 0;
BA_ "GenSigAutoGenSnd" SG_ 1827 NMH_ABS_NL_aktiv_5 1;
BA_ "GenSigAutoGenDsp" SG_ 1827 NMH_ABS_NL_aktiv_5 1;
BA_ "GenSigSwitchedByIgnition" SG_ 1827 NMH_ABS_NL_aktiv_6 0;
BA_ "GenSigSendType" SG_ 1827 NMH_ABS_NL_aktiv_6 0;
BA_ "GenSigAutoGenSnd" SG_ 1827 NMH_ABS_NL_aktiv_6 1;
BA_ "GenSigAutoGenDsp" SG_ 1827 NMH_ABS_NL_aktiv_6 1;
BA_ "GenSigSwitchedByIgnition" SG_ 1827 NMH_ABS_NL_aktiv_7 0;
BA_ "GenSigSendType" SG_ 1827 NMH_ABS_NL_aktiv_7 0;
BA_ "GenSigAutoGenSnd" SG_ 1827 NMH_ABS_NL_aktiv_7 1;
BA_ "GenSigAutoGenDsp" SG_ 1827 NMH_ABS_NL_aktiv_7 1;
BA_ "GenSigSwitchedByIgnition" SG_ 1827 NMH_ABS_NL_aktiv_8 0;
BA_ "GenSigSendType" SG_ 1827 NMH_ABS_NL_aktiv_8 0;
BA_ "GenSigAutoGenSnd" SG_ 1827 NMH_ABS_NL_aktiv_8 1;
BA_ "GenSigAutoGenDsp" SG_ 1827 NMH_ABS_NL_aktiv_8 1;
BA_ "GenSigSwitchedByIgnition" SG_ 1827 NMH_ABS_NL_0 0;
BA_ "GenSigSendType" SG_ 1827 NMH_ABS_NL_0 0;
BA_ "GenSigAutoGenSnd" SG_ 1827 NMH_ABS_NL_0 1;
BA_ "GenSigAutoGenDsp" SG_ 1827 NMH_ABS_NL_0 1;
BA_ "GenSigSwitchedByIgnition" SG_ 1827 NMH_ABS_NL_1 0;
BA_ "GenSigSendType" SG_ 1827 NMH_ABS_NL_1 0;
BA_ "GenSigAutoGenSnd" SG_ 1827 NMH_ABS_NL_1 1;
BA_ "GenSigAutoGenDsp" SG_ 1827 NMH_ABS_NL_1 1;
BA_ "GenSigSwitchedByIgnition" SG_ 1827 NMH_ABS_NL_2 0;
BA_ "GenSigSendType" SG_ 1827 NMH_ABS_NL_2 0;
BA_ "GenSigAutoGenSnd" SG_ 1827 NMH_ABS_NL_2 1;
BA_ "GenSigAutoGenDsp" SG_ 1827 NMH_ABS_NL_2 1;
BA_ "GenSigSwitchedByIgnition" SG_ 1827 NMH_ABS_NL_3 0;
BA_ "GenSigSendType" SG_ 1827 NMH_ABS_NL_3 0;
BA_ "GenSigAutoGenSnd" SG_ 1827 NMH_ABS_NL_3 1;
BA_ "GenSigAutoGenDsp" SG_ 1827 NMH_ABS_NL_3 1;
BA_ "GenSigSwitchedByIgnition" SG_ 1827 NMH_ABS_NL_4 0;
BA_ "GenSigSendType" SG_ 1827 NMH_ABS_NL_4 0;
BA_ "GenSigAutoGenSnd" SG_ 1827 NMH_ABS_NL_4 1;
BA_ "GenSigAutoGenDsp" SG_ 1827 NMH_ABS_NL_4 1;
BA_ "GenSigSwitchedByIgnition" SG_ 1827 NMH_ABS_NL_5 0;
BA_ "GenSigSendType" SG_ 1827 NMH_ABS_NL_5 0;
BA_ "GenSigAutoGenSnd" SG_ 1827 NMH_ABS_NL_5 1;
BA_ "GenSigAutoGenDsp" SG_ 1827 NMH_ABS_NL_5 1;
BA_ "GenSigSwitchedByIgnition" SG_ 1827 NMH_ABS_NL_6 0;
BA_ "GenSigSendType" SG_ 1827 NMH_ABS_NL_6 0;
BA_ "GenSigAutoGenSnd" SG_ 1827 NMH_ABS_NL_6 1;
BA_ "GenSigAutoGenDsp" SG_ 1827 NMH_ABS_NL_6 1;
BA_ "GenSigSwitchedByIgnition" SG_ 1827 NMH_ABS_NL_7 0;
BA_ "GenSigSendType" SG_ 1827 NMH_ABS_NL_7 0;
BA_ "GenSigAutoGenSnd" SG_ 1827 NMH_ABS_NL_7 1;
BA_ "GenSigAutoGenDsp" SG_ 1827 NMH_ABS_NL_7 1;
BA_ "GenSigSwitchedByIgnition" SG_ 1827 NMH_ABS_TimeOut_Fehler 0;
BA_ "GenSigSendType" SG_ 1827 NMH_ABS_TimeOut_Fehler 0;
BA_ "GenSigAutoGenSnd" SG_ 1827 NMH_ABS_TimeOut_Fehler 1;
BA_ "GenSigAutoGenDsp" SG_ 1827 NMH_ABS_TimeOut_Fehler 1;
BA_ "GenSigSwitchedByIgnition" SG_ 1827 NMH_ABS_CAN_Diag_deaktiv 0;
BA_ "GenSigSendType" SG_ 1827 NMH_ABS_CAN_Diag_deaktiv 0;
BA_ "GenSigAutoGenSnd" SG_ 1827 NMH_ABS_CAN_Diag_deaktiv 1;
BA_ "GenSigAutoGenDsp" SG_ 1827 NMH_ABS_CAN_Diag_deaktiv 1;
BA_ "GenSigSwitchedByIgnition" SG_ 1827 NMH_ABS_KompSchutz 0;
BA_ "GenSigSendType" SG_ 1827 NMH_ABS_KompSchutz 0;
BA_ "GenSigAutoGenSnd" SG_ 1827 NMH_ABS_KompSchutz 1;
BA_ "GenSigAutoGenDsp" SG_ 1827 NMH_ABS_KompSchutz 1;
BA_ "GenSigSwitchedByIgnition" SG_ 1827 NMH_ABS_Mute_Mode 0;
BA_ "GenSigSendType" SG_ 1827 NMH_ABS_Mute_Mode 0;
BA_ "GenSigAutoGenSnd" SG_ 1827 NMH_ABS_Mute_Mode 1;
BA_ "GenSigAutoGenDsp" SG_ 1827 NMH_ABS_Mute_Mode 1;
BA_ "GenSigSwitchedByIgnition" SG_ 1827 NMH_ABS_Transport_Mode 0;
BA_ "GenSigSendType" SG_ 1827 NMH_ABS_Transport_Mode 0;
BA_ "GenSigAutoGenSnd" SG_ 1827 NMH_ABS_Transport_Mode 1;
BA_ "GenSigAutoGenDsp" SG_ 1827 NMH_ABS_Transport_Mode 1;
BA_ "GenSigSwitchedByIgnition" SG_ 1827 NMH_ABS_Abschaltstufe_aktiv 0;
BA_ "GenSigSendType" SG_ 1827 NMH_ABS_Abschaltstufe_aktiv 0;
BA_ "GenSigAutoGenSnd" SG_ 1827 NMH_ABS_Abschaltstufe_aktiv 1;
BA_ "GenSigAutoGenDsp" SG_ 1827 NMH_ABS_Abschaltstufe_aktiv 1;
BA_ "GenSigSwitchedByIgnition" SG_ 1827 NMH_ABS_Eindraht_Fehler 0;
BA_ "GenSigSendType" SG_ 1827 NMH_ABS_Eindraht_Fehler 0;
BA_ "GenSigAutoGenSnd" SG_ 1827 NMH_ABS_Eindraht_Fehler 1;
BA_ "GenSigAutoGenDsp" SG_ 1827 NMH_ABS_Eindraht_Fehler 1;
BA_ "GenSigSwitchedByIgnition" SG_ 1838 NMH_BMS_Start_1 0;
BA_ "GenSigSendType" SG_ 1838 NMH_BMS_Start_1 0;
BA_ "GenSigAutoGenSnd" SG_ 1838 NMH_BMS_Start_1 1;
BA_ "GenSigAutoGenDsp" SG_ 1838 NMH_BMS_Start_1 1;
BA_ "GenSigSwitchedByIgnition" SG_ 1838 NMH_BMS_Start_2 0;
BA_ "GenSigSendType" SG_ 1838 NMH_BMS_Start_2 0;
BA_ "GenSigAutoGenSnd" SG_ 1838 NMH_BMS_Start_2 1;
BA_ "GenSigAutoGenDsp" SG_ 1838 NMH_BMS_Start_2 1;
BA_ "GenSigSwitchedByIgnition" SG_ 1838 NMH_BMS_Normal_Mode_1 0;
BA_ "GenSigSendType" SG_ 1838 NMH_BMS_Normal_Mode_1 0;
BA_ "GenSigAutoGenSnd" SG_ 1838 NMH_BMS_Normal_Mode_1 1;
BA_ "GenSigAutoGenDsp" SG_ 1838 NMH_BMS_Normal_Mode_1 1;
BA_ "GenSigSwitchedByIgnition" SG_ 1838 NMH_BMS_Normal_Mode_2 0;
BA_ "GenSigSendType" SG_ 1838 NMH_BMS_Normal_Mode_2 0;
BA_ "GenSigAutoGenSnd" SG_ 1838 NMH_BMS_Normal_Mode_2 1;
BA_ "GenSigAutoGenDsp" SG_ 1838 NMH_BMS_Normal_Mode_2 1;
BA_ "GenSigSwitchedByIgnition" SG_ 1838 NMH_BMS_Car_WakeUp 0;
BA_ "GenSigSendType" SG_ 1838 NMH_BMS_Car_WakeUp 0;
BA_ "GenSigAutoGenSnd" SG_ 1838 NMH_BMS_Car_WakeUp 1;
BA_ "GenSigAutoGenDsp" SG_ 1838 NMH_BMS_Car_WakeUp 1;
BA_ "GenSigSwitchedByIgnition" SG_ 1838 NMH_BMS_Per_WakeUp 0;
BA_ "GenSigSendType" SG_ 1838 NMH_BMS_Per_WakeUp 0;
BA_ "GenSigAutoGenSnd" SG_ 1838 NMH_BMS_Per_WakeUp 1;
BA_ "GenSigAutoGenDsp" SG_ 1838 NMH_BMS_Per_WakeUp 1;
BA_ "GenSigSwitchedByIgnition" SG_ 1838 NMH_BMS_Fkt_WakeUp 0;
BA_ "GenSigSendType" SG_ 1838 NMH_BMS_Fkt_WakeUp 0;
BA_ "GenSigAutoGenSnd" SG_ 1838 NMH_BMS_Fkt_WakeUp 1;
BA_ "GenSigAutoGenDsp" SG_ 1838 NMH_BMS_Fkt_WakeUp 1;
BA_ "GenSigSwitchedByIgnition" SG_ 1838 NMH_BMS_NM_aktiv_Klemme_15 0;
BA_ "GenSigSendType" SG_ 1838 NMH_BMS_NM_aktiv_Klemme_15 0;
BA_ "GenSigAutoGenSnd" SG_ 1838 NMH_BMS_NM_aktiv_Klemme_15 1;
BA_ "GenSigAutoGenDsp" SG_ 1838 NMH_BMS_NM_aktiv_Klemme_15 1;
BA_ "GenSigSwitchedByIgnition" SG_ 1838 NMH_BMS_NM_aktiv_Diagnose 0;
BA_ "GenSigSendType" SG_ 1838 NMH_BMS_NM_aktiv_Diagnose 0;
BA_ "GenSigAutoGenSnd" SG_ 1838 NMH_BMS_NM_aktiv_Diagnose 1;
BA_ "GenSigAutoGenDsp" SG_ 1838 NMH_BMS_NM_aktiv_Diagnose 1;
BA_ "GenSigSwitchedByIgnition" SG_ 1838 NMH_BMS_NM_aktiv_Start 0;
BA_ "GenSigSendType" SG_ 1838 NMH_BMS_NM_aktiv_Start 0;
BA_ "GenSigAutoGenSnd" SG_ 1838 NMH_BMS_NM_aktiv_Start 1;
BA_ "GenSigAutoGenDsp" SG_ 1838 NMH_BMS_NM_aktiv_Start 1;
BA_ "GenSigSwitchedByIgnition" SG_ 1838 NMH_BMS_NL_aktiv_4 0;
BA_ "GenSigSendType" SG_ 1838 NMH_BMS_NL_aktiv_4 0;
BA_ "GenSigAutoGenSnd" SG_ 1838 NMH_BMS_NL_aktiv_4 1;
BA_ "GenSigAutoGenDsp" SG_ 1838 NMH_BMS_NL_aktiv_4 1;
BA_ "GenSigSwitchedByIgnition" SG_ 1838 NMH_BMS_NL_aktiv_5 0;
BA_ "GenSigSendType" SG_ 1838 NMH_BMS_NL_aktiv_5 0;
BA_ "GenSigAutoGenSnd" SG_ 1838 NMH_BMS_NL_aktiv_5 1;
BA_ "GenSigAutoGenDsp" SG_ 1838 NMH_BMS_NL_aktiv_5 1;
BA_ "GenSigSwitchedByIgnition" SG_ 1838 NMH_BMS_NL_aktiv_6 0;
BA_ "GenSigSendType" SG_ 1838 NMH_BMS_NL_aktiv_6 0;
BA_ "GenSigAutoGenSnd" SG_ 1838 NMH_BMS_NL_aktiv_6 1;
BA_ "GenSigAutoGenDsp" SG_ 1838 NMH_BMS_NL_aktiv_6 1;
BA_ "GenSigSwitchedByIgnition" SG_ 1838 NMH_BMS_NL_aktiv_7 0;
BA_ "GenSigSendType" SG_ 1838 NMH_BMS_NL_aktiv_7 0;
BA_ "GenSigAutoGenSnd" SG_ 1838 NMH_BMS_NL_aktiv_7 1;
BA_ "GenSigAutoGenDsp" SG_ 1838 NMH_BMS_NL_aktiv_7 1;
BA_ "GenSigSwitchedByIgnition" SG_ 1838 NMH_BMS_NL_aktiv_8 0;
BA_ "GenSigSendType" SG_ 1838 NMH_BMS_NL_aktiv_8 0;
BA_ "GenSigAutoGenSnd" SG_ 1838 NMH_BMS_NL_aktiv_8 1;
BA_ "GenSigAutoGenDsp" SG_ 1838 NMH_BMS_NL_aktiv_8 1;
BA_ "GenSigSwitchedByIgnition" SG_ 1838 NMH_BMS_NL_0 0;
BA_ "GenSigSendType" SG_ 1838 NMH_BMS_NL_0 0;
BA_ "GenSigAutoGenSnd" SG_ 1838 NMH_BMS_NL_0 1;
BA_ "GenSigAutoGenDsp" SG_ 1838 NMH_BMS_NL_0 1;
BA_ "GenSigSwitchedByIgnition" SG_ 1838 NMH_BMS_NL_1 0;
BA_ "GenSigSendType" SG_ 1838 NMH_BMS_NL_1 0;
BA_ "GenSigAutoGenSnd" SG_ 1838 NMH_BMS_NL_1 1;
BA_ "GenSigAutoGenDsp" SG_ 1838 NMH_BMS_NL_1 1;
BA_ "GenSigSwitchedByIgnition" SG_ 1838 NMH_BMS_NL_2 0;
BA_ "GenSigSendType" SG_ 1838 NMH_BMS_NL_2 0;
BA_ "GenSigAutoGenSnd" SG_ 1838 NMH_BMS_NL_2 1;
BA_ "GenSigAutoGenDsp" SG_ 1838 NMH_BMS_NL_2 1;
BA_ "GenSigSwitchedByIgnition" SG_ 1838 NMH_BMS_NL_3 0;
BA_ "GenSigSendType" SG_ 1838 NMH_BMS_NL_3 0;
BA_ "GenSigAutoGenSnd" SG_ 1838 NMH_BMS_NL_3 1;
BA_ "GenSigAutoGenDsp" SG_ 1838 NMH_BMS_NL_3 1;
BA_ "GenSigSwitchedByIgnition" SG_ 1838 NMH_BMS_NL_4 0;
BA_ "GenSigSendType" SG_ 1838 NMH_BMS_NL_4 0;
BA_ "GenSigAutoGenSnd" SG_ 1838 NMH_BMS_NL_4 1;
BA_ "GenSigAutoGenDsp" SG_ 1838 NMH_BMS_NL_4 1;
BA_ "GenSigSwitchedByIgnition" SG_ 1838 NMH_BMS_NL_5 0;
BA_ "GenSigSendType" SG_ 1838 NMH_BMS_NL_5 0;
BA_ "GenSigAutoGenSnd" SG_ 1838 NMH_BMS_NL_5 1;
BA_ "GenSigAutoGenDsp" SG_ 1838 NMH_BMS_NL_5 1;
BA_ "GenSigSwitchedByIgnition" SG_ 1838 NMH_BMS_NL_6 0;
BA_ "GenSigSendType" SG_ 1838 NMH_BMS_NL_6 0;
BA_ "GenSigAutoGenSnd" SG_ 1838 NMH_BMS_NL_6 1;
BA_ "GenSigAutoGenDsp" SG_ 1838 NMH_BMS_NL_6 1;
BA_ "GenSigSwitchedByIgnition" SG_ 1838 NMH_BMS_NL_7 0;
BA_ "GenSigSendType" SG_ 1838 NMH_BMS_NL_7 0;
BA_ "GenSigAutoGenSnd" SG_ 1838 NMH_BMS_NL_7 1;
BA_ "GenSigAutoGenDsp" SG_ 1838 NMH_BMS_NL_7 1;
BA_ "GenSigSwitchedByIgnition" SG_ 1838 NMH_BMS_TimeOut_Fehler 0;
BA_ "GenSigSendType" SG_ 1838 NMH_BMS_TimeOut_Fehler 0;
BA_ "GenSigAutoGenSnd" SG_ 1838 NMH_BMS_TimeOut_Fehler 1;
BA_ "GenSigAutoGenDsp" SG_ 1838 NMH_BMS_TimeOut_Fehler 1;
BA_ "GenSigSwitchedByIgnition" SG_ 1838 NMH_BMS_CAN_Diag_deaktiv 0;
BA_ "GenSigSendType" SG_ 1838 NMH_BMS_CAN_Diag_deaktiv 0;
BA_ "GenSigAutoGenSnd" SG_ 1838 NMH_BMS_CAN_Diag_deaktiv 1;
BA_ "GenSigAutoGenDsp" SG_ 1838 NMH_BMS_CAN_Diag_deaktiv 1;
BA_ "GenSigSwitchedByIgnition" SG_ 1838 NMH_BMS_KompSchutz 0;
BA_ "GenSigSendType" SG_ 1838 NMH_BMS_KompSchutz 0;
BA_ "GenSigAutoGenSnd" SG_ 1838 NMH_BMS_KompSchutz 1;
BA_ "GenSigAutoGenDsp" SG_ 1838 NMH_BMS_KompSchutz 1;
BA_ "GenSigSwitchedByIgnition" SG_ 1838 NMH_BMS_Mute_Mode 0;
BA_ "GenSigSendType" SG_ 1838 NMH_BMS_Mute_Mode 0;
BA_ "GenSigAutoGenSnd" SG_ 1838 NMH_BMS_Mute_Mode 1;
BA_ "GenSigAutoGenDsp" SG_ 1838 NMH_BMS_Mute_Mode 1;
BA_ "GenSigSwitchedByIgnition" SG_ 1838 NMH_BMS_Transport_Mode 0;
BA_ "GenSigSendType" SG_ 1838 NMH_BMS_Transport_Mode 0;
BA_ "GenSigAutoGenSnd" SG_ 1838 NMH_BMS_Transport_Mode 1;
BA_ "GenSigAutoGenDsp" SG_ 1838 NMH_BMS_Transport_Mode 1;
BA_ "GenSigSwitchedByIgnition" SG_ 1838 NMH_BMS_Abschaltstufe_aktiv 0;
BA_ "GenSigSendType" SG_ 1838 NMH_BMS_Abschaltstufe_aktiv 0;
BA_ "GenSigAutoGenSnd" SG_ 1838 NMH_BMS_Abschaltstufe_aktiv 1;
BA_ "GenSigAutoGenDsp" SG_ 1838 NMH_BMS_Abschaltstufe_aktiv 1;
BA_ "GenSigSwitchedByIgnition" SG_ 1838 NMH_BMS_Eindraht_Fehler 0;
BA_ "GenSigSendType" SG_ 1838 NMH_BMS_Eindraht_Fehler 0;
BA_ "GenSigAutoGenSnd" SG_ 1838 NMH_BMS_Eindraht_Fehler 1;
BA_ "GenSigAutoGenDsp" SG_ 1838 NMH_BMS_Eindraht_Fehler 1;
BA_ "GenSigSwitchedByIgnition" SG_ 1839 NMH_EM_Start_1 0;
BA_ "GenSigSendType" SG_ 1839 NMH_EM_Start_1 0;
BA_ "GenSigAutoGenSnd" SG_ 1839 NMH_EM_Start_1 1;
BA_ "GenSigAutoGenDsp" SG_ 1839 NMH_EM_Start_1 1;
BA_ "GenSigSwitchedByIgnition" SG_ 1839 NMH_EM_Start_2 0;
BA_ "GenSigSendType" SG_ 1839 NMH_EM_Start_2 0;
BA_ "GenSigAutoGenSnd" SG_ 1839 NMH_EM_Start_2 1;
BA_ "GenSigAutoGenDsp" SG_ 1839 NMH_EM_Start_2 1;
BA_ "GenSigSwitchedByIgnition" SG_ 1839 NMH_EM_Normal_Mode_1 0;
BA_ "GenSigSendType" SG_ 1839 NMH_EM_Normal_Mode_1 0;
BA_ "GenSigAutoGenSnd" SG_ 1839 NMH_EM_Normal_Mode_1 1;
BA_ "GenSigAutoGenDsp" SG_ 1839 NMH_EM_Normal_Mode_1 1;
BA_ "GenSigSwitchedByIgnition" SG_ 1839 NMH_EM_Normal_Mode_2 0;
BA_ "GenSigSendType" SG_ 1839 NMH_EM_Normal_Mode_2 0;
BA_ "GenSigAutoGenSnd" SG_ 1839 NMH_EM_Normal_Mode_2 1;
BA_ "GenSigAutoGenDsp" SG_ 1839 NMH_EM_Normal_Mode_2 1;
BA_ "GenSigSwitchedByIgnition" SG_ 1839 NMH_EM_Car_WakeUp 0;
BA_ "GenSigSendType" SG_ 1839 NMH_EM_Car_WakeUp 0;
BA_ "GenSigAutoGenSnd" SG_ 1839 NMH_EM_Car_WakeUp 1;
BA_ "GenSigAutoGenDsp" SG_ 1839 NMH_EM_Car_WakeUp 1;
BA_ "GenSigSwitchedByIgnition" SG_ 1839 NMH_EM_Per_WakeUp 0;
BA_ "GenSigSendType" SG_ 1839 NMH_EM_Per_WakeUp 0;
BA_ "GenSigAutoGenSnd" SG_ 1839 NMH_EM_Per_WakeUp 1;
BA_ "GenSigAutoGenDsp" SG_ 1839 NMH_EM_Per_WakeUp 1;
BA_ "GenSigSwitchedByIgnition" SG_ 1839 NMH_EM_Fkt_WakeUp 0;
BA_ "GenSigSendType" SG_ 1839 NMH_EM_Fkt_WakeUp 0;
BA_ "GenSigAutoGenSnd" SG_ 1839 NMH_EM_Fkt_WakeUp 1;
BA_ "GenSigAutoGenDsp" SG_ 1839 NMH_EM_Fkt_WakeUp 1;
BA_ "GenSigSwitchedByIgnition" SG_ 1839 NMH_EM_NM_aktiv_Klemme_15 0;
BA_ "GenSigSendType" SG_ 1839 NMH_EM_NM_aktiv_Klemme_15 0;
BA_ "GenSigAutoGenSnd" SG_ 1839 NMH_EM_NM_aktiv_Klemme_15 1;
BA_ "GenSigAutoGenDsp" SG_ 1839 NMH_EM_NM_aktiv_Klemme_15 1;
BA_ "GenSigSwitchedByIgnition" SG_ 1839 NMH_EM_NM_aktiv_Diagnose 0;
BA_ "GenSigSendType" SG_ 1839 NMH_EM_NM_aktiv_Diagnose 0;
BA_ "GenSigAutoGenSnd" SG_ 1839 NMH_EM_NM_aktiv_Diagnose 1;
BA_ "GenSigAutoGenDsp" SG_ 1839 NMH_EM_NM_aktiv_Diagnose 1;
BA_ "GenSigSwitchedByIgnition" SG_ 1839 NMH_EM_NM_aktiv_Start 0;
BA_ "GenSigSendType" SG_ 1839 NMH_EM_NM_aktiv_Start 0;
BA_ "GenSigAutoGenSnd" SG_ 1839 NMH_EM_NM_aktiv_Start 1;
BA_ "GenSigAutoGenDsp" SG_ 1839 NMH_EM_NM_aktiv_Start 1;
BA_ "GenSigSwitchedByIgnition" SG_ 1839 NMH_EM_NL_aktiv_4 0;
BA_ "GenSigSendType" SG_ 1839 NMH_EM_NL_aktiv_4 0;
BA_ "GenSigAutoGenSnd" SG_ 1839 NMH_EM_NL_aktiv_4 1;
BA_ "GenSigAutoGenDsp" SG_ 1839 NMH_EM_NL_aktiv_4 1;
BA_ "GenSigSwitchedByIgnition" SG_ 1839 NMH_EM_NL_aktiv_5 0;
BA_ "GenSigSendType" SG_ 1839 NMH_EM_NL_aktiv_5 0;
BA_ "GenSigAutoGenSnd" SG_ 1839 NMH_EM_NL_aktiv_5 1;
BA_ "GenSigAutoGenDsp" SG_ 1839 NMH_EM_NL_aktiv_5 1;
BA_ "GenSigSwitchedByIgnition" SG_ 1839 NMH_EM_NL_aktiv_6 0;
BA_ "GenSigSendType" SG_ 1839 NMH_EM_NL_aktiv_6 0;
BA_ "GenSigAutoGenSnd" SG_ 1839 NMH_EM_NL_aktiv_6 1;
BA_ "GenSigAutoGenDsp" SG_ 1839 NMH_EM_NL_aktiv_6 1;
BA_ "GenSigSwitchedByIgnition" SG_ 1839 NMH_EM_NL_aktiv_7 0;
BA_ "GenSigSendType" SG_ 1839 NMH_EM_NL_aktiv_7 0;
BA_ "GenSigAutoGenSnd" SG_ 1839 NMH_EM_NL_aktiv_7 1;
BA_ "GenSigAutoGenDsp" SG_ 1839 NMH_EM_NL_aktiv_7 1;
BA_ "GenSigSwitchedByIgnition" SG_ 1839 NMH_EM_NL_aktiv_8 0;
BA_ "GenSigSendType" SG_ 1839 NMH_EM_NL_aktiv_8 0;
BA_ "GenSigAutoGenSnd" SG_ 1839 NMH_EM_NL_aktiv_8 1;
BA_ "GenSigAutoGenDsp" SG_ 1839 NMH_EM_NL_aktiv_8 1;
BA_ "GenSigSwitchedByIgnition" SG_ 1839 NMH_EM_NL_0 0;
BA_ "GenSigSendType" SG_ 1839 NMH_EM_NL_0 0;
BA_ "GenSigAutoGenSnd" SG_ 1839 NMH_EM_NL_0 1;
BA_ "GenSigAutoGenDsp" SG_ 1839 NMH_EM_NL_0 1;
BA_ "GenSigSwitchedByIgnition" SG_ 1839 NMH_EM_NL_1 0;
BA_ "GenSigSendType" SG_ 1839 NMH_EM_NL_1 0;
BA_ "GenSigAutoGenSnd" SG_ 1839 NMH_EM_NL_1 1;
BA_ "GenSigAutoGenDsp" SG_ 1839 NMH_EM_NL_1 1;
BA_ "GenSigSwitchedByIgnition" SG_ 1839 NMH_EM_NL_2 0;
BA_ "GenSigSendType" SG_ 1839 NMH_EM_NL_2 0;
BA_ "GenSigAutoGenSnd" SG_ 1839 NMH_EM_NL_2 1;
BA_ "GenSigAutoGenDsp" SG_ 1839 NMH_EM_NL_2 1;
BA_ "GenSigSwitchedByIgnition" SG_ 1839 NMH_EM_NL_3 0;
BA_ "GenSigSendType" SG_ 1839 NMH_EM_NL_3 0;
BA_ "GenSigAutoGenSnd" SG_ 1839 NMH_EM_NL_3 1;
BA_ "GenSigAutoGenDsp" SG_ 1839 NMH_EM_NL_3 1;
BA_ "GenSigSwitchedByIgnition" SG_ 1839 NMH_EM_NL_4 0;
BA_ "GenSigSendType" SG_ 1839 NMH_EM_NL_4 0;
BA_ "GenSigAutoGenSnd" SG_ 1839 NMH_EM_NL_4 1;
BA_ "GenSigAutoGenDsp" SG_ 1839 NMH_EM_NL_4 1;
BA_ "GenSigSwitchedByIgnition" SG_ 1839 NMH_EM_NL_5 0;
BA_ "GenSigSendType" SG_ 1839 NMH_EM_NL_5 0;
BA_ "GenSigAutoGenSnd" SG_ 1839 NMH_EM_NL_5 1;
BA_ "GenSigAutoGenDsp" SG_ 1839 NMH_EM_NL_5 1;
BA_ "GenSigSwitchedByIgnition" SG_ 1839 NMH_EM_NL_6 0;
BA_ "GenSigSendType" SG_ 1839 NMH_EM_NL_6 0;
BA_ "GenSigAutoGenSnd" SG_ 1839 NMH_EM_NL_6 1;
BA_ "GenSigAutoGenDsp" SG_ 1839 NMH_EM_NL_6 1;
BA_ "GenSigSwitchedByIgnition" SG_ 1839 NMH_EM_NL_7 0;
BA_ "GenSigSendType" SG_ 1839 NMH_EM_NL_7 0;
BA_ "GenSigAutoGenSnd" SG_ 1839 NMH_EM_NL_7 1;
BA_ "GenSigAutoGenDsp" SG_ 1839 NMH_EM_NL_7 1;
BA_ "GenSigSwitchedByIgnition" SG_ 1839 NMH_EM_TimeOut_Fehler 0;
BA_ "GenSigSendType" SG_ 1839 NMH_EM_TimeOut_Fehler 0;
BA_ "GenSigAutoGenSnd" SG_ 1839 NMH_EM_TimeOut_Fehler 1;
BA_ "GenSigAutoGenDsp" SG_ 1839 NMH_EM_TimeOut_Fehler 1;
BA_ "GenSigSwitchedByIgnition" SG_ 1839 NMH_EM_CAN_Diag_deaktiv 0;
BA_ "GenSigSendType" SG_ 1839 NMH_EM_CAN_Diag_deaktiv 0;
BA_ "GenSigAutoGenSnd" SG_ 1839 NMH_EM_CAN_Diag_deaktiv 1;
BA_ "GenSigAutoGenDsp" SG_ 1839 NMH_EM_CAN_Diag_deaktiv 1;
BA_ "GenSigSwitchedByIgnition" SG_ 1839 NMH_EM_KompSchutz 0;
BA_ "GenSigSendType" SG_ 1839 NMH_EM_KompSchutz 0;
BA_ "GenSigAutoGenSnd" SG_ 1839 NMH_EM_KompSchutz 1;
BA_ "GenSigAutoGenDsp" SG_ 1839 NMH_EM_KompSchutz 1;
BA_ "GenSigSwitchedByIgnition" SG_ 1839 NMH_EM_Mute_Mode 0;
BA_ "GenSigSendType" SG_ 1839 NMH_EM_Mute_Mode 0;
BA_ "GenSigAutoGenSnd" SG_ 1839 NMH_EM_Mute_Mode 1;
BA_ "GenSigAutoGenDsp" SG_ 1839 NMH_EM_Mute_Mode 1;
BA_ "GenSigSwitchedByIgnition" SG_ 1839 NMH_EM_Transport_Mode 0;
BA_ "GenSigSendType" SG_ 1839 NMH_EM_Transport_Mode 0;
BA_ "GenSigAutoGenSnd" SG_ 1839 NMH_EM_Transport_Mode 1;
BA_ "GenSigAutoGenDsp" SG_ 1839 NMH_EM_Transport_Mode 1;
BA_ "GenSigSwitchedByIgnition" SG_ 1839 NMH_EM_Abschaltstufe_aktiv 0;
BA_ "GenSigSendType" SG_ 1839 NMH_EM_Abschaltstufe_aktiv 0;
BA_ "GenSigAutoGenSnd" SG_ 1839 NMH_EM_Abschaltstufe_aktiv 1;
BA_ "GenSigAutoGenDsp" SG_ 1839 NMH_EM_Abschaltstufe_aktiv 1;
BA_ "GenSigSwitchedByIgnition" SG_ 1839 NMH_EM_Eindraht_Fehler 0;
BA_ "GenSigSendType" SG_ 1839 NMH_EM_Eindraht_Fehler 0;
BA_ "GenSigAutoGenSnd" SG_ 1839 NMH_EM_Eindraht_Fehler 1;
BA_ "GenSigAutoGenDsp" SG_ 1839 NMH_EM_Eindraht_Fehler 1;
BA_ "GenSigSwitchedByIgnition" SG_ 1849 NMH_EPB_Start_1 0;
BA_ "GenSigSendType" SG_ 1849 NMH_EPB_Start_1 0;
BA_ "GenSigAutoGenSnd" SG_ 1849 NMH_EPB_Start_1 1;
BA_ "GenSigAutoGenDsp" SG_ 1849 NMH_EPB_Start_1 1;
BA_ "GenSigSwitchedByIgnition" SG_ 1849 NMH_EPB_Start_2 0;
BA_ "GenSigSendType" SG_ 1849 NMH_EPB_Start_2 0;
BA_ "GenSigAutoGenSnd" SG_ 1849 NMH_EPB_Start_2 1;
BA_ "GenSigAutoGenDsp" SG_ 1849 NMH_EPB_Start_2 1;
BA_ "GenSigSwitchedByIgnition" SG_ 1849 NMH_EPB_Normal_Mode_1 0;
BA_ "GenSigSendType" SG_ 1849 NMH_EPB_Normal_Mode_1 0;
BA_ "GenSigAutoGenSnd" SG_ 1849 NMH_EPB_Normal_Mode_1 1;
BA_ "GenSigAutoGenDsp" SG_ 1849 NMH_EPB_Normal_Mode_1 1;
BA_ "GenSigSwitchedByIgnition" SG_ 1849 NMH_EPB_Normal_Mode_2 0;
BA_ "GenSigSendType" SG_ 1849 NMH_EPB_Normal_Mode_2 0;
BA_ "GenSigAutoGenSnd" SG_ 1849 NMH_EPB_Normal_Mode_2 1;
BA_ "GenSigAutoGenDsp" SG_ 1849 NMH_EPB_Normal_Mode_2 1;
BA_ "GenSigSwitchedByIgnition" SG_ 1849 NMH_EPB_Car_WakeUp 0;
BA_ "GenSigSendType" SG_ 1849 NMH_EPB_Car_WakeUp 0;
BA_ "GenSigAutoGenSnd" SG_ 1849 NMH_EPB_Car_WakeUp 1;
BA_ "GenSigAutoGenDsp" SG_ 1849 NMH_EPB_Car_WakeUp 1;
BA_ "GenSigSwitchedByIgnition" SG_ 1849 NMH_EPB_Per_WakeUp 0;
BA_ "GenSigSendType" SG_ 1849 NMH_EPB_Per_WakeUp 0;
BA_ "GenSigAutoGenSnd" SG_ 1849 NMH_EPB_Per_WakeUp 1;
BA_ "GenSigAutoGenDsp" SG_ 1849 NMH_EPB_Per_WakeUp 1;
BA_ "GenSigSwitchedByIgnition" SG_ 1849 NMH_EPB_Fkt_WakeUp 0;
BA_ "GenSigSendType" SG_ 1849 NMH_EPB_Fkt_WakeUp 0;
BA_ "GenSigAutoGenSnd" SG_ 1849 NMH_EPB_Fkt_WakeUp 1;
BA_ "GenSigAutoGenDsp" SG_ 1849 NMH_EPB_Fkt_WakeUp 1;
BA_ "GenSigSwitchedByIgnition" SG_ 1849 NMH_EPB_NM_aktiv_Klemme_15 0;
BA_ "GenSigSendType" SG_ 1849 NMH_EPB_NM_aktiv_Klemme_15 0;
BA_ "GenSigAutoGenSnd" SG_ 1849 NMH_EPB_NM_aktiv_Klemme_15 1;
BA_ "GenSigAutoGenDsp" SG_ 1849 NMH_EPB_NM_aktiv_Klemme_15 1;
BA_ "GenSigSwitchedByIgnition" SG_ 1849 NMH_EPB_NM_aktiv_Diagnose 0;
BA_ "GenSigSendType" SG_ 1849 NMH_EPB_NM_aktiv_Diagnose 0;
BA_ "GenSigAutoGenSnd" SG_ 1849 NMH_EPB_NM_aktiv_Diagnose 1;
BA_ "GenSigAutoGenDsp" SG_ 1849 NMH_EPB_NM_aktiv_Diagnose 1;
BA_ "GenSigSwitchedByIgnition" SG_ 1849 NMH_EPB_NM_aktiv_Start 0;
BA_ "GenSigSendType" SG_ 1849 NMH_EPB_NM_aktiv_Start 0;
BA_ "GenSigAutoGenSnd" SG_ 1849 NMH_EPB_NM_aktiv_Start 1;
BA_ "GenSigAutoGenDsp" SG_ 1849 NMH_EPB_NM_aktiv_Start 1;
BA_ "GenSigSwitchedByIgnition" SG_ 1849 NMH_EPB_NL_aktiv_4 0;
BA_ "GenSigSendType" SG_ 1849 NMH_EPB_NL_aktiv_4 0;
BA_ "GenSigAutoGenSnd" SG_ 1849 NMH_EPB_NL_aktiv_4 1;
BA_ "GenSigAutoGenDsp" SG_ 1849 NMH_EPB_NL_aktiv_4 1;
BA_ "GenSigSwitchedByIgnition" SG_ 1849 NMH_EPB_NL_aktiv_5 0;
BA_ "GenSigSendType" SG_ 1849 NMH_EPB_NL_aktiv_5 0;
BA_ "GenSigAutoGenSnd" SG_ 1849 NMH_EPB_NL_aktiv_5 1;
BA_ "GenSigAutoGenDsp" SG_ 1849 NMH_EPB_NL_aktiv_5 1;
BA_ "GenSigSwitchedByIgnition" SG_ 1849 NMH_EPB_NL_aktiv_6 0;
BA_ "GenSigSendType" SG_ 1849 NMH_EPB_NL_aktiv_6 0;
BA_ "GenSigAutoGenSnd" SG_ 1849 NMH_EPB_NL_aktiv_6 1;
BA_ "GenSigAutoGenDsp" SG_ 1849 NMH_EPB_NL_aktiv_6 1;
BA_ "GenSigSwitchedByIgnition" SG_ 1849 NMH_EPB_NL_aktiv_7 0;
BA_ "GenSigSendType" SG_ 1849 NMH_EPB_NL_aktiv_7 0;
BA_ "GenSigAutoGenSnd" SG_ 1849 NMH_EPB_NL_aktiv_7 1;
BA_ "GenSigAutoGenDsp" SG_ 1849 NMH_EPB_NL_aktiv_7 1;
BA_ "GenSigSwitchedByIgnition" SG_ 1849 NMH_EPB_NL_aktiv_8 0;
BA_ "GenSigSendType" SG_ 1849 NMH_EPB_NL_aktiv_8 0;
BA_ "GenSigAutoGenSnd" SG_ 1849 NMH_EPB_NL_aktiv_8 1;
BA_ "GenSigAutoGenDsp" SG_ 1849 NMH_EPB_NL_aktiv_8 1;
BA_ "GenSigSwitchedByIgnition" SG_ 1849 NMH_EPB_NL_0 0;
BA_ "GenSigSendType" SG_ 1849 NMH_EPB_NL_0 0;
BA_ "GenSigAutoGenSnd" SG_ 1849 NMH_EPB_NL_0 1;
BA_ "GenSigAutoGenDsp" SG_ 1849 NMH_EPB_NL_0 1;
BA_ "GenSigSwitchedByIgnition" SG_ 1849 NMH_EPB_NL_1 0;
BA_ "GenSigSendType" SG_ 1849 NMH_EPB_NL_1 0;
BA_ "GenSigAutoGenSnd" SG_ 1849 NMH_EPB_NL_1 1;
BA_ "GenSigAutoGenDsp" SG_ 1849 NMH_EPB_NL_1 1;
BA_ "GenSigSwitchedByIgnition" SG_ 1849 NMH_EPB_NL_2 0;
BA_ "GenSigSendType" SG_ 1849 NMH_EPB_NL_2 0;
BA_ "GenSigAutoGenSnd" SG_ 1849 NMH_EPB_NL_2 1;
BA_ "GenSigAutoGenDsp" SG_ 1849 NMH_EPB_NL_2 1;
BA_ "GenSigSwitchedByIgnition" SG_ 1849 NMH_EPB_NL_3 0;
BA_ "GenSigSendType" SG_ 1849 NMH_EPB_NL_3 0;
BA_ "GenSigAutoGenSnd" SG_ 1849 NMH_EPB_NL_3 1;
BA_ "GenSigAutoGenDsp" SG_ 1849 NMH_EPB_NL_3 1;
BA_ "GenSigSwitchedByIgnition" SG_ 1849 NMH_EPB_NL_4 0;
BA_ "GenSigSendType" SG_ 1849 NMH_EPB_NL_4 0;
BA_ "GenSigAutoGenSnd" SG_ 1849 NMH_EPB_NL_4 1;
BA_ "GenSigAutoGenDsp" SG_ 1849 NMH_EPB_NL_4 1;
BA_ "GenSigSwitchedByIgnition" SG_ 1849 NMH_EPB_NL_5 0;
BA_ "GenSigSendType" SG_ 1849 NMH_EPB_NL_5 0;
BA_ "GenSigAutoGenSnd" SG_ 1849 NMH_EPB_NL_5 1;
BA_ "GenSigAutoGenDsp" SG_ 1849 NMH_EPB_NL_5 1;
BA_ "GenSigSwitchedByIgnition" SG_ 1849 NMH_EPB_NL_6 0;
BA_ "GenSigSendType" SG_ 1849 NMH_EPB_NL_6 0;
BA_ "GenSigAutoGenSnd" SG_ 1849 NMH_EPB_NL_6 1;
BA_ "GenSigAutoGenDsp" SG_ 1849 NMH_EPB_NL_6 1;
BA_ "GenSigSwitchedByIgnition" SG_ 1849 NMH_EPB_NL_7 0;
BA_ "GenSigSendType" SG_ 1849 NMH_EPB_NL_7 0;
BA_ "GenSigAutoGenSnd" SG_ 1849 NMH_EPB_NL_7 1;
BA_ "GenSigAutoGenDsp" SG_ 1849 NMH_EPB_NL_7 1;
BA_ "GenSigSwitchedByIgnition" SG_ 1849 NMH_EPB_TimeOut_Fehler 0;
BA_ "GenSigSendType" SG_ 1849 NMH_EPB_TimeOut_Fehler 0;
BA_ "GenSigAutoGenSnd" SG_ 1849 NMH_EPB_TimeOut_Fehler 1;
BA_ "GenSigAutoGenDsp" SG_ 1849 NMH_EPB_TimeOut_Fehler 1;
BA_ "GenSigSwitchedByIgnition" SG_ 1849 NMH_EPB_CAN_Diag_deaktiv 0;
BA_ "GenSigSendType" SG_ 1849 NMH_EPB_CAN_Diag_deaktiv 0;
BA_ "GenSigAutoGenSnd" SG_ 1849 NMH_EPB_CAN_Diag_deaktiv 1;
BA_ "GenSigAutoGenDsp" SG_ 1849 NMH_EPB_CAN_Diag_deaktiv 1;
BA_ "GenSigSwitchedByIgnition" SG_ 1849 NMH_EPB_KompSchutz 0;
BA_ "GenSigSendType" SG_ 1849 NMH_EPB_KompSchutz 0;
BA_ "GenSigAutoGenSnd" SG_ 1849 NMH_EPB_KompSchutz 1;
BA_ "GenSigAutoGenDsp" SG_ 1849 NMH_EPB_KompSchutz 1;
BA_ "GenSigSwitchedByIgnition" SG_ 1849 NMH_EPB_Mute_Mode 0;
BA_ "GenSigSendType" SG_ 1849 NMH_EPB_Mute_Mode 0;
BA_ "GenSigAutoGenSnd" SG_ 1849 NMH_EPB_Mute_Mode 1;
BA_ "GenSigAutoGenDsp" SG_ 1849 NMH_EPB_Mute_Mode 1;
BA_ "GenSigSwitchedByIgnition" SG_ 1849 NMH_EPB_Transport_Mode 0;
BA_ "GenSigSendType" SG_ 1849 NMH_EPB_Transport_Mode 0;
BA_ "GenSigAutoGenSnd" SG_ 1849 NMH_EPB_Transport_Mode 1;
BA_ "GenSigAutoGenDsp" SG_ 1849 NMH_EPB_Transport_Mode 1;
BA_ "GenSigSwitchedByIgnition" SG_ 1849 NMH_EPB_Abschaltstufe_aktiv 0;
BA_ "GenSigSendType" SG_ 1849 NMH_EPB_Abschaltstufe_aktiv 0;
BA_ "GenSigAutoGenSnd" SG_ 1849 NMH_EPB_Abschaltstufe_aktiv 1;
BA_ "GenSigAutoGenDsp" SG_ 1849 NMH_EPB_Abschaltstufe_aktiv 1;
BA_ "GenSigSwitchedByIgnition" SG_ 1849 NMH_EPB_Eindraht_Fehler 0;
BA_ "GenSigSendType" SG_ 1849 NMH_EPB_Eindraht_Fehler 0;
BA_ "GenSigAutoGenSnd" SG_ 1849 NMH_EPB_Eindraht_Fehler 1;
BA_ "GenSigAutoGenDsp" SG_ 1849 NMH_EPB_Eindraht_Fehler 1;
BA_ "GenSigSwitchedByIgnition" SG_ 1824 NMH_GW_Start_1 0;
BA_ "GenSigStartValue" SG_ 1824 NMH_GW_Start_1 1;
BA_ "GenSigSendType" SG_ 1824 NMH_GW_Start_1 0;
BA_ "GenSigAutoGenSnd" SG_ 1824 NMH_GW_Start_1 1;
BA_ "GenSigAutoGenDsp" SG_ 1824 NMH_GW_Start_1 1;
BA_ "GenSigSwitchedByIgnition" SG_ 1824 NMH_GW_Start_2 0;
BA_ "GenSigSendType" SG_ 1824 NMH_GW_Start_2 0;
BA_ "GenSigAutoGenSnd" SG_ 1824 NMH_GW_Start_2 1;
BA_ "GenSigAutoGenDsp" SG_ 1824 NMH_GW_Start_2 1;
BA_ "GenSigSwitchedByIgnition" SG_ 1824 NMH_GW_Normal_Mode_1 0;
BA_ "GenSigSendType" SG_ 1824 NMH_GW_Normal_Mode_1 0;
BA_ "GenSigAutoGenSnd" SG_ 1824 NMH_GW_Normal_Mode_1 1;
BA_ "GenSigAutoGenDsp" SG_ 1824 NMH_GW_Normal_Mode_1 1;
BA_ "GenSigSwitchedByIgnition" SG_ 1824 NMH_GW_Normal_Mode_2 0;
BA_ "GenSigSendType" SG_ 1824 NMH_GW_Normal_Mode_2 0;
BA_ "GenSigAutoGenSnd" SG_ 1824 NMH_GW_Normal_Mode_2 1;
BA_ "GenSigAutoGenDsp" SG_ 1824 NMH_GW_Normal_Mode_2 1;
BA_ "GenSigSwitchedByIgnition" SG_ 1824 NMH_GW_Car_WakeUp 0;
BA_ "GenSigSendType" SG_ 1824 NMH_GW_Car_WakeUp 0;
BA_ "GenSigAutoGenSnd" SG_ 1824 NMH_GW_Car_WakeUp 1;
BA_ "GenSigAutoGenDsp" SG_ 1824 NMH_GW_Car_WakeUp 1;
BA_ "GenSigSwitchedByIgnition" SG_ 1824 NMH_GW_Per_WakeUp 0;
BA_ "GenSigSendType" SG_ 1824 NMH_GW_Per_WakeUp 0;
BA_ "GenSigAutoGenSnd" SG_ 1824 NMH_GW_Per_WakeUp 1;
BA_ "GenSigAutoGenDsp" SG_ 1824 NMH_GW_Per_WakeUp 1;
BA_ "GenSigSwitchedByIgnition" SG_ 1824 NMH_GW_Fkt_WakeUp 0;
BA_ "GenSigSendType" SG_ 1824 NMH_GW_Fkt_WakeUp 0;
BA_ "GenSigAutoGenSnd" SG_ 1824 NMH_GW_Fkt_WakeUp 1;
BA_ "GenSigAutoGenDsp" SG_ 1824 NMH_GW_Fkt_WakeUp 1;
BA_ "GenSigSwitchedByIgnition" SG_ 1824 NMH_GW_NM_aktiv_Klemme_15 0;
BA_ "GenSigSendType" SG_ 1824 NMH_GW_NM_aktiv_Klemme_15 0;
BA_ "GenSigAutoGenSnd" SG_ 1824 NMH_GW_NM_aktiv_Klemme_15 1;
BA_ "GenSigAutoGenDsp" SG_ 1824 NMH_GW_NM_aktiv_Klemme_15 1;
BA_ "GenSigSwitchedByIgnition" SG_ 1824 NMH_GW_NM_aktiv_Diagnose 0;
BA_ "GenSigSendType" SG_ 1824 NMH_GW_NM_aktiv_Diagnose 0;
BA_ "GenSigAutoGenSnd" SG_ 1824 NMH_GW_NM_aktiv_Diagnose 1;
BA_ "GenSigAutoGenDsp" SG_ 1824 NMH_GW_NM_aktiv_Diagnose 1;
BA_ "GenSigSwitchedByIgnition" SG_ 1824 NMH_GW_NM_aktiv_Start 0;
BA_ "GenSigSendType" SG_ 1824 NMH_GW_NM_aktiv_Start 0;
BA_ "GenSigAutoGenSnd" SG_ 1824 NMH_GW_NM_aktiv_Start 1;
BA_ "GenSigAutoGenDsp" SG_ 1824 NMH_GW_NM_aktiv_Start 1;
BA_ "GenSigSwitchedByIgnition" SG_ 1824 NMH_GW_NL_aktiv_4 0;
BA_ "GenSigSendType" SG_ 1824 NMH_GW_NL_aktiv_4 0;
BA_ "GenSigAutoGenSnd" SG_ 1824 NMH_GW_NL_aktiv_4 1;
BA_ "GenSigAutoGenDsp" SG_ 1824 NMH_GW_NL_aktiv_4 1;
BA_ "GenSigSwitchedByIgnition" SG_ 1824 NMH_GW_NL_aktiv_5 0;
BA_ "GenSigSendType" SG_ 1824 NMH_GW_NL_aktiv_5 0;
BA_ "GenSigAutoGenSnd" SG_ 1824 NMH_GW_NL_aktiv_5 1;
BA_ "GenSigAutoGenDsp" SG_ 1824 NMH_GW_NL_aktiv_5 1;
BA_ "GenSigSwitchedByIgnition" SG_ 1824 NMH_GW_NL_aktiv_6 0;
BA_ "GenSigSendType" SG_ 1824 NMH_GW_NL_aktiv_6 0;
BA_ "GenSigAutoGenSnd" SG_ 1824 NMH_GW_NL_aktiv_6 1;
BA_ "GenSigAutoGenDsp" SG_ 1824 NMH_GW_NL_aktiv_6 1;
BA_ "GenSigSwitchedByIgnition" SG_ 1824 NMH_GW_NL_aktiv_7 0;
BA_ "GenSigSendType" SG_ 1824 NMH_GW_NL_aktiv_7 0;
BA_ "GenSigAutoGenSnd" SG_ 1824 NMH_GW_NL_aktiv_7 1;
BA_ "GenSigAutoGenDsp" SG_ 1824 NMH_GW_NL_aktiv_7 1;
BA_ "GenSigSwitchedByIgnition" SG_ 1824 NMH_GW_NL_aktiv_8 0;
BA_ "GenSigSendType" SG_ 1824 NMH_GW_NL_aktiv_8 0;
BA_ "GenSigAutoGenSnd" SG_ 1824 NMH_GW_NL_aktiv_8 1;
BA_ "GenSigAutoGenDsp" SG_ 1824 NMH_GW_NL_aktiv_8 1;
BA_ "GenSigSwitchedByIgnition" SG_ 1824 NMH_GW_NL_0 0;
BA_ "GenSigSendType" SG_ 1824 NMH_GW_NL_0 0;
BA_ "GenSigAutoGenSnd" SG_ 1824 NMH_GW_NL_0 1;
BA_ "GenSigAutoGenDsp" SG_ 1824 NMH_GW_NL_0 1;
BA_ "GenSigSwitchedByIgnition" SG_ 1824 NMH_GW_NL_1 0;
BA_ "GenSigSendType" SG_ 1824 NMH_GW_NL_1 0;
BA_ "GenSigAutoGenSnd" SG_ 1824 NMH_GW_NL_1 1;
BA_ "GenSigAutoGenDsp" SG_ 1824 NMH_GW_NL_1 1;
BA_ "GenSigSwitchedByIgnition" SG_ 1824 NMH_GW_NL_2 0;
BA_ "GenSigSendType" SG_ 1824 NMH_GW_NL_2 0;
BA_ "GenSigAutoGenSnd" SG_ 1824 NMH_GW_NL_2 1;
BA_ "GenSigAutoGenDsp" SG_ 1824 NMH_GW_NL_2 1;
BA_ "GenSigSwitchedByIgnition" SG_ 1824 NMH_GW_NL_3 0;
BA_ "GenSigSendType" SG_ 1824 NMH_GW_NL_3 0;
BA_ "GenSigAutoGenSnd" SG_ 1824 NMH_GW_NL_3 1;
BA_ "GenSigAutoGenDsp" SG_ 1824 NMH_GW_NL_3 1;
BA_ "GenSigSwitchedByIgnition" SG_ 1824 NMH_GW_NL_4 0;
BA_ "GenSigSendType" SG_ 1824 NMH_GW_NL_4 0;
BA_ "GenSigAutoGenSnd" SG_ 1824 NMH_GW_NL_4 1;
BA_ "GenSigAutoGenDsp" SG_ 1824 NMH_GW_NL_4 1;
BA_ "GenSigSwitchedByIgnition" SG_ 1824 NMH_GW_NL_5 0;
BA_ "GenSigSendType" SG_ 1824 NMH_GW_NL_5 0;
BA_ "GenSigAutoGenSnd" SG_ 1824 NMH_GW_NL_5 1;
BA_ "GenSigAutoGenDsp" SG_ 1824 NMH_GW_NL_5 1;
BA_ "GenSigSwitchedByIgnition" SG_ 1824 NMH_GW_NL_6 0;
BA_ "GenSigSendType" SG_ 1824 NMH_GW_NL_6 0;
BA_ "GenSigAutoGenSnd" SG_ 1824 NMH_GW_NL_6 1;
BA_ "GenSigAutoGenDsp" SG_ 1824 NMH_GW_NL_6 1;
BA_ "GenSigSwitchedByIgnition" SG_ 1824 NMH_GW_NL_7 0;
BA_ "GenSigSendType" SG_ 1824 NMH_GW_NL_7 0;
BA_ "GenSigAutoGenSnd" SG_ 1824 NMH_GW_NL_7 1;
BA_ "GenSigAutoGenDsp" SG_ 1824 NMH_GW_NL_7 1;
BA_ "GenSigSwitchedByIgnition" SG_ 1824 NMH_GW_TimeOut_Fehler 0;
BA_ "GenSigSendType" SG_ 1824 NMH_GW_TimeOut_Fehler 0;
BA_ "GenSigAutoGenSnd" SG_ 1824 NMH_GW_TimeOut_Fehler 1;
BA_ "GenSigAutoGenDsp" SG_ 1824 NMH_GW_TimeOut_Fehler 1;
BA_ "GenSigSwitchedByIgnition" SG_ 1824 NMH_GW_CAN_Diag_deaktiv 0;
BA_ "GenSigSendType" SG_ 1824 NMH_GW_CAN_Diag_deaktiv 0;
BA_ "GenSigAutoGenSnd" SG_ 1824 NMH_GW_CAN_Diag_deaktiv 1;
BA_ "GenSigAutoGenDsp" SG_ 1824 NMH_GW_CAN_Diag_deaktiv 1;
BA_ "GenSigSwitchedByIgnition" SG_ 1824 NMH_GW_KompSchutz 0;
BA_ "GenSigSendType" SG_ 1824 NMH_GW_KompSchutz 0;
BA_ "GenSigAutoGenSnd" SG_ 1824 NMH_GW_KompSchutz 1;
BA_ "GenSigAutoGenDsp" SG_ 1824 NMH_GW_KompSchutz 1;
BA_ "GenSigSwitchedByIgnition" SG_ 1824 NMH_GW_Mute_Mode 0;
BA_ "GenSigSendType" SG_ 1824 NMH_GW_Mute_Mode 0;
BA_ "GenSigAutoGenSnd" SG_ 1824 NMH_GW_Mute_Mode 1;
BA_ "GenSigAutoGenDsp" SG_ 1824 NMH_GW_Mute_Mode 1;
BA_ "GenSigSwitchedByIgnition" SG_ 1824 NMH_GW_Transport_Mode 0;
BA_ "GenSigSendType" SG_ 1824 NMH_GW_Transport_Mode 0;
BA_ "GenSigAutoGenSnd" SG_ 1824 NMH_GW_Transport_Mode 1;
BA_ "GenSigAutoGenDsp" SG_ 1824 NMH_GW_Transport_Mode 1;
BA_ "GenSigSwitchedByIgnition" SG_ 1824 NMH_GW_Abschaltstufe_aktiv 0;
BA_ "GenSigSendType" SG_ 1824 NMH_GW_Abschaltstufe_aktiv 0;
BA_ "GenSigAutoGenSnd" SG_ 1824 NMH_GW_Abschaltstufe_aktiv 1;
BA_ "GenSigAutoGenDsp" SG_ 1824 NMH_GW_Abschaltstufe_aktiv 1;
BA_ "GenSigSwitchedByIgnition" SG_ 1824 NMH_GW_Eindraht_Fehler 0;
BA_ "GenSigSendType" SG_ 1824 NMH_GW_Eindraht_Fehler 0;
BA_ "GenSigAutoGenSnd" SG_ 1824 NMH_GW_Eindraht_Fehler 1;
BA_ "GenSigAutoGenDsp" SG_ 1824 NMH_GW_Eindraht_Fehler 1;
BA_ "GenSigSwitchedByIgnition" SG_ 1836 NMH_Ladegeraet_Start_1 0;
BA_ "GenSigSendType" SG_ 1836 NMH_Ladegeraet_Start_1 0;
BA_ "GenSigAutoGenSnd" SG_ 1836 NMH_Ladegeraet_Start_1 1;
BA_ "GenSigAutoGenDsp" SG_ 1836 NMH_Ladegeraet_Start_1 1;
BA_ "GenSigSwitchedByIgnition" SG_ 1836 NMH_Ladegeraet_Start_2 0;
BA_ "GenSigSendType" SG_ 1836 NMH_Ladegeraet_Start_2 0;
BA_ "GenSigAutoGenSnd" SG_ 1836 NMH_Ladegeraet_Start_2 1;
BA_ "GenSigAutoGenDsp" SG_ 1836 NMH_Ladegeraet_Start_2 1;
BA_ "GenSigSwitchedByIgnition" SG_ 1836 NMH_Ladegeraet_Normal_Mode_1 0;
BA_ "GenSigSendType" SG_ 1836 NMH_Ladegeraet_Normal_Mode_1 0;
BA_ "GenSigAutoGenSnd" SG_ 1836 NMH_Ladegeraet_Normal_Mode_1 1;
BA_ "GenSigAutoGenDsp" SG_ 1836 NMH_Ladegeraet_Normal_Mode_1 1;
BA_ "GenSigSwitchedByIgnition" SG_ 1836 NMH_Ladegeraet_Normal_Mode_2 0;
BA_ "GenSigSendType" SG_ 1836 NMH_Ladegeraet_Normal_Mode_2 0;
BA_ "GenSigAutoGenSnd" SG_ 1836 NMH_Ladegeraet_Normal_Mode_2 1;
BA_ "GenSigAutoGenDsp" SG_ 1836 NMH_Ladegeraet_Normal_Mode_2 1;
BA_ "GenSigSwitchedByIgnition" SG_ 1836 NMH_Ladegeraet_Car_WakeUp 0;
BA_ "GenSigSendType" SG_ 1836 NMH_Ladegeraet_Car_WakeUp 0;
BA_ "GenSigAutoGenSnd" SG_ 1836 NMH_Ladegeraet_Car_WakeUp 1;
BA_ "GenSigAutoGenDsp" SG_ 1836 NMH_Ladegeraet_Car_WakeUp 1;
BA_ "GenSigSwitchedByIgnition" SG_ 1836 NMH_Ladegeraet_Per_WakeUp 0;
BA_ "GenSigSendType" SG_ 1836 NMH_Ladegeraet_Per_WakeUp 0;
BA_ "GenSigAutoGenSnd" SG_ 1836 NMH_Ladegeraet_Per_WakeUp 1;
BA_ "GenSigAutoGenDsp" SG_ 1836 NMH_Ladegeraet_Per_WakeUp 1;
BA_ "GenSigSwitchedByIgnition" SG_ 1836 NMH_Ladegeraet_Fkt_WakeUp 0;
BA_ "GenSigSendType" SG_ 1836 NMH_Ladegeraet_Fkt_WakeUp 0;
BA_ "GenSigAutoGenSnd" SG_ 1836 NMH_Ladegeraet_Fkt_WakeUp 1;
BA_ "GenSigAutoGenDsp" SG_ 1836 NMH_Ladegeraet_Fkt_WakeUp 1;
BA_ "GenSigSwitchedByIgnition" SG_ 1836 NMH_Ladegeraet_NM_aktiv_Klemm000 0;
BA_ "GenSigSendType" SG_ 1836 NMH_Ladegeraet_NM_aktiv_Klemm000 0;
BA_ "GenSigAutoGenSnd" SG_ 1836 NMH_Ladegeraet_NM_aktiv_Klemm000 1;
BA_ "GenSigAutoGenDsp" SG_ 1836 NMH_Ladegeraet_NM_aktiv_Klemm000 1;
BA_ "GenSigSwitchedByIgnition" SG_ 1836 NMH_Ladegeraet_NM_aktiv_Diagnose 0;
BA_ "GenSigSendType" SG_ 1836 NMH_Ladegeraet_NM_aktiv_Diagnose 0;
BA_ "GenSigAutoGenSnd" SG_ 1836 NMH_Ladegeraet_NM_aktiv_Diagnose 1;
BA_ "GenSigAutoGenDsp" SG_ 1836 NMH_Ladegeraet_NM_aktiv_Diagnose 1;
BA_ "GenSigSwitchedByIgnition" SG_ 1836 NMH_Ladegeraet_NM_aktiv_Start 0;
BA_ "GenSigSendType" SG_ 1836 NMH_Ladegeraet_NM_aktiv_Start 0;
BA_ "GenSigAutoGenSnd" SG_ 1836 NMH_Ladegeraet_NM_aktiv_Start 1;
BA_ "GenSigAutoGenDsp" SG_ 1836 NMH_Ladegeraet_NM_aktiv_Start 1;
BA_ "GenSigSwitchedByIgnition" SG_ 1836 NMH_Ladegeraet_NL_aktiv_4 0;
BA_ "GenSigSendType" SG_ 1836 NMH_Ladegeraet_NL_aktiv_4 0;
BA_ "GenSigAutoGenSnd" SG_ 1836 NMH_Ladegeraet_NL_aktiv_4 1;
BA_ "GenSigAutoGenDsp" SG_ 1836 NMH_Ladegeraet_NL_aktiv_4 1;
BA_ "GenSigSwitchedByIgnition" SG_ 1836 NMH_Ladegeraet_NL_aktiv_5 0;
BA_ "GenSigSendType" SG_ 1836 NMH_Ladegeraet_NL_aktiv_5 0;
BA_ "GenSigAutoGenSnd" SG_ 1836 NMH_Ladegeraet_NL_aktiv_5 1;
BA_ "GenSigAutoGenDsp" SG_ 1836 NMH_Ladegeraet_NL_aktiv_5 1;
BA_ "GenSigSwitchedByIgnition" SG_ 1836 NMH_Ladegeraet_NL_aktiv_6 0;
BA_ "GenSigSendType" SG_ 1836 NMH_Ladegeraet_NL_aktiv_6 0;
BA_ "GenSigAutoGenSnd" SG_ 1836 NMH_Ladegeraet_NL_aktiv_6 1;
BA_ "GenSigAutoGenDsp" SG_ 1836 NMH_Ladegeraet_NL_aktiv_6 1;
BA_ "GenSigSwitchedByIgnition" SG_ 1836 NMH_Ladegeraet_NL_aktiv_7 0;
BA_ "GenSigSendType" SG_ 1836 NMH_Ladegeraet_NL_aktiv_7 0;
BA_ "GenSigAutoGenSnd" SG_ 1836 NMH_Ladegeraet_NL_aktiv_7 1;
BA_ "GenSigAutoGenDsp" SG_ 1836 NMH_Ladegeraet_NL_aktiv_7 1;
BA_ "GenSigSwitchedByIgnition" SG_ 1836 NMH_Ladegeraet_NL_aktiv_8 0;
BA_ "GenSigSendType" SG_ 1836 NMH_Ladegeraet_NL_aktiv_8 0;
BA_ "GenSigAutoGenSnd" SG_ 1836 NMH_Ladegeraet_NL_aktiv_8 1;
BA_ "GenSigAutoGenDsp" SG_ 1836 NMH_Ladegeraet_NL_aktiv_8 1;
BA_ "GenSigSwitchedByIgnition" SG_ 1836 NMH_Ladegeraet_NL_0 0;
BA_ "GenSigSendType" SG_ 1836 NMH_Ladegeraet_NL_0 0;
BA_ "GenSigAutoGenSnd" SG_ 1836 NMH_Ladegeraet_NL_0 1;
BA_ "GenSigAutoGenDsp" SG_ 1836 NMH_Ladegeraet_NL_0 1;
BA_ "GenSigSwitchedByIgnition" SG_ 1836 NMH_Ladegeraet_NL_1 0;
BA_ "GenSigSendType" SG_ 1836 NMH_Ladegeraet_NL_1 0;
BA_ "GenSigAutoGenSnd" SG_ 1836 NMH_Ladegeraet_NL_1 1;
BA_ "GenSigAutoGenDsp" SG_ 1836 NMH_Ladegeraet_NL_1 1;
BA_ "GenSigSwitchedByIgnition" SG_ 1836 NMH_Ladegeraet_NL_2 0;
BA_ "GenSigSendType" SG_ 1836 NMH_Ladegeraet_NL_2 0;
BA_ "GenSigAutoGenSnd" SG_ 1836 NMH_Ladegeraet_NL_2 1;
BA_ "GenSigAutoGenDsp" SG_ 1836 NMH_Ladegeraet_NL_2 1;
BA_ "GenSigSwitchedByIgnition" SG_ 1836 NMH_Ladegeraet_NL_3 0;
BA_ "GenSigSendType" SG_ 1836 NMH_Ladegeraet_NL_3 0;
BA_ "GenSigAutoGenSnd" SG_ 1836 NMH_Ladegeraet_NL_3 1;
BA_ "GenSigAutoGenDsp" SG_ 1836 NMH_Ladegeraet_NL_3 1;
BA_ "GenSigSwitchedByIgnition" SG_ 1836 NMH_Ladegeraet_NL_4 0;
BA_ "GenSigSendType" SG_ 1836 NMH_Ladegeraet_NL_4 0;
BA_ "GenSigAutoGenSnd" SG_ 1836 NMH_Ladegeraet_NL_4 1;
BA_ "GenSigAutoGenDsp" SG_ 1836 NMH_Ladegeraet_NL_4 1;
BA_ "GenSigSwitchedByIgnition" SG_ 1836 NMH_Ladegeraet_NL_5 0;
BA_ "GenSigSendType" SG_ 1836 NMH_Ladegeraet_NL_5 0;
BA_ "GenSigAutoGenSnd" SG_ 1836 NMH_Ladegeraet_NL_5 1;
BA_ "GenSigAutoGenDsp" SG_ 1836 NMH_Ladegeraet_NL_5 1;
BA_ "GenSigSwitchedByIgnition" SG_ 1836 NMH_Ladegeraet_NL_6 0;
BA_ "GenSigSendType" SG_ 1836 NMH_Ladegeraet_NL_6 0;
BA_ "GenSigAutoGenSnd" SG_ 1836 NMH_Ladegeraet_NL_6 1;
BA_ "GenSigAutoGenDsp" SG_ 1836 NMH_Ladegeraet_NL_6 1;
BA_ "GenSigSwitchedByIgnition" SG_ 1836 NMH_Ladegeraet_NL_7 0;
BA_ "GenSigSendType" SG_ 1836 NMH_Ladegeraet_NL_7 0;
BA_ "GenSigAutoGenSnd" SG_ 1836 NMH_Ladegeraet_NL_7 1;
BA_ "GenSigAutoGenDsp" SG_ 1836 NMH_Ladegeraet_NL_7 1;
BA_ "GenSigSwitchedByIgnition" SG_ 1836 NMH_Ladegeraet_TimeOut_Fehler 0;
BA_ "GenSigSendType" SG_ 1836 NMH_Ladegeraet_TimeOut_Fehler 0;
BA_ "GenSigAutoGenSnd" SG_ 1836 NMH_Ladegeraet_TimeOut_Fehler 1;
BA_ "GenSigAutoGenDsp" SG_ 1836 NMH_Ladegeraet_TimeOut_Fehler 1;
BA_ "GenSigSwitchedByIgnition" SG_ 1836 NMH_Ladegeraet_CAN_Diag_deaktiv 0;
BA_ "GenSigSendType" SG_ 1836 NMH_Ladegeraet_CAN_Diag_deaktiv 0;
BA_ "GenSigAutoGenSnd" SG_ 1836 NMH_Ladegeraet_CAN_Diag_deaktiv 1;
BA_ "GenSigAutoGenDsp" SG_ 1836 NMH_Ladegeraet_CAN_Diag_deaktiv 1;
BA_ "GenSigSwitchedByIgnition" SG_ 1836 NMH_Ladegeraet_KompSchutz 0;
BA_ "GenSigSendType" SG_ 1836 NMH_Ladegeraet_KompSchutz 0;
BA_ "GenSigAutoGenSnd" SG_ 1836 NMH_Ladegeraet_KompSchutz 1;
BA_ "GenSigAutoGenDsp" SG_ 1836 NMH_Ladegeraet_KompSchutz 1;
BA_ "GenSigSwitchedByIgnition" SG_ 1836 NMH_Ladegeraet_Mute_Mode 0;
BA_ "GenSigSendType" SG_ 1836 NMH_Ladegeraet_Mute_Mode 0;
BA_ "GenSigAutoGenSnd" SG_ 1836 NMH_Ladegeraet_Mute_Mode 1;
BA_ "GenSigAutoGenDsp" SG_ 1836 NMH_Ladegeraet_Mute_Mode 1;
BA_ "GenSigSwitchedByIgnition" SG_ 1836 NMH_Ladegeraet_Transport_Mode 0;
BA_ "GenSigSendType" SG_ 1836 NMH_Ladegeraet_Transport_Mode 0;
BA_ "GenSigAutoGenSnd" SG_ 1836 NMH_Ladegeraet_Transport_Mode 1;
BA_ "GenSigAutoGenDsp" SG_ 1836 NMH_Ladegeraet_Transport_Mode 1;
BA_ "GenSigSwitchedByIgnition" SG_ 1836 NMH_Ladegeraet_Abschaltstufe_001 0;
BA_ "GenSigSendType" SG_ 1836 NMH_Ladegeraet_Abschaltstufe_001 0;
BA_ "GenSigAutoGenSnd" SG_ 1836 NMH_Ladegeraet_Abschaltstufe_001 1;
BA_ "GenSigAutoGenDsp" SG_ 1836 NMH_Ladegeraet_Abschaltstufe_001 1;
BA_ "GenSigSwitchedByIgnition" SG_ 1836 NMH_Ladegeraet_Eindraht_Fehler 0;
BA_ "GenSigSendType" SG_ 1836 NMH_Ladegeraet_Eindraht_Fehler 0;
BA_ "GenSigAutoGenSnd" SG_ 1836 NMH_Ladegeraet_Eindraht_Fehler 1;
BA_ "GenSigAutoGenDsp" SG_ 1836 NMH_Ladegeraet_Eindraht_Fehler 1;
BA_ "GenSigSwitchedByIgnition" SG_ 1825 NMH_MO_Start_1 0;
BA_ "GenSigSendType" SG_ 1825 NMH_MO_Start_1 0;
BA_ "GenSigAutoGenSnd" SG_ 1825 NMH_MO_Start_1 1;
BA_ "GenSigAutoGenDsp" SG_ 1825 NMH_MO_Start_1 1;
BA_ "GenSigSwitchedByIgnition" SG_ 1825 NMH_MO_Start_2 0;
BA_ "GenSigSendType" SG_ 1825 NMH_MO_Start_2 0;
BA_ "GenSigAutoGenSnd" SG_ 1825 NMH_MO_Start_2 1;
BA_ "GenSigAutoGenDsp" SG_ 1825 NMH_MO_Start_2 1;
BA_ "GenSigSwitchedByIgnition" SG_ 1825 NMH_MO_Normal_Mode_1 0;
BA_ "GenSigSendType" SG_ 1825 NMH_MO_Normal_Mode_1 0;
BA_ "GenSigAutoGenSnd" SG_ 1825 NMH_MO_Normal_Mode_1 1;
BA_ "GenSigAutoGenDsp" SG_ 1825 NMH_MO_Normal_Mode_1 1;
BA_ "GenSigSwitchedByIgnition" SG_ 1825 NMH_MO_Normal_Mode_2 0;
BA_ "GenSigSendType" SG_ 1825 NMH_MO_Normal_Mode_2 0;
BA_ "GenSigAutoGenSnd" SG_ 1825 NMH_MO_Normal_Mode_2 1;
BA_ "GenSigAutoGenDsp" SG_ 1825 NMH_MO_Normal_Mode_2 1;
BA_ "GenSigSwitchedByIgnition" SG_ 1825 NMH_MO_Car_WakeUp 0;
BA_ "GenSigSendType" SG_ 1825 NMH_MO_Car_WakeUp 0;
BA_ "GenSigAutoGenSnd" SG_ 1825 NMH_MO_Car_WakeUp 1;
BA_ "GenSigAutoGenDsp" SG_ 1825 NMH_MO_Car_WakeUp 1;
BA_ "GenSigSwitchedByIgnition" SG_ 1825 NMH_MO_Per_WakeUp 0;
BA_ "GenSigSendType" SG_ 1825 NMH_MO_Per_WakeUp 0;
BA_ "GenSigAutoGenSnd" SG_ 1825 NMH_MO_Per_WakeUp 1;
BA_ "GenSigAutoGenDsp" SG_ 1825 NMH_MO_Per_WakeUp 1;
BA_ "GenSigSwitchedByIgnition" SG_ 1825 NMH_MO_Fkt_WakeUp 0;
BA_ "GenSigSendType" SG_ 1825 NMH_MO_Fkt_WakeUp 0;
BA_ "GenSigAutoGenSnd" SG_ 1825 NMH_MO_Fkt_WakeUp 1;
BA_ "GenSigAutoGenDsp" SG_ 1825 NMH_MO_Fkt_WakeUp 1;
BA_ "GenSigSwitchedByIgnition" SG_ 1825 NMH_MO_NM_aktiv_Klemme_15 0;
BA_ "GenSigSendType" SG_ 1825 NMH_MO_NM_aktiv_Klemme_15 0;
BA_ "GenSigAutoGenSnd" SG_ 1825 NMH_MO_NM_aktiv_Klemme_15 1;
BA_ "GenSigAutoGenDsp" SG_ 1825 NMH_MO_NM_aktiv_Klemme_15 1;
BA_ "GenSigSwitchedByIgnition" SG_ 1825 NMH_MO_NM_aktiv_Diagnose 0;
BA_ "GenSigSendType" SG_ 1825 NMH_MO_NM_aktiv_Diagnose 0;
BA_ "GenSigAutoGenSnd" SG_ 1825 NMH_MO_NM_aktiv_Diagnose 1;
BA_ "GenSigAutoGenDsp" SG_ 1825 NMH_MO_NM_aktiv_Diagnose 1;
BA_ "GenSigSwitchedByIgnition" SG_ 1825 NMH_MO_NM_aktiv_Start 0;
BA_ "GenSigSendType" SG_ 1825 NMH_MO_NM_aktiv_Start 0;
BA_ "GenSigAutoGenSnd" SG_ 1825 NMH_MO_NM_aktiv_Start 1;
BA_ "GenSigAutoGenDsp" SG_ 1825 NMH_MO_NM_aktiv_Start 1;
BA_ "GenSigSwitchedByIgnition" SG_ 1825 NMH_MO_NL_aktiv_4 0;
BA_ "GenSigSendType" SG_ 1825 NMH_MO_NL_aktiv_4 0;
BA_ "GenSigAutoGenSnd" SG_ 1825 NMH_MO_NL_aktiv_4 1;
BA_ "GenSigAutoGenDsp" SG_ 1825 NMH_MO_NL_aktiv_4 1;
BA_ "GenSigSwitchedByIgnition" SG_ 1825 NMH_MO_NL_aktiv_5 0;
BA_ "GenSigSendType" SG_ 1825 NMH_MO_NL_aktiv_5 0;
BA_ "GenSigAutoGenSnd" SG_ 1825 NMH_MO_NL_aktiv_5 1;
BA_ "GenSigAutoGenDsp" SG_ 1825 NMH_MO_NL_aktiv_5 1;
BA_ "GenSigSwitchedByIgnition" SG_ 1825 NMH_MO_NL_aktiv_6 0;
BA_ "GenSigSendType" SG_ 1825 NMH_MO_NL_aktiv_6 0;
BA_ "GenSigAutoGenSnd" SG_ 1825 NMH_MO_NL_aktiv_6 1;
BA_ "GenSigAutoGenDsp" SG_ 1825 NMH_MO_NL_aktiv_6 1;
BA_ "GenSigSwitchedByIgnition" SG_ 1825 NMH_MO_NL_aktiv_7 0;
BA_ "GenSigSendType" SG_ 1825 NMH_MO_NL_aktiv_7 0;
BA_ "GenSigAutoGenSnd" SG_ 1825 NMH_MO_NL_aktiv_7 1;
BA_ "GenSigAutoGenDsp" SG_ 1825 NMH_MO_NL_aktiv_7 1;
BA_ "GenSigSwitchedByIgnition" SG_ 1825 NMH_MO_NL_aktiv_8 0;
BA_ "GenSigSendType" SG_ 1825 NMH_MO_NL_aktiv_8 0;
BA_ "GenSigAutoGenSnd" SG_ 1825 NMH_MO_NL_aktiv_8 1;
BA_ "GenSigAutoGenDsp" SG_ 1825 NMH_MO_NL_aktiv_8 1;
BA_ "GenSigSwitchedByIgnition" SG_ 1825 NMH_MO_NL_0 0;
BA_ "GenSigSendType" SG_ 1825 NMH_MO_NL_0 0;
BA_ "GenSigAutoGenSnd" SG_ 1825 NMH_MO_NL_0 1;
BA_ "GenSigAutoGenDsp" SG_ 1825 NMH_MO_NL_0 1;
BA_ "GenSigSwitchedByIgnition" SG_ 1825 NMH_MO_NL_1 0;
BA_ "GenSigSendType" SG_ 1825 NMH_MO_NL_1 0;
BA_ "GenSigAutoGenSnd" SG_ 1825 NMH_MO_NL_1 1;
BA_ "GenSigAutoGenDsp" SG_ 1825 NMH_MO_NL_1 1;
BA_ "GenSigSwitchedByIgnition" SG_ 1825 NMH_MO_NL_2 0;
BA_ "GenSigSendType" SG_ 1825 NMH_MO_NL_2 0;
BA_ "GenSigAutoGenSnd" SG_ 1825 NMH_MO_NL_2 1;
BA_ "GenSigAutoGenDsp" SG_ 1825 NMH_MO_NL_2 1;
BA_ "GenSigSwitchedByIgnition" SG_ 1825 NMH_MO_NL_3 0;
BA_ "GenSigSendType" SG_ 1825 NMH_MO_NL_3 0;
BA_ "GenSigAutoGenSnd" SG_ 1825 NMH_MO_NL_3 1;
BA_ "GenSigAutoGenDsp" SG_ 1825 NMH_MO_NL_3 1;
BA_ "GenSigSwitchedByIgnition" SG_ 1825 NMH_MO_NL_4 0;
BA_ "GenSigSendType" SG_ 1825 NMH_MO_NL_4 0;
BA_ "GenSigAutoGenSnd" SG_ 1825 NMH_MO_NL_4 1;
BA_ "GenSigAutoGenDsp" SG_ 1825 NMH_MO_NL_4 1;
BA_ "GenSigSwitchedByIgnition" SG_ 1825 NMH_MO_NL_5 0;
BA_ "GenSigSendType" SG_ 1825 NMH_MO_NL_5 0;
BA_ "GenSigAutoGenSnd" SG_ 1825 NMH_MO_NL_5 1;
BA_ "GenSigAutoGenDsp" SG_ 1825 NMH_MO_NL_5 1;
BA_ "GenSigSwitchedByIgnition" SG_ 1825 NMH_MO_NL_6 0;
BA_ "GenSigSendType" SG_ 1825 NMH_MO_NL_6 0;
BA_ "GenSigAutoGenSnd" SG_ 1825 NMH_MO_NL_6 1;
BA_ "GenSigAutoGenDsp" SG_ 1825 NMH_MO_NL_6 1;
BA_ "GenSigSwitchedByIgnition" SG_ 1825 NMH_MO_NL_7 0;
BA_ "GenSigSendType" SG_ 1825 NMH_MO_NL_7 0;
BA_ "GenSigAutoGenSnd" SG_ 1825 NMH_MO_NL_7 1;
BA_ "GenSigAutoGenDsp" SG_ 1825 NMH_MO_NL_7 1;
BA_ "GenSigSwitchedByIgnition" SG_ 1825 NMH_MO_TimeOut_Fehler 0;
BA_ "GenSigSendType" SG_ 1825 NMH_MO_TimeOut_Fehler 0;
BA_ "GenSigAutoGenSnd" SG_ 1825 NMH_MO_TimeOut_Fehler 1;
BA_ "GenSigAutoGenDsp" SG_ 1825 NMH_MO_TimeOut_Fehler 1;
BA_ "GenSigSwitchedByIgnition" SG_ 1825 NMH_MO_CAN_Diag_deaktiv 0;
BA_ "GenSigSendType" SG_ 1825 NMH_MO_CAN_Diag_deaktiv 0;
BA_ "GenSigAutoGenSnd" SG_ 1825 NMH_MO_CAN_Diag_deaktiv 1;
BA_ "GenSigAutoGenDsp" SG_ 1825 NMH_MO_CAN_Diag_deaktiv 1;
BA_ "GenSigSwitchedByIgnition" SG_ 1825 NMH_MO_KompSchutz 0;
BA_ "GenSigSendType" SG_ 1825 NMH_MO_KompSchutz 0;
BA_ "GenSigAutoGenSnd" SG_ 1825 NMH_MO_KompSchutz 1;
BA_ "GenSigAutoGenDsp" SG_ 1825 NMH_MO_KompSchutz 1;
BA_ "GenSigSwitchedByIgnition" SG_ 1825 NMH_MO_Mute_Mode 0;
BA_ "GenSigSendType" SG_ 1825 NMH_MO_Mute_Mode 0;
BA_ "GenSigAutoGenSnd" SG_ 1825 NMH_MO_Mute_Mode 1;
BA_ "GenSigAutoGenDsp" SG_ 1825 NMH_MO_Mute_Mode 1;
BA_ "GenSigSwitchedByIgnition" SG_ 1825 NMH_MO_Transport_Mode 0;
BA_ "GenSigSendType" SG_ 1825 NMH_MO_Transport_Mode 0;
BA_ "GenSigAutoGenSnd" SG_ 1825 NMH_MO_Transport_Mode 1;
BA_ "GenSigAutoGenDsp" SG_ 1825 NMH_MO_Transport_Mode 1;
BA_ "GenSigSwitchedByIgnition" SG_ 1825 NMH_MO_Abschaltstufe_aktiv 0;
BA_ "GenSigSendType" SG_ 1825 NMH_MO_Abschaltstufe_aktiv 0;
BA_ "GenSigAutoGenSnd" SG_ 1825 NMH_MO_Abschaltstufe_aktiv 1;
BA_ "GenSigAutoGenDsp" SG_ 1825 NMH_MO_Abschaltstufe_aktiv 1;
BA_ "GenSigSwitchedByIgnition" SG_ 1825 NMH_MO_Eindraht_Fehler 0;
BA_ "GenSigSendType" SG_ 1825 NMH_MO_Eindraht_Fehler 0;
BA_ "GenSigAutoGenSnd" SG_ 1825 NMH_MO_Eindraht_Fehler 1;
BA_ "GenSigAutoGenDsp" SG_ 1825 NMH_MO_Eindraht_Fehler 1;
BA_ "GenSigSwitchedByIgnition" SG_ 1523 OBD_TG_F_Status_1 0;
BA_ "GenSigSendType" SG_ 1523 OBD_TG_F_Status_1 0;
BA_ "GenSigEnvVarType" SG_ 1523 OBD_TG_F_Status_1 0;
BA_ "GenSigAutoGenSnd" SG_ 1523 OBD_TG_F_Status_1 1;
BA_ "GenSigAutoGenDsp" SG_ 1523 OBD_TG_F_Status_1 1;
BA_ "GenSigSwitchedByIgnition" SG_ 1523 OBD_TG_F_Status_2 0;
BA_ "GenSigSendType" SG_ 1523 OBD_TG_F_Status_2 0;
BA_ "GenSigEnvVarType" SG_ 1523 OBD_TG_F_Status_2 0;
BA_ "GenSigAutoGenSnd" SG_ 1523 OBD_TG_F_Status_2 1;
BA_ "GenSigAutoGenDsp" SG_ 1523 OBD_TG_F_Status_2 1;
BA_ "GenSigSwitchedByIgnition" SG_ 1523 OBD_TG_F_Status_3 0;
BA_ "GenSigSendType" SG_ 1523 OBD_TG_F_Status_3 0;
BA_ "GenSigEnvVarType" SG_ 1523 OBD_TG_F_Status_3 0;
BA_ "GenSigAutoGenSnd" SG_ 1523 OBD_TG_F_Status_3 1;
BA_ "GenSigAutoGenDsp" SG_ 1523 OBD_TG_F_Status_3 1;
BA_ "GenSigSwitchedByIgnition" SG_ 1523 OBD_TG_F_Status_4 0;
BA_ "GenSigSendType" SG_ 1523 OBD_TG_F_Status_4 0;
BA_ "GenSigEnvVarType" SG_ 1523 OBD_TG_F_Status_4 0;
BA_ "GenSigAutoGenSnd" SG_ 1523 OBD_TG_F_Status_4 1;
BA_ "GenSigAutoGenDsp" SG_ 1523 OBD_TG_F_Status_4 1;
BA_ "GenSigSwitchedByIgnition" SG_ 1523 OBD_TG_Sens_Rohwert_1 0;
BA_ "GenSigSendType" SG_ 1523 OBD_TG_Sens_Rohwert_1 0;
BA_ "GenSigEnvVarType" SG_ 1523 OBD_TG_Sens_Rohwert_1 1;
BA_ "GenSigAutoGenSnd" SG_ 1523 OBD_TG_Sens_Rohwert_1 1;
BA_ "GenSigAutoGenDsp" SG_ 1523 OBD_TG_Sens_Rohwert_1 1;
BA_ "GenSigSwitchedByIgnition" SG_ 1523 OBD_TG_Sens_Rohwert_2 0;
BA_ "GenSigSendType" SG_ 1523 OBD_TG_Sens_Rohwert_2 0;
BA_ "GenSigEnvVarType" SG_ 1523 OBD_TG_Sens_Rohwert_2 1;
BA_ "GenSigAutoGenSnd" SG_ 1523 OBD_TG_Sens_Rohwert_2 1;
BA_ "GenSigAutoGenDsp" SG_ 1523 OBD_TG_Sens_Rohwert_2 1;
BA_ "GenSigSwitchedByIgnition" SG_ 1523 OBD_TG_Sens_Rohwert_3 0;
BA_ "GenSigSendType" SG_ 1523 OBD_TG_Sens_Rohwert_3 0;
BA_ "GenSigEnvVarType" SG_ 1523 OBD_TG_Sens_Rohwert_3 1;
BA_ "GenSigAutoGenSnd" SG_ 1523 OBD_TG_Sens_Rohwert_3 1;
BA_ "GenSigAutoGenDsp" SG_ 1523 OBD_TG_Sens_Rohwert_3 1;
BA_ "GenSigSwitchedByIgnition" SG_ 1523 OBD_TG_Sens_Rohwert_4 0;
BA_ "GenSigSendType" SG_ 1523 OBD_TG_Sens_Rohwert_4 0;
BA_ "GenSigEnvVarType" SG_ 1523 OBD_TG_Sens_Rohwert_4 1;
BA_ "GenSigAutoGenSnd" SG_ 1523 OBD_TG_Sens_Rohwert_4 1;
BA_ "GenSigAutoGenDsp" SG_ 1523 OBD_TG_Sens_Rohwert_4 1;
BA_ "Fehlerwert" SG_ 1175 PH_Abschaltursache 7;
BA_ "GenSigSendType" SG_ 1175 PH_Abschaltursache 3;
BA_ "GenSigAutoGenSnd" SG_ 1175 PH_Abschaltursache 1;
BA_ "GenSigAutoGenDsp" SG_ 1175 PH_Abschaltursache 1;
BA_ "GenSigSendType" SG_ 1175 PH_Opt_Anzeige_V_ein 3;
BA_ "GenSigAutoGenSnd" SG_ 1175 PH_Opt_Anzeige_V_ein 1;
BA_ "GenSigAutoGenDsp" SG_ 1175 PH_Opt_Anzeige_V_ein 1;
BA_ "GenSigSendType" SG_ 1175 PH_Opt_Anzeige_H_ein 3;
BA_ "GenSigAutoGenSnd" SG_ 1175 PH_Opt_Anzeige_H_ein 1;
BA_ "GenSigAutoGenDsp" SG_ 1175 PH_Opt_Anzeige_H_ein 1;
BA_ "GenSigSendType" SG_ 1175 PH_Opt_Anz_V_Hindernis 3;
BA_ "GenSigAutoGenSnd" SG_ 1175 PH_Opt_Anz_V_Hindernis 1;
BA_ "GenSigAutoGenDsp" SG_ 1175 PH_Opt_Anz_V_Hindernis 1;
BA_ "GenSigSendType" SG_ 1175 PH_Opt_Anz_H_Hindernis 3;
BA_ "GenSigAutoGenSnd" SG_ 1175 PH_Opt_Anz_H_Hindernis 1;
BA_ "GenSigAutoGenDsp" SG_ 1175 PH_Opt_Anz_H_Hindernis 1;
BA_ "GenSigSendType" SG_ 1175 PH_Tongeber_V_aktiv 3;
BA_ "GenSigAutoGenSnd" SG_ 1175 PH_Tongeber_V_aktiv 1;
BA_ "GenSigAutoGenDsp" SG_ 1175 PH_Tongeber_V_aktiv 1;
BA_ "GenSigSendType" SG_ 1175 PH_Tongeber_H_aktiv 3;
BA_ "GenSigAutoGenSnd" SG_ 1175 PH_Tongeber_H_aktiv 1;
BA_ "GenSigAutoGenDsp" SG_ 1175 PH_Tongeber_H_aktiv 1;
BA_ "GenSigSendType" SG_ 1175 PH_Tongeber_mute 3;
BA_ "GenSigAutoGenSnd" SG_ 1175 PH_Tongeber_mute 1;
BA_ "GenSigAutoGenDsp" SG_ 1175 PH_Tongeber_mute 1;
BA_ "GenSigSendType" SG_ 1175 PH_Anf_Audioabsenkung 3;
BA_ "GenSigAutoGenSnd" SG_ 1175 PH_Anf_Audioabsenkung 1;
BA_ "GenSigAutoGenDsp" SG_ 1175 PH_Anf_Audioabsenkung 1;
BA_ "GenSigSendType" SG_ 1175 PH_Anf_Verdeck 0;
BA_ "GenSigSendType" SG_ 1175 PH_Frequenz_hinten 0;
BA_ "GenSigAutoGenSnd" SG_ 1175 PH_Frequenz_hinten 1;
BA_ "GenSigAutoGenDsp" SG_ 1175 PH_Frequenz_hinten 1;
BA_ "GenSigSendType" SG_ 1175 PH_Lautstaerke_hinten 0;
BA_ "GenSigAutoGenSnd" SG_ 1175 PH_Lautstaerke_hinten 1;
BA_ "GenSigAutoGenDsp" SG_ 1175 PH_Lautstaerke_hinten 1;
BA_ "GenSigSendType" SG_ 1175 PH_Frequenz_vorn 0;
BA_ "GenSigAutoGenSnd" SG_ 1175 PH_Frequenz_vorn 1;
BA_ "GenSigAutoGenDsp" SG_ 1175 PH_Frequenz_vorn 1;
BA_ "GenSigSendType" SG_ 1175 PH_Lautstaerke_vorn 0;
BA_ "GenSigAutoGenSnd" SG_ 1175 PH_Lautstaerke_vorn 1;
BA_ "GenSigAutoGenDsp" SG_ 1175 PH_Lautstaerke_vorn 1;
BA_ "GenSigSendType" SG_ 1175 PH_Trigger_Bildaufschaltung 3;
BA_ "GenSigAutoGenSnd" SG_ 1175 PH_Trigger_Bildaufschaltung 1;
BA_ "GenSigAutoGenDsp" SG_ 1175 PH_Trigger_Bildaufschaltung 1;
BA_ "GenSigSendType" SG_ 1175 PH_StartStopp_Info 3;
BA_ "GenSigAutoGenSnd" SG_ 1175 PH_StartStopp_Info 1;
BA_ "GenSigAutoGenDsp" SG_ 1175 PH_StartStopp_Info 1;
BA_ "GenSigSendType" SG_ 1175 PH_Aufbauten_erk 3;
BA_ "GenSigAutoGenSnd" SG_ 1175 PH_Aufbauten_erk 1;
BA_ "GenSigAutoGenDsp" SG_ 1175 PH_Aufbauten_erk 1;
BA_ "GenSigSendType" SG_ 1175 PH_BerErk_vorn 3;
BA_ "GenSigAutoGenSnd" SG_ 1175 PH_BerErk_vorn 1;
BA_ "GenSigAutoGenDsp" SG_ 1175 PH_BerErk_vorn 1;
BA_ "GenSigSendType" SG_ 1175 PH_BerErk_hinten 3;
BA_ "GenSigAutoGenSnd" SG_ 1175 PH_BerErk_hinten 1;
BA_ "GenSigAutoGenDsp" SG_ 1175 PH_BerErk_hinten 1;
BA_ "GenSigSendType" SG_ 1175 PH_defekt 3;
BA_ "GenSigAutoGenSnd" SG_ 1175 PH_defekt 1;
BA_ "GenSigAutoGenDsp" SG_ 1175 PH_defekt 1;
BA_ "GenSigSendType" SG_ 1175 PH_gestoert 3;
BA_ "GenSigAutoGenSnd" SG_ 1175 PH_gestoert 1;
BA_ "GenSigAutoGenDsp" SG_ 1175 PH_gestoert 1;
BA_ "GenSigSendType" SG_ 1175 PH_Systemzustand 3;
BA_ "GenSigAutoGenSnd" SG_ 1175 PH_Systemzustand 1;
BA_ "GenSigAutoGenDsp" SG_ 1175 PH_Systemzustand 1;
BA_ "GenSigSendType" SG_ 1175 PH_Display_Kundenwunsch 3;
BA_ "GenSigAutoGenSnd" SG_ 1175 PH_Display_Kundenwunsch 1;
BA_ "GenSigAutoGenDsp" SG_ 1175 PH_Display_Kundenwunsch 1;
BA_ "Fehlerwert" SG_ 1175 PH_KD_Fehler 1;
BA_ "GenSigSendType" SG_ 1175 PH_KD_Fehler 3;
BA_ "GenSigAutoGenSnd" SG_ 1175 PH_KD_Fehler 1;
BA_ "GenSigAutoGenDsp" SG_ 1175 PH_KD_Fehler 1;
BA_ "GenSigSwitchedByIgnition" SG_ 2033 Req_Airbag_Deployment 0;
BA_ "GenSigSendType" SG_ 2033 Req_Airbag_Deployment 3;
BA_ "GenSigAutoGenSnd" SG_ 2033 Req_Airbag_Deployment 1;
BA_ "GenSigAutoGenDsp" SG_ 2033 Req_Airbag_Deployment 1;
BA_ "GenSigSwitchedByIgnition" SG_ 2041 Resp_Airbag_Deployment 0;
BA_ "GenSigSendType" SG_ 2041 Resp_Airbag_Deployment 3;
BA_ "GenSigAutoGenSnd" SG_ 2041 Resp_Airbag_Deployment 1;
BA_ "GenSigAutoGenDsp" SG_ 2041 Resp_Airbag_Deployment 1;
BA_REL_ "GenSigTimeoutTime" BU_SG_REL_ Motor_Diesel SG_ 1306 TOG_Zaehler 5000;
BA_REL_ "GenSigTimeoutTime" BU_SG_REL_ Motor_Hybrid SG_ 1306 TOG_Zaehler 5000;
BA_REL_ "GenSigTimeoutTime" BU_SG_REL_ Motor_Otto SG_ 1306 TOG_Zaehler 5000;
BA_REL_ "GenSigTimeoutTime" BU_SG_REL_ Motor_Diesel SG_ 1306 TOG_Fuellstand_1 5000;
BA_REL_ "GenSigTimeoutTime" BU_SG_REL_ Motor_Hybrid SG_ 1306 TOG_Fuellstand_1 5000;
BA_REL_ "GenSigTimeoutTime" BU_SG_REL_ Motor_Otto SG_ 1306 TOG_Fuellstand_1 5000;
BA_REL_ "GenSigTimeoutTime" BU_SG_REL_ Motor_Diesel SG_ 1306 TOG_Fuellstand_2 5000;
BA_REL_ "GenSigTimeoutTime" BU_SG_REL_ Motor_Hybrid SG_ 1306 TOG_Fuellstand_2 5000;
BA_REL_ "GenSigTimeoutTime" BU_SG_REL_ Motor_Otto SG_ 1306 TOG_Fuellstand_2 5000;
BA_REL_ "GenSigTimeoutTime" BU_SG_REL_ Motor_Diesel SG_ 1306 TOG_Fuellstand_3 5000;
BA_REL_ "GenSigTimeoutTime" BU_SG_REL_ Motor_Hybrid SG_ 1306 TOG_Fuellstand_3 5000;
BA_REL_ "GenSigTimeoutTime" BU_SG_REL_ Motor_Otto SG_ 1306 TOG_Fuellstand_3 5000;
BA_REL_ "GenSigTimeoutTime" BU_SG_REL_ Motor_Diesel SG_ 1306 TOG_Fuellstand_4 5000;
BA_REL_ "GenSigTimeoutTime" BU_SG_REL_ Motor_Hybrid SG_ 1306 TOG_Fuellstand_4 5000;
BA_REL_ "GenSigTimeoutTime" BU_SG_REL_ Motor_Otto SG_ 1306 TOG_Fuellstand_4 5000;
BA_REL_ "GenSigTimeoutTime" BU_SG_REL_ Motor_Diesel SG_ 1306 TOG_Oeltempzeit 5000;
BA_REL_ "GenSigTimeoutTime" BU_SG_REL_ Motor_Hybrid SG_ 1306 TOG_Oeltempzeit 5000;
BA_REL_ "GenSigTimeoutTime" BU_SG_REL_ Motor_Otto SG_ 1306 TOG_Oeltempzeit 5000;
BA_REL_ "GenSigTimeoutTime" BU_SG_REL_ Motor_Diesel SG_ 1306 TOG_Sensorfehler 5000;
BA_REL_ "GenSigTimeoutTime" BU_SG_REL_ Motor_Hybrid SG_ 1306 TOG_Sensorfehler 5000;
BA_REL_ "GenSigTimeoutTime" BU_SG_REL_ Motor_Otto SG_ 1306 TOG_Sensorfehler 5000;
BA_REL_ "GenSigTimeoutTime" BU_SG_REL_ Motor_Diesel SG_ 1306 TOG_Oelwarn_hoch 5000;
BA_REL_ "GenSigTimeoutTime" BU_SG_REL_ Motor_Hybrid SG_ 1306 TOG_Oelwarn_hoch 5000;
BA_REL_ "GenSigTimeoutTime" BU_SG_REL_ Motor_Otto SG_ 1306 TOG_Oelwarn_hoch 5000;
BA_REL_ "GenSigTimeoutTime" BU_SG_REL_ Getriebe_DQ SG_ 1096 WH1_StaShiftlock 500;
BA_REL_ "GenSigTimeoutTime" BU_SG_REL_ Getriebe_DQ_Hyb SG_ 1096 WH1_StaShiftlock 500;
BA_REL_ "GenSigTimeoutTime" BU_SG_REL_ Getriebe_DQ SG_ 1096 WH1_Init 500;
BA_REL_ "GenSigTimeoutTime" BU_SG_REL_ Getriebe_DQ_Hyb SG_ 1096 WH1_Init 500;
BA_REL_ "GenSigTimeoutTime" BU_SG_REL_ Getriebe_DQ SG_ 1096 WH1_Position 500;
BA_REL_ "GenSigTimeoutTime" BU_SG_REL_ Getriebe_DQ_Hyb SG_ 1096 WH1_Position 500;
BA_REL_ "GenSigTimeoutTime" BU_SG_REL_ Getriebe_DQ SG_ 1096 WH1_Status 500;
BA_REL_ "GenSigTimeoutTime" BU_SG_REL_ Getriebe_DQ_Hyb SG_ 1096 WH1_Status 500;
BA_REL_ "GenSigTimeoutTime" BU_SG_REL_ Getriebe_DQ SG_ 1096 WH1_Testergebnis 500;
BA_REL_ "GenSigTimeoutTime" BU_SG_REL_ Getriebe_DQ_Hyb SG_ 1096 WH1_Testergebnis 500;
BA_REL_ "GenSigTimeoutTime" BU_SG_REL_ Getriebe_DQ SG_ 1096 WH1_Zaehler 500;
BA_REL_ "GenSigTimeoutTime" BU_SG_REL_ Getriebe_DQ_Hyb SG_ 1096 WH1_Zaehler 500;
BA_REL_ "GenSigTimeoutTime" BU_SG_REL_ Getriebe_DQ SG_ 1096 WH1_Test_Flag 500;
BA_REL_ "GenSigTimeoutTime" BU_SG_REL_ Getriebe_DQ_Hyb SG_ 1096 WH1_Test_Flag 500;
BA_REL_ "GenSigTimeoutTime" BU_SG_REL_ Getriebe_DQ SG_ 1096 WH1_Position_inv 500;
BA_REL_ "GenSigTimeoutTime" BU_SG_REL_ Getriebe_DQ_Hyb SG_ 1096 WH1_Position_inv 500;
BA_REL_ "GenSigTimeoutTime" BU_SG_REL_ Getriebe_Sele SG_ 1102 WH2_Checksumme 500;
BA_REL_ "GenSigTimeoutTime" BU_SG_REL_ Getriebe_Sele SG_ 1102 WH2_Zaehler 500;
BA_REL_ "GenSigTimeoutTime" BU_SG_REL_ Getriebe_Sele SG_ 1102 WH2_Init 500;
BA_REL_ "GenSigTimeoutTime" BU_SG_REL_ Getriebe_Sele SG_ 1102 WH2_Test_Flag 500;
BA_REL_ "GenSigTimeoutTime" BU_SG_REL_ Getriebe_Sele SG_ 1102 WH2_Sport 500;
BA_REL_ "GenSigTimeoutTime" BU_SG_REL_ Getriebe_Sele SG_ 1102 WH2_Winter 500;
BA_REL_ "GenSigTimeoutTime" BU_SG_REL_ Getriebe_Sele SG_ 1102 WH2_Position 500;
BA_REL_ "GenSigTimeoutTime" BU_SG_REL_ Getriebe_Sele SG_ 1102 WH2_Ruhestromfehler 500;
BA_REL_ "GenSigTimeoutTime" BU_SG_REL_ Getriebe_Sele SG_ 1102 WH2_Sensorarray_Einfachfehler 500;
BA_REL_ "GenSigTimeoutTime" BU_SG_REL_ Getriebe_Sele SG_ 1102 WH2_Sensorarray_Mehrfachfehler 500;
BA_REL_ "GenSigTimeoutTime" BU_SG_REL_ Getriebe_Sele SG_ 1102 WH2_Fehler_Sporttaster 500;
BA_REL_ "GenSigTimeoutTime" BU_SG_REL_ Getriebe_Sele SG_ 1102 WH2_Fehler_Fahrstufenanzeige 500;
BA_REL_ "GenSigTimeoutTime" BU_SG_REL_ Getriebe_Sele SG_ 1102 WH2_Fehler_Spannungsversorgung 500;
BA_REL_ "GenSigTimeoutTime" BU_SG_REL_ Getriebe_Sele SG_ 1102 WH2_Timeout_Kombi_2 500;
BA_REL_ "GenSigTimeoutTime" BU_SG_REL_ Getriebe_Sele SG_ 1102 WH2_Timeout_Getriebe_5 500;
BA_REL_ "GenSigTimeoutTime" BU_SG_REL_ Getriebe_Sele SG_ 1102 WH2_Timeout_Gate_Komf_1 500;
BA_REL_ "GenSigTimeoutTime" BU_SG_REL_ Getriebe_Sele SG_ 1102 WH2_Testergebnis 500;
BA_REL_ "GenSigTimeoutTime" BU_SG_REL_ Motor_Hybrid SG_ 1394 ZA1_Klemme_15 1000;
BA_REL_ "GenSigTimeoutTime" BU_SG_REL_ Motor_Otto SG_ 1394 ZA1_Klemme_15 1000;
BA_REL_ "GenSigTimeoutTime" BU_SG_REL_ PDC_PLA SG_ 1394 ZA1_Klemme_15 1000;
BA_REL_ "GenSigTimeoutTime" BU_SG_REL_ Motor_Diesel SG_ 1394 ZA1_Klemme_X 1000;
BA_REL_ "GenSigTimeoutTime" BU_SG_REL_ PDC_PLA SG_ 1394 ZA1_Klemme_X 1000;
BA_REL_ "GenSigTimeoutTime" BU_SG_REL_ Motor_Diesel SG_ 1394 ZA1_Klemme_50 1000;
BA_REL_ "GenSigTimeoutTime" BU_SG_REL_ Motor_Hybrid SG_ 1394 ZA1_Klemme_50 1000;
BA_REL_ "GenSigTimeoutTime" BU_SG_REL_ Motor_Otto SG_ 1394 ZA1_Klemme_50 1000;
BA_REL_ "GenSigTimeoutTime" BU_SG_REL_ Bremse_MK60EC SG_ 919 ZK5_Checksumme 1000;
BA_REL_ "GenSigTimeoutTime" BU_SG_REL_ Bremse_MK60EC SG_ 919 ZK5_Zaehler 1000;
BA_REL_ "GenSigTimeoutTime" BU_SG_REL_ Bremse_MK60EC SG_ 919 ZK5_Endlage_ausgefahren 1000;
BA_REL_ "GenSigTimeoutTime" BU_SG_REL_ Bremse_MK60EC SG_ 919 ZK5_Endlage_eingefahren 1000;
BA_REL_ "GenSigTimeoutTime" BU_SG_REL_ Bremse_MK60EC SG_ 919 ZK5_Status_Spoiler 1000;
BA_REL_ "GenSigTimeoutTime" BU_SG_REL_ Bremse_MK60EC SG_ 919 ZK5_VD_Endlage_geschl 1000;
BA_REL_ "GenSigTimeoutTime" BU_SG_REL_ PDC_PLA SG_ 919 ZK5_VD_Endlage_geschl 1000;
BA_REL_ "GenSigTimeoutTime" BU_SG_REL_ Bremse_MK60EC SG_ 919 ZK5_VD_Endlage_abgelegt 1000;
BA_REL_ "GenSigTimeoutTime" BU_SG_REL_ PDC_PLA SG_ 919 ZK5_VD_Endlage_abgelegt 1000;
BA_REL_ "GenSigTimeoutTime" BU_SG_REL_ Bremse_MK60EC SG_ 919 ZK5_VD_Verbau 1000;
BA_REL_ "GenSigTimeoutTime" BU_SG_REL_ PDC_PLA SG_ 919 ZK5_VD_Verbau 1000;
BA_REL_ "GenSigTimeoutTime" BU_SG_REL_ Motor_Otto SG_ 1523 OBD_TG_F_Status_1 5000;
BA_REL_ "GenSigTimeoutTime" BU_SG_REL_ Motor_Otto SG_ 1523 OBD_TG_F_Status_2 5000;
BA_REL_ "GenSigTimeoutTime" BU_SG_REL_ Motor_Otto SG_ 1523 OBD_TG_F_Status_3 5000;
BA_REL_ "GenSigTimeoutTime" BU_SG_REL_ Motor_Otto SG_ 1523 OBD_TG_F_Status_4 5000;
BA_REL_ "GenSigTimeoutTime" BU_SG_REL_ Motor_Otto SG_ 1523 OBD_TG_Sens_Rohwert_1 5000;
BA_REL_ "GenSigTimeoutTime" BU_SG_REL_ Motor_Otto SG_ 1523 OBD_TG_Sens_Rohwert_2 5000;
BA_REL_ "GenSigTimeoutTime" BU_SG_REL_ Motor_Otto SG_ 1523 OBD_TG_Sens_Rohwert_3 5000;
BA_REL_ "GenSigTimeoutTime" BU_SG_REL_ Motor_Otto SG_ 1523 OBD_TG_Sens_Rohwert_4 5000;
BA_REL_ "GenSigTimeoutTime" BU_SG_REL_ Motor_Diesel SG_ 1175 PH_StartStopp_Info 1000;
BA_REL_ "GenSigTimeoutTime" BU_SG_REL_ Motor_Diesel SG_ 1175 PH_StartStopp_Info 1000;
BA_REL_ "GenSigTimeoutTime" BU_SG_REL_ Motor_Otto SG_ 1175 PH_StartStopp_Info 1000;
BA_REL_ "GenSigTimeoutTime" BU_SG_REL_ Gateway_PQ35 SG_ 1175 PH_KD_Fehler 1000;
VAL_ 1306 TOG_Fuellstand_1 0 "kein_Wert" 1 "Init" 2047 "unguelt_Wert_oder_Bereichsueberl" ;
VAL_ 1306 TOG_Fuellstand_2 0 "kein_Wert" 1 "Init" 2047 "unguelt_Wert_oder_Bereichsueberl" ;
VAL_ 1306 TOG_Fuellstand_3 0 "kein_Wert" 1 "Init" 2047 "unguelt_Wert_oder_Bereichsueberl" ;
VAL_ 1306 TOG_Fuellstand_4 0 "kein_Wert" 1 "Init" 2047 "unguelt_Wert_oder_Bereichsueberl" ;
VAL_ 1306 TOG_Oeltempzeit 0 "kein_Wert" 1 "Init" 1023 "Bereichsueberl" ;
VAL_ 1306 TOG_Sensorfehler 0 "Sensor_iO" 1 "Fehler" ;
VAL_ 1306 TOG_Oelwarn_hoch 0 "Schwelle_nicht_ueberschritten" 1 "Schwelle_ueberschritten" ;
VAL_ 1306 TOG_OelwarnUeber 0 "Schwelle_nicht_ueberschritten" 1 "Schwelle_ueberschritten" ;
VAL_ 1306 TOG_OelmaxUeber 0 "Schwelle_nicht_ueberschritten" 1 "Schwelle_ueberschritten" ;
VAL_ 1306 TOG_Oelmax_hoch 0 "Schwelle_nicht_ueberschritten" 1 "Schwelle_ueberschritten" ;
VAL_ 1096 WH1_StaShiftlock 0 "Initwert" 2 "Shiftlock_ist_deaktiviert" 3 "Shiftlock_ist_aktiviert" 6 "nicht_verbaut" 7 "Shiftlock_ist_fehlerhaft" ;
VAL_ 1096 WH1_Init 0 "keine_Initphase" 1 "Initphase" ;
VAL_ 1096 WH1_Position 1 "Position_1" 2 "Position_2" 3 "Position_3" 4 "Position_4" 5 "Position_D" 6 "Position_N" 7 "Position_R" 8 "Position_P_Stop" 9 "Position_N_ohne_Spotausl" 10 "Position_Tipp_plus" 11 "Position_Tipp_minus" 12 "Position_S_Sport" 13 "Position_L" 14 "Tipp_Gasse" 15 "Fehler" ;
VAL_ 1096 WH1_Status 0 "fehlerfrei" 1 "sonstiger_Fehler" 2 "Rueckfahrlicht_Unterbrechung_KS_nach_Masse" 4 "Rueckfahrlicht_KS_nach_Plus" 64 "Betrieb_auf_Redundanzbasis" 128 "Fahrerwunsch_nicht_interpretierbar" ;
VAL_ 1096 WH1_Test_Flag 0 "Testergebnis_ungueltig" 1 "Testergebnis_gueltig" ;
VAL_ 1096 WH1_Taster_betaetigt 0 "Taster_unbetaetigt" 1 "Taster_betaetigt" ;
VAL_ 1102 WH2_Init 0 "keine_Initphase" 1 "Initphase" ;
VAL_ 1102 WH2_Test_Flag 0 "Testergebnis_ungueltig" 1 "Testergebnis_gueltig" ;
VAL_ 1102 WH2_Sport 0 "nicht_betaetigt" 1 "Sporttaster_betaetigt" ;
VAL_ 1102 WH2_Winter 0 "nicht_betaetigt" 1 "Wintertaster_betaetigt" ;
VAL_ 1102 WH2_Position 0 "ungueltig" 1 "Ruhelage_U" 2 "Tip_plus" 3 "Tip_minus" 4 "Tip_D" 5 "Zwischenpos_V" 6 "Ruhelage_X" 7 "Tip_R" ;
VAL_ 1102 WH2_Ruhestromfehler 0 "kein_Ruhestromfehler" 1 "Ruhestromfehler" ;
VAL_ 1102 WH2_Sensorarray_Einfachfehler 0 "kein_Sensorik_Einzelfehler" 1 "Sensorik_Einzelfehler" ;
VAL_ 1102 WH2_Sensorarray_Mehrfachfehler 0 "kein_Sensorik_Mehrfachfehler" 1 "Sensorik_Mehrfachfehler" ;
VAL_ 1102 WH2_Fehler_Sporttaster 0 "Sporttaster_nicht_unterbr" 1 "Sporttaster_unterbr" ;
VAL_ 1102 WH2_Fehler_Fahrstufenanzeige 0 "keine_defekte_Anzeige" 1 "Anzeige_Waehlhebel_defekt" ;
VAL_ 1102 WH2_Fehler_Spannungsversorgung 0 "kein_UnterUebersp_Fehler" 1 "UnterUebersp_Fehler" ;
VAL_ 1102 WH2_Timeout_Kombi_2 0 "kein_Timeout_Kombi2" 1 "Timeout_Kombi2" ;
VAL_ 1102 WH2_Timeout_Getriebe_5 0 "kein_Timeout_Getriebe5" 1 "Timeout_Getriebe5" ;
VAL_ 1102 WH2_Timeout_Gate_Komf_1 0 "kein_Timeout_GateKomf1" 1 "Timeout_GateKomf1" ;
VAL_ 919 ZK5_Endlage_ausgefahren 0 "Endlage_nicht_erreicht" 1 "Endlage_erreicht" ;
VAL_ 919 ZK5_Endlage_eingefahren 0 "Endlage_nicht_erreicht" 1 "Endlage_erreicht" ;
VAL_ 919 ZV_SafeFunktion_aktiv 0 "inaktiv" 1 "aktiv" ;
VAL_ 919 ZK5_VD_Endlage_geschl 0 "Endlage_nicht_erreicht" 1 "Endlage_erreicht" ;
VAL_ 919 ZK5_VD_Endlage_abgelegt 0 "Endlage_nicht_erreicht" 1 "Endlage_erreicht" ;
VAL_ 919 ZK5_VD_Verbau 0 "autom_Verdeck" 1 "man_Verdeck" ;
VAL_ 1827 NMH_ABS_Start_1 1 "START_v_SLEEP" ;
VAL_ 1827 NMH_ABS_Start_2 1 "START_v_PREP_TO_SLEEP" ;
VAL_ 1827 NMH_ABS_Normal_Mode_1 1 "NORMAL_MODE_v_START" ;
VAL_ 1827 NMH_ABS_Normal_Mode_2 1 "NORMAL_MODE_v_READY_TO_SLEEP" ;
VAL_ 1827 NMH_ABS_Car_WakeUp 1 "Car_WakeUp" ;
VAL_ 1827 NMH_ABS_Per_WakeUp 0 "Funktionswakeup" 1 "CAN" 2 "P_Wakeup_Ursache_unbekannt" 3 "KL_15_HW" ;
VAL_ 1827 NMH_ABS_Fkt_WakeUp 0 "Peripheriewakeup" ;
VAL_ 1827 NMH_ABS_NM_aktiv_Klemme_15 1 "Klemme_15_ein" ;
VAL_ 1827 NMH_ABS_NM_aktiv_Diagnose 1 "Diagnose_bei_Kl_15_aus" ;
VAL_ 1827 NMH_ABS_NM_aktiv_Start 1 "Mindestaktivzeit_START" ;
VAL_ 1827 NMH_ABS_NL_aktiv_4 1 "kein_FzgStillstand_erkannt" ;
VAL_ 1827 NMH_ABS_NL_aktiv_5 1 "Nachlaufursache_5" ;
VAL_ 1827 NMH_ABS_NL_aktiv_6 1 "Nachlaufursache_6" ;
VAL_ 1827 NMH_ABS_NL_aktiv_7 1 "Nachlaufursache_7" ;
VAL_ 1827 NMH_ABS_NL_aktiv_8 1 "Nachlaufursache_8" ;
VAL_ 1827 NMH_ABS_TimeOut_Fehler 1 "Timeout_Fehlereintrag" ;
VAL_ 1827 NMH_ABS_CAN_Diag_deaktiv 1 "keine_CANbez_Eigendiag" ;
VAL_ 1827 NMH_ABS_KompSchutz 1 "Komponentenschutz_aktiv" ;
VAL_ 1827 NMH_ABS_Mute_Mode 1 "Mute_Mode_aktiv" ;
VAL_ 1827 NMH_ABS_Transport_Mode 1 "Transport_Mode_aktiv" ;
VAL_ 1827 NMH_ABS_Abschaltstufe_aktiv 1 "Abschaltstufe_aktiv" ;
VAL_ 1827 NMH_ABS_Eindraht_Fehler 1 "Eindrahtbetrieb_erkannt" ;
VAL_ 1838 NMH_BMS_Start_1 1 "START_v_SLEEP" ;
VAL_ 1838 NMH_BMS_Start_2 1 "START_v_PREP_TO_SLEEP" ;
VAL_ 1838 NMH_BMS_Normal_Mode_1 1 "NORMAL_MODE_v_START" ;
VAL_ 1838 NMH_BMS_Normal_Mode_2 1 "NORMAL_MODE_v_READY_TO_SLEEP" ;
VAL_ 1838 NMH_BMS_Car_WakeUp 1 "Car_WakeUp" ;
VAL_ 1838 NMH_BMS_Per_WakeUp 0 "Funktionswakeup" 1 "CAN" 2 "P_Wakeup_Ursache_unbekannt" 3 "KL_15_HW" ;
VAL_ 1838 NMH_BMS_Fkt_WakeUp 0 "Peripheriewakeup" ;
VAL_ 1838 NMH_BMS_NM_aktiv_Klemme_15 1 "Klemme_15_ein" ;
VAL_ 1838 NMH_BMS_NM_aktiv_Diagnose 1 "Diagnose_bei_Kl_15_aus" ;
VAL_ 1838 NMH_BMS_NM_aktiv_Start 1 "Mindestaktivzeit_START" ;
VAL_ 1838 NMH_BMS_NL_aktiv_4 1 "Nachlaufursache_4" ;
VAL_ 1838 NMH_BMS_NL_aktiv_5 1 "Nachlaufursache_5" ;
VAL_ 1838 NMH_BMS_NL_aktiv_6 1 "Nachlaufursache_6" ;
VAL_ 1838 NMH_BMS_NL_aktiv_7 1 "Nachlaufursache_7" ;
VAL_ 1838 NMH_BMS_NL_aktiv_8 1 "Nachlaufursache_8" ;
VAL_ 1838 NMH_BMS_NL_0 1 "EEPROM_Schreibzugriff" ;
VAL_ 1838 NMH_BMS_NL_1 1 "Luefter_aktiv" ;
VAL_ 1838 NMH_BMS_TimeOut_Fehler 1 "Timeout_Fehlereintrag" ;
VAL_ 1838 NMH_BMS_CAN_Diag_deaktiv 1 "keine_CANbez_Eigendiag" ;
VAL_ 1838 NMH_BMS_KompSchutz 1 "Komponentenschutz_aktiv" ;
VAL_ 1838 NMH_BMS_Mute_Mode 1 "Mute_Mode_aktiv" ;
VAL_ 1838 NMH_BMS_Transport_Mode 1 "Transport_Mode_aktiv" ;
VAL_ 1838 NMH_BMS_Abschaltstufe_aktiv 1 "Abschaltstufe_aktiv" ;
VAL_ 1838 NMH_BMS_Eindraht_Fehler 1 "Eindrahtbetrieb_erkannt" ;
VAL_ 1839 NMH_EM_Start_1 1 "START_v_SLEEP" ;
VAL_ 1839 NMH_EM_Start_2 1 "START_v_PREP_TO_SLEEP" ;
VAL_ 1839 NMH_EM_Normal_Mode_1 1 "NORMAL_MODE_v_START" ;
VAL_ 1839 NMH_EM_Normal_Mode_2 1 "NORMAL_MODE_v_READY_TO_SLEEP" ;
VAL_ 1839 NMH_EM_Car_WakeUp 1 "Car_WakeUp" ;
VAL_ 1839 NMH_EM_Per_WakeUp 0 "Funktionswakeup" 1 "CAN" 2 "P_Wakeup_Ursache_unbekannt" 3 "KL_15_HW" ;
VAL_ 1839 NMH_EM_Fkt_WakeUp 0 "Peripheriewakeup" ;
VAL_ 1839 NMH_EM_NM_aktiv_Klemme_15 1 "Klemme_15_ein" ;
VAL_ 1839 NMH_EM_NM_aktiv_Diagnose 1 "Diagnose_bei_Kl_15_aus" ;
VAL_ 1839 NMH_EM_NM_aktiv_Start 1 "Mindestaktivzeit_START" ;
VAL_ 1839 NMH_EM_NL_aktiv_4 1 "Nachlaufursache_4" ;
VAL_ 1839 NMH_EM_NL_aktiv_5 1 "Nachlaufursache_5" ;
VAL_ 1839 NMH_EM_NL_aktiv_6 1 "Nachlaufursache_6" ;
VAL_ 1839 NMH_EM_NL_aktiv_7 1 "Nachlaufursache_7" ;
VAL_ 1839 NMH_EM_NL_aktiv_8 1 "Nachlaufursache_8" ;
VAL_ 1839 NMH_EM_NL_0 1 "EEPROM_Schreibzugriff" ;
VAL_ 1839 NMH_EM_NL_1 1 "Kuehlpumpe_aktiv" ;
VAL_ 1839 NMH_EM_TimeOut_Fehler 1 "Timeout_Fehlereintrag" ;
VAL_ 1839 NMH_EM_CAN_Diag_deaktiv 1 "keine_CANbez_Eigendiag" ;
VAL_ 1839 NMH_EM_KompSchutz 1 "Komponentenschutz_aktiv" ;
VAL_ 1839 NMH_EM_Mute_Mode 1 "Mute_Mode_aktiv" ;
VAL_ 1839 NMH_EM_Transport_Mode 1 "Transport_Mode_aktiv" ;
VAL_ 1839 NMH_EM_Abschaltstufe_aktiv 1 "Abschaltstufe_aktiv" ;
VAL_ 1839 NMH_EM_Eindraht_Fehler 1 "Eindrahtbetrieb_erkannt" ;
VAL_ 1849 NMH_EPB_Start_1 1 "START_v_SLEEP" ;
VAL_ 1849 NMH_EPB_Start_2 1 "START_v_PREP_TO_SLEEP" ;
VAL_ 1849 NMH_EPB_Normal_Mode_1 1 "NORMAL_MODE_v_START" ;
VAL_ 1849 NMH_EPB_Normal_Mode_2 1 "NORMAL_MODE_v_READY_TO_SLEEP" ;
VAL_ 1849 NMH_EPB_Car_WakeUp 1 "Car_WakeUp" ;
VAL_ 1849 NMH_EPB_Per_WakeUp 0 "Funktionswakeup" 1 "CAN" 2 "P_Wakeup_Ursache_unbekannt" 3 "KL_15_HW" 5 "Schalter_EPB" ;
VAL_ 1849 NMH_EPB_Fkt_WakeUp 0 "Peripheriewakeup" ;
VAL_ 1849 NMH_EPB_NM_aktiv_Klemme_15 1 "Klemme_15_ein" ;
VAL_ 1849 NMH_EPB_NM_aktiv_Diagnose 1 "Diagnose_bei_Kl_15_aus" ;
VAL_ 1849 NMH_EPB_NM_aktiv_Start 1 "Mindestaktivzeit_START" ;
VAL_ 1849 NMH_EPB_NL_aktiv_4 1 "Nachlaufursache_4" ;
VAL_ 1849 NMH_EPB_NL_aktiv_5 1 "Nachlaufursache_5" ;
VAL_ 1849 NMH_EPB_NL_aktiv_6 1 "Nachlaufursache_6" ;
VAL_ 1849 NMH_EPB_NL_aktiv_7 1 "Nachlaufursache_7" ;
VAL_ 1849 NMH_EPB_NL_aktiv_8 1 "Nachlaufursache_8" ;
VAL_ 1849 NMH_EPB_TimeOut_Fehler 1 "Timeout_Fehlereintrag" ;
VAL_ 1849 NMH_EPB_CAN_Diag_deaktiv 1 "keine_CANbez_Eigendiag" ;
VAL_ 1849 NMH_EPB_KompSchutz 1 "Komponentenschutz_aktiv" ;
VAL_ 1849 NMH_EPB_Mute_Mode 1 "Mute_Mode_aktiv" ;
VAL_ 1849 NMH_EPB_Transport_Mode 1 "Transport_Mode_aktiv" ;
VAL_ 1849 NMH_EPB_Abschaltstufe_aktiv 1 "Abschaltstufe_aktiv" ;
VAL_ 1849 NMH_EPB_Eindraht_Fehler 1 "Eindrahtbetrieb_erkannt" ;
VAL_ 1824 NMH_GW_Start_1 1 "START_v_SLEEP" ;
VAL_ 1824 NMH_GW_Start_2 1 "START_v_PREP_TO_SLEEP" ;
VAL_ 1824 NMH_GW_Normal_Mode_1 1 "NORMAL_MODE_v_START" ;
VAL_ 1824 NMH_GW_Normal_Mode_2 1 "NORMAL_MODE_v_READY_TO_SLEEP" ;
VAL_ 1824 NMH_GW_Car_WakeUp 1 "Car_WakeUp" ;
VAL_ 1824 NMH_GW_Per_WakeUp 0 "Funktionswakeup" 1 "CAN" 2 "P_Wakeup_Ursache_unbekannt" 3 "KL_15_HW" 4 "ACANTransceiver" 5 "DCANTransceiver" 6 "KCANTransceiver" 7 "ICANTransceiver" 8 "ECANTransceiver" 9 "LIN1Transceiver" 10 "LIN2Transceiver" 11 "WULtg" 12 "DiagCANTransceiver" ;
VAL_ 1824 NMH_GW_Fkt_WakeUp 0 "Peripheriewakeup" 1 "ACANEvent" 2 "KBICANEvent" 3 "KCANEvent" 4 "ICANEvent" 5 "ECANEvent" 6 "LIN1Event" 7 "LIN2Event" ;
VAL_ 1824 NMH_GW_NM_aktiv_Klemme_15 1 "Klemme_15_ein" ;
VAL_ 1824 NMH_GW_NM_aktiv_Diagnose 1 "Diagnose_bei_Kl_15_aus" ;
VAL_ 1824 NMH_GW_NM_aktiv_Start 1 "Mindestaktivzeit_START" ;
VAL_ 1824 NMH_GW_NL_aktiv_4 1 "Nachlaufursache_4" ;
VAL_ 1824 NMH_GW_NL_aktiv_5 1 "Nachlaufursache_5" ;
VAL_ 1824 NMH_GW_NL_aktiv_6 1 "Nachlaufursache_6" ;
VAL_ 1824 NMH_GW_NL_aktiv_7 1 "Nachlaufursache_7" ;
VAL_ 1824 NMH_GW_NL_aktiv_8 1 "Nachlaufursache_8" ;
VAL_ 1824 NMH_GW_NL_0 1 "" ;
VAL_ 1824 NMH_GW_TimeOut_Fehler 1 "Timeout_Fehlereintrag" ;
VAL_ 1824 NMH_GW_CAN_Diag_deaktiv 1 "keine_CANbez_Eigendiag" ;
VAL_ 1824 NMH_GW_KompSchutz 1 "Komponentenschutz_aktiv" ;
VAL_ 1824 NMH_GW_Mute_Mode 1 "Mute_Mode_aktiv" ;
VAL_ 1824 NMH_GW_Transport_Mode 1 "Transport_Mode_aktiv" ;
VAL_ 1824 NMH_GW_Abschaltstufe_aktiv 1 "Abschaltstufe_aktiv" ;
VAL_ 1824 NMH_GW_Eindraht_Fehler 1 "Eindrahtbetrieb_erkannt" ;
VAL_ 1836 NMH_Ladegeraet_Start_1 1 "START_v_SLEEP" ;
VAL_ 1836 NMH_Ladegeraet_Start_2 1 "START_v_PREP_TO_SLEEP" ;
VAL_ 1836 NMH_Ladegeraet_Normal_Mode_1 1 "NORMAL_MODE_v_START" ;
VAL_ 1836 NMH_Ladegeraet_Normal_Mode_2 1 "NORMAL_MODE_v_READY_TO_SLEEP" ;
VAL_ 1836 NMH_Ladegeraet_Car_WakeUp 1 "Car_WakeUp" ;
VAL_ 1836 NMH_Ladegeraet_Per_WakeUp 0 "Funktionswakeup" 1 "CAN" 2 "P_Wakeup_Ursache_unbekannt" 3 "KL_15_HW" 4 "Taster_Sofortladen" ;
VAL_ 1836 NMH_Ladegeraet_Fkt_WakeUp 0 "Peripheriewakeup" ;
VAL_ 1836 NMH_Ladegeraet_NM_aktiv_Klemm000 1 "Klemme_15_ein" ;
VAL_ 1836 NMH_Ladegeraet_NM_aktiv_Diagnose 1 "Diagnose_bei_Kl_15_aus" ;
VAL_ 1836 NMH_Ladegeraet_NM_aktiv_Start 1 "Mindestaktivzeit_START" ;
VAL_ 1836 NMH_Ladegeraet_NL_aktiv_4 1 "Ladezeitberechnung" ;
VAL_ 1836 NMH_Ladegeraet_NL_aktiv_5 1 "Ladevorgang_aktiv" ;
VAL_ 1836 NMH_Ladegeraet_NL_aktiv_6 1 "Batterietemperierung_aktiv" ;
VAL_ 1836 NMH_Ladegeraet_NL_aktiv_7 1 "Nachlaufursache_7" ;
VAL_ 1836 NMH_Ladegeraet_NL_aktiv_8 1 "Nachlaufursache_8" ;
VAL_ 1836 NMH_Ladegeraet_TimeOut_Fehler 1 "Timeout_Fehlereintrag" ;
VAL_ 1836 NMH_Ladegeraet_CAN_Diag_deaktiv 1 "keine_CANbez_Eigendiag" ;
VAL_ 1836 NMH_Ladegeraet_KompSchutz 1 "Komponentenschutz_aktiv" ;
VAL_ 1836 NMH_Ladegeraet_Mute_Mode 1 "Mute_Mode_aktiv" ;
VAL_ 1836 NMH_Ladegeraet_Transport_Mode 1 "Transport_Mode_aktiv" ;
VAL_ 1836 NMH_Ladegeraet_Abschaltstufe_001 1 "Abschaltstufe_aktiv" ;
VAL_ 1836 NMH_Ladegeraet_Eindraht_Fehler 1 "Eindrahtbetrieb_erkannt" ;
VAL_ 1825 NMH_MO_Start_1 1 "START_v_SLEEP" ;
VAL_ 1825 NMH_MO_Start_2 1 "START_v_PREP_TO_SLEEP" ;
VAL_ 1825 NMH_MO_Normal_Mode_1 1 "NORMAL_MODE_v_START" ;
VAL_ 1825 NMH_MO_Normal_Mode_2 1 "NORMAL_MODE_v_READY_TO_SLEEP" ;
VAL_ 1825 NMH_MO_Car_WakeUp 1 "Car_WakeUp" ;
VAL_ 1825 NMH_MO_Per_WakeUp 0 "Funktionswakeup" 1 "CAN" 2 "P_Wakeup_Ursache_unbekannt" 3 "KL_15_HW" 4 "analoge_Weckleitung" 5 "Ladestecker_gesteckt" ;
VAL_ 1825 NMH_MO_Fkt_WakeUp 0 "Peripheriewakeup" ;
VAL_ 1825 NMH_MO_NM_aktiv_Klemme_15 1 "Klemme_15_ein" ;
VAL_ 1825 NMH_MO_NM_aktiv_Diagnose 1 "Diagnose_bei_Kl_15_aus" ;
VAL_ 1825 NMH_MO_NM_aktiv_Start 1 "Mindestaktivzeit_START" ;
VAL_ 1825 NMH_MO_NL_aktiv_4 1 "EKP_Vorlauf" ;
VAL_ 1825 NMH_MO_NL_aktiv_5 1 "STH_Betrieb" ;
VAL_ 1825 NMH_MO_NL_aktiv_6 1 "Abschaltung_aktiv" ;
VAL_ 1825 NMH_MO_NL_aktiv_7 1 "Innenraumklimatisierung" ;
VAL_ 1825 NMH_MO_NL_aktiv_8 1 "LM_Systemanforderung" ;
VAL_ 1825 NMH_MO_NL_1 1 "Kuehlerluefter_Strg_ZWP_aktiv" ;
VAL_ 1825 NMH_MO_NL_2 1 "Diagnosefunktionen_aktiv" ;
VAL_ 1825 NMH_MO_NL_3 1 "WFS_aktiv" ;
VAL_ 1825 NMH_MO_NL_4 1 "EEPROM_Zugriffe_RAM_ROM_Tests" ;
VAL_ 1825 NMH_MO_NL_5 1 "Sonstige_Nachlaeufe_aktiv" ;
VAL_ 1825 NMH_MO_TimeOut_Fehler 1 "Timeout_Fehlereintrag" ;
VAL_ 1825 NMH_MO_CAN_Diag_deaktiv 1 "keine_CANbez_Eigendiag" ;
VAL_ 1825 NMH_MO_KompSchutz 1 "Komponentenschutz_aktiv" ;
VAL_ 1825 NMH_MO_Mute_Mode 1 "Mute_Mode_aktiv" ;
VAL_ 1825 NMH_MO_Transport_Mode 1 "Transport_Mode_aktiv" ;
VAL_ 1825 NMH_MO_Abschaltstufe_aktiv 1 "Abschaltstufe_aktiv" ;
VAL_ 1825 NMH_MO_Eindraht_Fehler 1 "Eindrahtbetrieb_erkannt" ;
VAL_ 1523 OBD_TG_F_Status_1 0 "kein_Fehler" 1 "KS_M" 2 "KS_P" 3 "OC" 4 "OOR_P" 5 "OOR_M" 6 "RC_P" 7 "RC_M" 8 "KS_P_OC" 9 "KS_M_OC" 10 "KS_MP" 11 "KS_MP_OC" 12 "frei" 13 "frei" 14 "frei" 15 "frei" ;
VAL_ 1523 OBD_TG_F_Status_2 0 "kein_Fehler" 1 "KS_M" 2 "KS_P" 3 "OC" 4 "OOR_P" 5 "OOR_M" 6 "RC_P" 7 "RC_M" 8 "KS_P_OC" 9 "KS_M_OC" 10 "KS_MP" 11 "KS_MP_OC" 12 "frei" 13 "frei" 14 "frei" 15 "frei" ;
VAL_ 1523 OBD_TG_F_Status_3 0 "kein_Fehler" 1 "KS_M" 2 "KS_P" 3 "OC" 4 "OOR_P" 5 "OOR_M" 6 "RC_P" 7 "RC_M" 8 "KS_P_OC" 9 "KS_M_OC" 10 "KS_MP" 11 "KS_MP_OC" 12 "frei" 13 "frei" 14 "frei" 15 "frei" ;
VAL_ 1523 OBD_TG_F_Status_4 0 "kein_Fehler" 1 "KS_M" 2 "KS_P" 3 "OC" 4 "OOR_P" 5 "OOR_M" 6 "RC_P" 7 "RC_M" 8 "KS_P_OC" 9 "KS_M_OC" 10 "KS_MP" 11 "KS_MP_OC" 12 "frei" 13 "frei" 14 "frei" 15 "frei" ;
VAL_ 1175 PH_Abschaltursache 0 "keine_Sys_aktiv" 1 "Absch_Herausn_RGang" 2 "v_Absch" 3 "PDC_Taster_Absch" 4 "PLA_Absch" 5 "Kl_15_Bit_Null" 7 "Fehler" ;
VAL_ 1175 PH_Opt_Anzeige_V_ein 1 "opt_Anzeige_vorn_aktiv" ;
VAL_ 1175 PH_Opt_Anzeige_H_ein 1 "opt_Anzeige_hinten_aktiv" ;
VAL_ 1175 PH_Opt_Anz_V_Hindernis 1 "vorn_Hind_im_Warnbereich" ;
VAL_ 1175 PH_Opt_Anz_H_Hindernis 1 "hinten_Hind_im_Warnbereich" ;
VAL_ 1175 PH_Tongeber_V_aktiv 1 "Tongeber_vorne_aktiv" ;
VAL_ 1175 PH_Tongeber_H_aktiv 1 "Tongeber_hinten_aktiv" ;
VAL_ 1175 PH_Tongeber_mute 1 "Tongeber_stumm" ;
VAL_ 1175 PH_Anf_Audioabsenkung 1 "Anf_Audioabsenkung" ;
VAL_ 1175 PH_Anf_Verdeck 0 "Verdeckbetrieb_freigegeben" 1 "Verdeckbetrieb_sperren" 2 "reserviert" 3 "reserviert" ;
VAL_ 1175 PH_StartStopp_Info 0 "Motorlauf_nicht_notwendig_(Stoppfreigabe)" 1 "Motoranlauf_nicht_zwingend_notwendig_(Stoppverbot,keine_Startanforderung)" 2 "Motoranlauf_zwingend_notwendig_(Startanforderung)" 3 "Systemfehler" ;
VAL_ 1175 PH_BerErk_vorn 0 "Init" 1 "Vorwarnbereich_nur_NFZ" 2 "Hauptwarnbereich" 3 "Kollisionsbereich" ;
VAL_ 1175 PH_BerErk_hinten 0 "Init" 1 "Vorwarnbereich_nur_NFZ" 2 "Hauptwarnbereich" 3 "Kollisionsbereich" ;
VAL_ 1175 PH_defekt 1 "PH_wg_Defekt_deaktiv" ;
VAL_ 1175 PH_gestoert 1 "PH_wg_Stoerung_temp_deaktiv" ;
VAL_ 1175 PH_Systemzustand 0 "Anlage_aus" 1 "Anlage_wg_RGang_akt" 2 "Anlage_man_akt" 3 "Anlage_auto_akt" 7 "Fehler_gestoert" ;
VAL_ 1175 PH_Display_Kundenwunsch 0 "Anzeige_aus" 1 "Graphik" 2 "Rear_View" 3 "automatisch" ;
VAL_ 1175 PH_KD_Fehler 0 "kein_Fehlerspeichereintrag" 1 "Fehlerspeichereintrag" ;
